VERSION ""

NS_ :

BS_:

BU_: IVI_IF IC HUD MFW ECALL ALC VAP EPA GW_IF

BO_ 3221225472 VECTOR__INDEPENDENT_SIG_MSG: 0 Vector__XXX
 SG_ vcu_VehicleMode : 0|2@1+ (1,0) [0|3] "" Vector__XXX

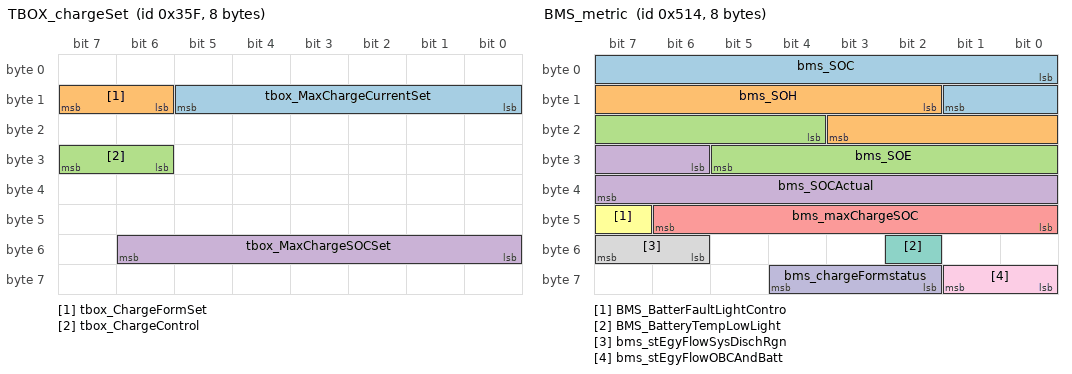
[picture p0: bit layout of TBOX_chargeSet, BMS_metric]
BO_ 863 TBOX_chargeSet: 8 IVI_IF
 SG_ tbox_MaxChargeCurrentSet : 8|6@1+ (1,5) [5|67] "A"  GW_IF
 SG_ tbox_ChargeFormSet : 14|2@1+ (1,0) [0|3] ""  GW_IF
 SG_ tbox_ChargeControl : 30|2@1+ (1,0) [0|3] ""  GW_IF
 SG_ tbox_MaxChargeSOCSet : 48|7@1+ (1,0) [0|100] "%"  GW_IF

BO_ 1300 BMS_metric: 8 GW_IF
 SG_ bms_SOC : 0|10@1+ (0.1,0) [0|100] "%"  IVI_IF
 SG_ bms_SOH : 10|10@1+ (0.1,0) [0|100] "%"  IVI_IF
 SG_ bms_SOE : 20|10@1+ (0.1,0) [0|100] "%"  IVI_IF
 SG_ bms_SOCActual : 30|10@1+ (0.1,0) [0|100] "%"  IVI_IF
 SG_ bms_maxChargeSOC : 40|7@1+ (1,0) [0|100] ""  IVI_IF
 SG_ BMS_BatterFaultLightContro : 47|1@1+ (1,0) [0|1] ""  IVI_IF
 SG_ BMS_BatteryTempLowLight : 50|1@1+ (1,0) [0|1] ""  IVI_IF
 SG_ bms_stEgyFlowSysDischRgn : 54|2@1+ (1,0) [0|3] ""  IVI_IF
 SG_ bms_stEgyFlowOBCAndBatt : 56|2@1+ (1,0) [0|3] ""  IVI_IF
 SG_ bms_chargeFormstatus : 58|3@1+ (1,0) [0|7] ""  IVI_IF

BO_ 1396 BMS_tboxRequest: 8 GW_IF
 SG_ bms_remainChargeTime : 43|12@1+ (1,0) [0|4095] ""  IVI_IF
 SG_ bms_ChgAmount : 55|9@1+ (0.2,0) [0|102.2] "kWh"  IVI_IF

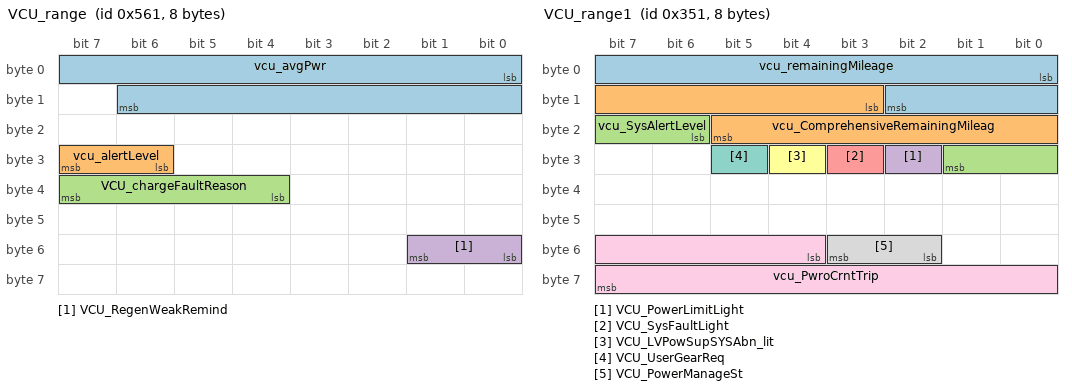
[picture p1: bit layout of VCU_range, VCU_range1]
BO_ 1377 VCU_range: 8 GW_IF
 SG_ vcu_avgPwr : 0|15@1+ (0.01,-100) [-100|100] "KWh/100km"  IVI_IF
 SG_ vcu_alertLevel : 30|2@1+ (1,0) [0|3] ""  IVI_IF
 SG_ VCU_chargeFaultReason : 36|4@1+ (1,0) [0|15] ""  IVI_IF
 SG_ VCU_RegenWeakRemind : 48|2@1+ (1,0) [0|3] ""  IVI_IF

BO_ 849 VCU_range1: 8 GW_IF
 SG_ vcu_remainingMileage : 0|11@1+ (1,0) [0|2047] "km"  IVI_IF
 SG_ vcu_ComprehensiveRemainingMileag : 11|11@1+ (1,0) [0|2047] "km"  IVI_IF
 SG_ vcu_SysAlertLevel : 22|4@1+ (1,0) [0|15] ""  IVI_IF
 SG_ VCU_PowerLimitLight : 26|1@1+ (1,0) [0|1] ""  IVI_IF
 SG_ VCU_SysFaultLight : 27|1@1+ (1,0) [0|1] ""  IVI_IF
 SG_ VCU_LVPowSupSYSAbn_lit : 28|1@1+ (1,0) [0|1] ""  IVI_IF
 SG_ VCU_UserGearReq : 29|1@1+ (1,0) [0|1] ""  IVI_IF
 SG_ VCU_PowerManageSt : 50|2@1+ (1,0) [0|3] ""  IVI_IF
 SG_ vcu_PwroCrntTrip : 52|12@1+ (0.1,-50) [-50|359.5] "kWh"  IVI_IF

BO_ 273 VCU_state: 8 GW_IF
 SG_ vcu_accelPos : 20|10@1+ (0.1,0) [0|100] "%"  IVI_IF,EPA
 SG_ vcu_BrakeWarning : 39|1@1+ (1,0) [0|1] ""  IVI_IF

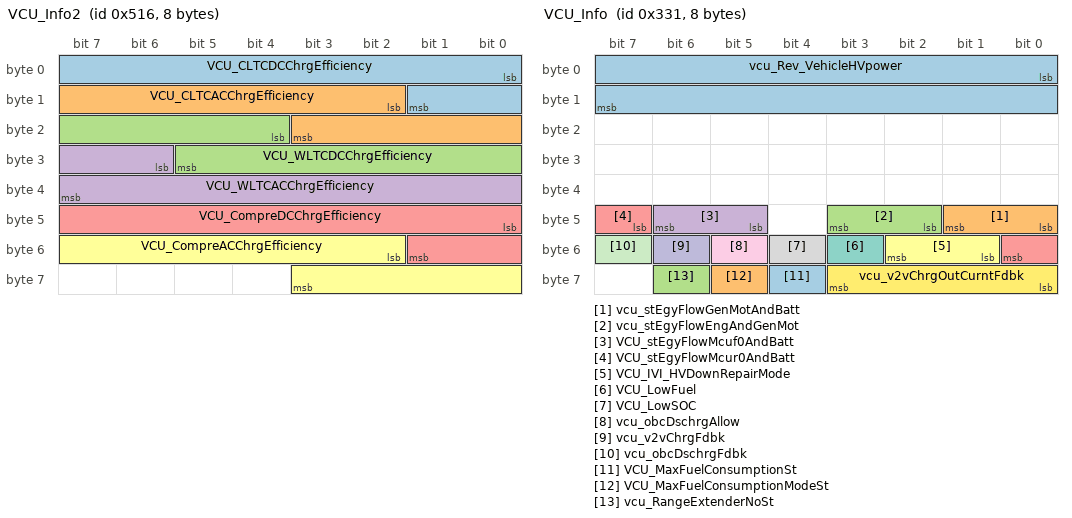
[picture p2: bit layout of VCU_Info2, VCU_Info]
BO_ 1302 VCU_Info2: 8 GW_IF
 SG_ VCU_CLTCDCChrgEfficiency : 0|10@1+ (0.1,0) [0|102.3] "km/min"  IVI_IF
 SG_ VCU_CLTCACChrgEfficiency : 10|10@1+ (0.1,0) [0|102.3] "km/h"  IVI_IF
 SG_ VCU_WLTCDCChrgEfficiency : 20|10@1+ (0.1,0) [0|102.3] "km/min"  IVI_IF
 SG_ VCU_WLTCACChrgEfficiency : 30|10@1+ (0.1,0) [0|102.3] "km/h"  IVI_IF
 SG_ VCU_CompreDCChrgEfficiency : 40|10@1+ (0.1,0) [0|102.3] "km/min"  IVI_IF
 SG_ VCU_CompreACChrgEfficiency : 50|10@1+ (0.1,0) [0|102.3] "km/h"  IVI_IF

BO_ 903 OBC_state: 8 GW_IF
 SG_ obc_state : 8|4@1+ (1,0) [0|15] ""  IVI_IF
 SG_ obc_batteryConnectStatus_ : 13|1@1+ (1,0) [0|1] ""  IVI_IF
 SG_ obc_CcResistance : 14|4@1+ (1,0) [0|15] ""  IVI_IF

BO_ 909 DCDC_state: 8 GW_IF
 SG_ dcdc_systemStatus : 8|4@1+ (1,0) [0|15] ""  IVI_IF
 SG_ dcdc_deratingStatus : 12|1@1+ (1,0) [0|1] ""  IVI_IF
 SG_ dcdc_realOutputCurrent : 32|12@1+ (0.1,0) [0|409.5] "A"  IVI_IF

BO_ 777 GSM_state: 8 GW_IF
 SG_ gsm_NoticeReq : 0|1@1+ (1,0) [0|1] ""  IVI_IF
 SG_ gsm_gearSelectorPos : 1|3@1+ (1,0) [0|7] ""  IVI_IF

BO_ 906 GTW_mcur0_mcuf0_info: 8 GW_IF
 SG_ mcuf0_torqueEst : 12|12@1- (0.8,0) [-1300|1300] "Nm"  IVI_IF
 SG_ mcur0_torqueEst : 0|12@1- (0.8,0) [-1300|1300] "Nm"  IVI_IF

BO_ 772 BMS_temperature: 8 GW_IF
 SG_ bms_packTempMax : 0|9@1+ (0.5,-40) [-40|125] "℃"  IVI_IF
 SG_ bms_packTempMin : 9|9@1+ (0.5,-40) [-40|125] "℃"  IVI_IF
 SG_ bms_packTempAvg : 18|9@1+ (0.5,-40) [-40|125] "℃"  IVI_IF

BO_ 817 VCU_Info: 8 GW_IF
 SG_ vcu_Rev_VehicleHVpower : 0|16@1+ (1,0) [0|20000] ""  IVI_IF
 SG_ vcu_stEgyFlowGenMotAndBatt : 40|2@1+ (1,0) [0|3] ""  IVI_IF
 SG_ vcu_stEgyFlowEngAndGenMot : 42|2@1+ (1,0) [0|3] ""  IVI_IF
 SG_ VCU_stEgyFlowMcuf0AndBatt : 45|2@1+ (1,0) [0|3] ""  IVI_IF
 SG_ VCU_stEgyFlowMcur0AndBatt : 47|2@1+ (1,0) [0|3] ""  IVI_IF
 SG_ VCU_IVI_HVDownRepairMode : 49|2@1+ (1,0) [0|3] ""  IVI_IF
 SG_ VCU_LowFuel : 51|1@1+ (1,0) [0|1] ""  IVI_IF
 SG_ VCU_LowSOC : 52|1@1+ (1,0) [0|1] ""  IVI_IF
 SG_ vcu_obcDschrgAllow : 53|1@1+ (1,0) [0|1] ""  IVI_IF
 SG_ vcu_v2vChrgFdbk : 54|1@1+ (1,0) [0|1] ""  IVI_IF
 SG_ vcu_obcDschrgFdbk : 55|1@1+ (1,0) [0|1] ""  IVI_IF
 SG_ vcu_v2vChrgOutCurntFdbk : 56|4@1+ (1,0) [0|15] "A"  IVI_IF
 SG_ VCU_MaxFuelConsumptionSt : 60|1@1+ (1,0) [0|1] ""  IVI_IF
 SG_ VCU_MaxFuelConsumptionModeSt : 61|1@1+ (1,0) [0|1] ""  IVI_IF
 SG_ vcu_RangeExtenderNoSt : 62|1@1+ (1,0) [0|1] ""  IVI_IF

BO_ 2015 Diag_FuncReq: 8 GW_IF
 SG_ Diag_FuncReq_Data : 0|64@1+ (1,0) [0|0] "N/A"  IVI_IF,IC,HUD,MFW,ECALL,ALC,EPA

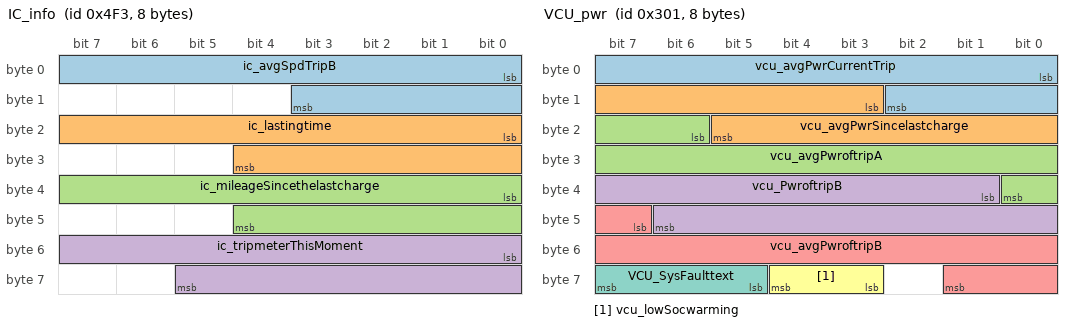
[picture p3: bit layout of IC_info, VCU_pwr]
BO_ 1267 IC_info: 8 IVI_IF
 SG_ ic_avgSpdTripB : 0|12@1+ (0.1,0) [0|280] "KPH"  GW_IF
 SG_ ic_lastingtime : 16|13@1+ (1,0) [0|4320] "min"  GW_IF
 SG_ ic_mileageSincethelastcharge : 32|13@1+ (0.1,0) [0|800] "km"  GW_IF
 SG_ ic_tripmeterThisMoment : 48|14@1+ (0.1,0) [0|1500] "km"  GW_IF

BO_ 769 VCU_pwr: 8 GW_IF
 SG_ vcu_avgPwrCurrentTrip : 0|11@1+ (0.1,-50) [-50|154.7] "kWh/100km"  IVI_IF
 SG_ vcu_avgPwrSincelastcharge : 11|11@1+ (0.1,-50) [-50|154.7] "kWh/100km"  IVI_IF
 SG_ vcu_avgPwroftripA : 22|11@1+ (0.1,-50) [-50|154.7] "kWh/100km"  IVI_IF
 SG_ vcu_PwroftripB : 33|14@1+ (0.1,-500) [-500|1000] "kWh"  IVI_IF
 SG_ vcu_avgPwroftripB : 47|11@1+ (0.1,-50) [-50|154.7] "kWh/100km"  IVI_IF
 SG_ vcu_lowSocwarming : 59|2@1+ (1,0) [0|3] ""  IVI_IF
 SG_ VCU_SysFaulttext : 61|3@1+ (1,0) [0|7] ""  IVI_IF

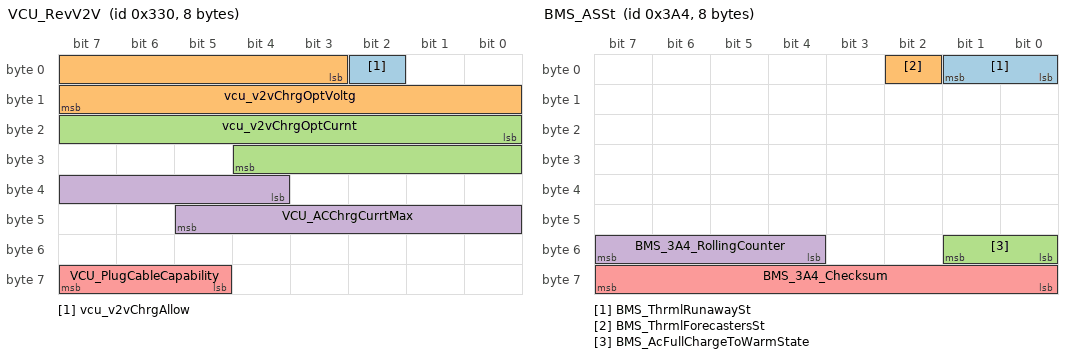
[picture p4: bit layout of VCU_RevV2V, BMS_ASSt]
BO_ 816 VCU_RevV2V: 8 GW_IF
 SG_ vcu_v2vChrgAllow : 2|1@1+ (1,0) [0|1] ""  IVI_IF
 SG_ vcu_v2vChrgOptVoltg : 3|13@1+ (0.1,0) [0|800] "V"  IVI_IF
 SG_ vcu_v2vChrgOptCurnt : 16|13@1+ (0.1,-400) [-400|400] "A"  IVI_IF
 SG_ VCU_ACChrgCurrtMax : 36|10@1+ (0.1,0) [0|63] "A"  IVI_IF
 SG_ VCU_PlugCableCapability : 61|3@1+ (1,0) [0|7] ""  IVI_IF

BO_ 932 BMS_ASSt: 8 GW_IF
 SG_ BMS_ThrmlRunawaySt : 0|2@1+ (1,0) [0|3] ""  IVI_IF,IC
 SG_ BMS_ThrmlForecastersSt : 2|1@1+ (1,0) [0|3] ""  IVI_IF
 SG_ BMS_AcFullChargeToWarmState : 48|2@1+ (1,0) [0|3] ""  IVI_IF
 SG_ BMS_3A4_RollingCounter : 52|4@1+ (1,0) [0|15] ""  IVI_IF
 SG_ BMS_3A4_Checksum : 56|8@1+ (1,0) [0|255] ""  IVI_IF

BO_ 929 VCU_stateCha1: 8 GW_IF
 SG_ vcu_driveMode : 0|3@1+ (1,0) [0|7] ""  IVI_IF,HUD,ALC
 SG_ vcu_VehicleMode : 3|3@1+ (1,0) [0|7] ""  IVI_IF
 SG_ VCU_PercentInstantaneousPower : 9|8@1+ (1,-100) [-100|100] ""  IVI_IF,EPA
 SG_ Vcu_ParkingChargeFB : 23|1@1+ (1,0) [0|1] ""  IVI_IF
 SG_ Vcu_ParkingChargeModFB : 24|2@1+ (1,0) [0|3] ""  IVI_IF
 SG_ vcu_towMode : 26|2@1+ (1,0) [0|3] ""  IVI_IF
 SG_ vcu_ready : 28|1@1+ (1,0) [0|1] ""  IVI_IF
 SG_ vcu_traveModeSts : 29|2@1+ (1,0) [0|3] ""  IVI_IF
 SG_ vcu_highVoltagefaultSts : 31|1@1+ (1,0) [0|1] ""  IVI_IF
 SG_ VCU_VehicleRepairModeFB : 32|2@1+ (1,0) [0|3] ""  IVI_IF
 SG_ VCU_VehicleModeSetReq : 34|3@1+ (1,0) [0|7] ""  IVI_IF
 SG_ VCU_VehicleModeLOWTempReq : 37|2@1+ (1,0) [0|3] ""  IVI_IF
 SG_ VCU_RangeExtenderSt : 40|2@1+ (1,0) [0|3] ""  IVI_IF
 SG_ vcu_highVoltageSuccess : 42|3@1+ (1,0) [0|7] ""  IVI_IF,MFW
 SG_ vcu_hvOnMode : 48|2@1+ (1,0) [0|3] ""  IVI_IF
 SG_ vcu_RegenModeStatus : 52|2@1+ (1,0) [0|3] ""  IVI_IF
 SG_ vcu_memoryStatus : 55|1@1+ (1,0) [0|1] ""  IVI_IF
 SG_ VCU_Eng_SelfShieldStart : 56|1@1+ (1,0) [0|1] ""  IVI_IF
 SG_ VCU_ExhibitionRequest : 57|1@1+ (1,0) [0|1] ""  IVI_IF
 SG_ vcu_ExhibitionMode : 61|2@1+ (1,0) [0|3] ""  IVI_IF,MFW

BO_ 292 EPS_state: 8 GW_IF
 SG_ eps_warningLamp : 20|1@1+ (1,0) [0|1] ""  IVI_IF,IC
 SG_ eps_rollingCounter : 52|4@1+ (1,0) [0|15] ""  IVI_IF
 SG_ eps_checksum : 56|8@1+ (1,0) [0|255] ""  IVI_IF

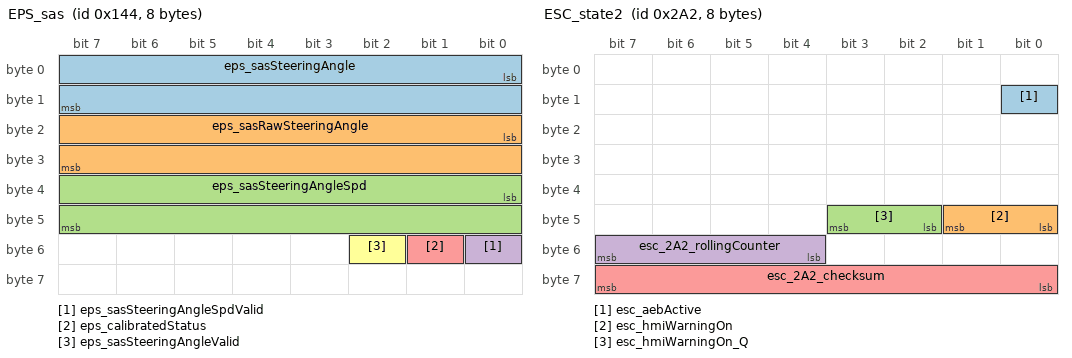
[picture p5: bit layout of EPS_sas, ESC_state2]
BO_ 324 EPS_sas: 8 GW_IF
 SG_ eps_sasSteeringAngle : 0|16@1+ (0.1,-780) [-780|779.9] "deg"  IVI_IF
 SG_ eps_sasRawSteeringAngle : 16|16@1+ (0.1,-780) [-780|779.9] "deg"  IVI_IF
 SG_ eps_sasSteeringAngleSpd : 32|16@1+ (0.1,-1300) [-1300|1300] "deg/s"  IVI_IF
 SG_ eps_sasSteeringAngleSpdValid : 48|1@1+ (1,0) [0|1] ""  IVI_IF
 SG_ eps_calibratedStatus : 49|1@1+ (1,0) [0|1] ""  IVI_IF
 SG_ eps_sasSteeringAngleValid : 50|1@1+ (1,0) [0|1] ""  IVI_IF

BO_ 322 ESC_wheelSpd_Front: 8 GW_IF
 SG_ esc_wheelSpeedFL : 0|13@1+ (0.05625,0) [0|270] "km/h"  IVI_IF
 SG_ esc_wheelSpeedFLValid : 13|1@1+ (1,0) [0|1] ""  IVI_IF
 SG_ esc_wheelSpeedFR : 16|13@1+ (0.05625,0) [0|270] "km/h"  IVI_IF
 SG_ esc_wheelSpeedFRValid : 29|1@1+ (1,0) [0|1] ""  IVI_IF

BO_ 290 ESC_wheelSpd_Rear: 8 GW_IF
 SG_ esc_wheelSpeedRL : 0|13@1+ (0.05625,0) [0|270] "km/h"  IVI_IF
 SG_ esc_wheelSpeedRLValid : 13|1@1+ (1,0) [0|1] ""  IVI_IF
 SG_ esc_wheelSpeedRR : 16|13@1+ (0.05625,0) [0|270] "km/h"  IVI_IF
 SG_ esc_wheelSpeedRRValid : 29|1@1+ (1,0) [0|1] ""  IVI_IF

BO_ 530 ESC_state1: 8 GW_IF
 SG_ esc_vehicleSpeed : 0|13@1+ (0.05625,0) [0|270] "km/h"  IVI_IF
 SG_ esc_vehicleSpeedValid : 13|1@1+ (1,0) [0|1] ""  IVI_IF
 SG_ esc_absFault : 14|1@1+ (1,0) [0|1] ""  IVI_IF,IC
 SG_ esc_absActive : 15|1@1+ (1,0) [0|1] ""  IVI_IF
 SG_ esc_escActive : 17|1@1+ (1,0) [0|1] ""  IVI_IF
 SG_ esc_tcsActive : 18|1@1+ (1,0) [0|1] ""  IVI_IF
 SG_ esc_avhActive : 22|1@1+ (1,0) [0|1] ""  IVI_IF
 SG_ esc_avhStandby : 23|1@1+ (1,0) [0|1] ""  IVI_IF
 SG_ esc_avhAvailable : 24|1@1+ (1,0) [0|1] ""  IVI_IF
 SG_ esc_cdpActive : 25|1@1+ (1,0) [0|1] ""  IVI_IF
 SG_ esc_hdcStatus : 27|2@1+ (1,0) [0|3] ""  IVI_IF
 SG_ esc_hdcAvailable : 29|1@1+ (1,0) [0|1] ""  IVI_IF
 SG_ esc_hhcAvailable : 31|1@1+ (1,0) [0|1] ""  IVI_IF
 SG_ esc_ebdFault : 46|1@1+ (1,0) [0|1] ""  IVI_IF,IC
 SG_ esc_offStatus : 47|1@1+ (1,0) [0|1] ""  IVI_IF,IC
 SG_ esc_escFault : 48|1@1+ (1,0) [0|1] ""  IVI_IF,IC
 SG_ esc_emergencyBrakeSts : 49|1@1+ (1,0) [0|1] ""  IVI_IF
 SG_ esc_212_rollingCounter : 52|4@1+ (1,0) [0|15] ""  IVI_IF
 SG_ esc_212_checksum : 56|8@1+ (1,0) [0|255] ""  IVI_IF

BO_ 674 ESC_state2: 8 GW_IF
 SG_ esc_aebActive : 8|1@1+ (1,0) [0|1] ""  IVI_IF
 SG_ esc_hmiWarningOn : 40|2@1+ (1,0) [0|3] ""  IVI_IF
 SG_ esc_hmiWarningOn_Q : 42|2@1+ (1,0) [0|3] ""  IVI_IF
 SG_ esc_2A2_rollingCounter : 52|4@1+ (1,0) [0|15] ""  IVI_IF
 SG_ esc_2A2_checksum : 56|8@1+ (1,0) [0|255] ""  IVI_IF

BO_ 594 ESC_yawState: 8 GW_IF
 SG_ esc_longAcceleration : 0|13@1+ (0.01,-21) [-21|21] "m/s2"  IVI_IF
 SG_ esc_longAccelerationValid : 13|1@1+ (1,0) [0|1] ""  IVI_IF
 SG_ esc_yawRateValid : 15|1@1+ (1,0) [0|1] ""  IVI_IF
 SG_ esc_yawRate : 32|16@1+ (0.005,-163.84) [-163.84|163.835] "degree/s"  IVI_IF

BO_ 1019 GW_ESC_yawState: 8 GW_IF
 SG_ apa_funcSts : 55|3@1+ (1,0) [0|7] ""  IVI_IF

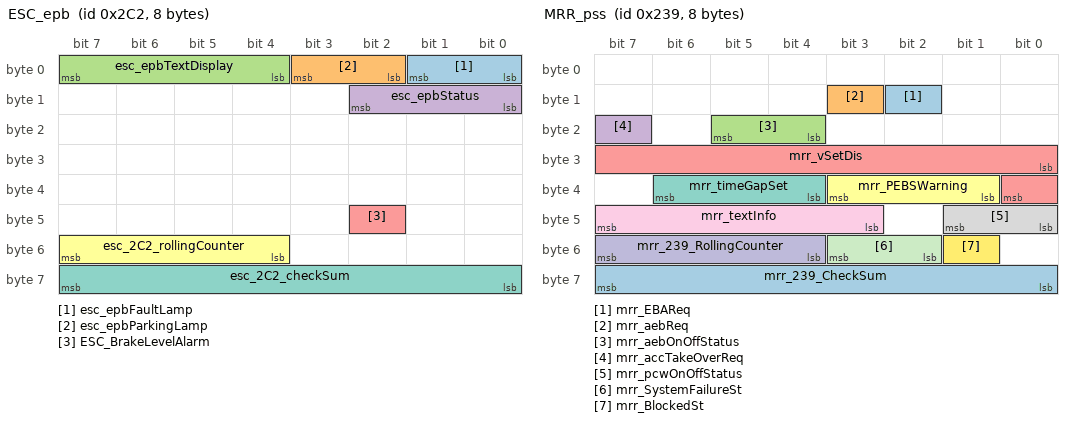
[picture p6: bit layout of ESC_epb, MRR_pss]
BO_ 706 ESC_epb: 8 GW_IF
 SG_ esc_epbFaultLamp : 0|2@1+ (1,0) [0|3] ""  IVI_IF,IC
 SG_ esc_epbParkingLamp : 2|2@1+ (1,0) [0|3] ""  IVI_IF,IC
 SG_ esc_epbTextDisplay : 4|4@1+ (1,0) [0|15] ""  IVI_IF
 SG_ esc_epbStatus : 8|3@1+ (1,0) [0|7] ""  IVI_IF
 SG_ ESC_BrakeLevelAlarm : 42|1@1+ (1,0) [0|1] ""  IVI_IF,IC
 SG_ esc_2C2_rollingCounter : 52|4@1+ (1,0) [0|15] ""  IVI_IF
 SG_ esc_2C2_checkSum : 56|8@1+ (1,0) [0|255] "N/A"  IVI_IF

BO_ 537 MRR_acc: 8 GW_IF
 SG_ mrr_accMode : 45|3@1+ (1,0) [0|7] ""  IVI_IF,HUD
 SG_ mrr_219_RollingCounter : 52|4@1+ (1,0) [0|15] ""  IVI_IF
 SG_ mrr_219_CheckSum : 56|8@1+ (1,0) [0|255] "N/A"  IVI_IF

BO_ 569 MRR_pss: 8 GW_IF
 SG_ mrr_EBAReq : 10|1@1+ (1,0) [0|1] ""  IVI_IF
 SG_ mrr_aebReq : 11|1@1+ (1,0) [0|1] ""  IVI_IF,HUD
 SG_ mrr_aebOnOffStatus : 20|2@1+ (1,0) [0|3] ""  IVI_IF
 SG_ mrr_accTakeOverReq : 23|1@1+ (1,0) [0|1] ""  IVI_IF,IC,HUD,ALC
 SG_ mrr_vSetDis : 24|9@1+ (0.5,0) [0|255.5] "KPH"  IVI_IF,HUD
 SG_ mrr_PEBSWarning : 33|3@1+ (1,0) [0|7] ""  IVI_IF,HUD,ALC
 SG_ mrr_timeGapSet : 36|3@1+ (1,0) [0|7] ""  IVI_IF,HUD
 SG_ mrr_pcwOnOffStatus : 40|2@1+ (1,0) [0|3] ""  IVI_IF
 SG_ mrr_textInfo : 43|5@1+ (1,0) [0|15] ""  IVI_IF
 SG_ mrr_239_RollingCounter : 52|4@1+ (1,0) [0|15] ""  IVI_IF
 SG_ mrr_SystemFailureSt : 50|2@1+ (1,0) [0|3] ""  IVI_IF
 SG_ mrr_BlockedSt : 49|1@1+ (1,0) [0|1] ""  IVI_IF
 SG_ mrr_239_CheckSum : 56|8@1+ (1,0) [0|255] "N/A"  IVI_IF

BO_ 841 MRR_hmi1: 8 GW_IF
 SG_ mrr_ACC_TargetType : 0|3@1+ (1,0) [0|7] ""  IVI_IF,HUD
 SG_ mrr_ACC_TargetDetection : 4|3@1+ (1,0) [0|7] ""  IVI_IF,HUD
 SG_ mrr_ACC_TargetRange : 7|9@1+ (0.5,0) [0|250] "m"  IVI_IF
 SG_ mrr_ACC_RelevantTargetLatRange : 16|10@1+ (0.1,-50) [-50|50] "m"  IVI_IF

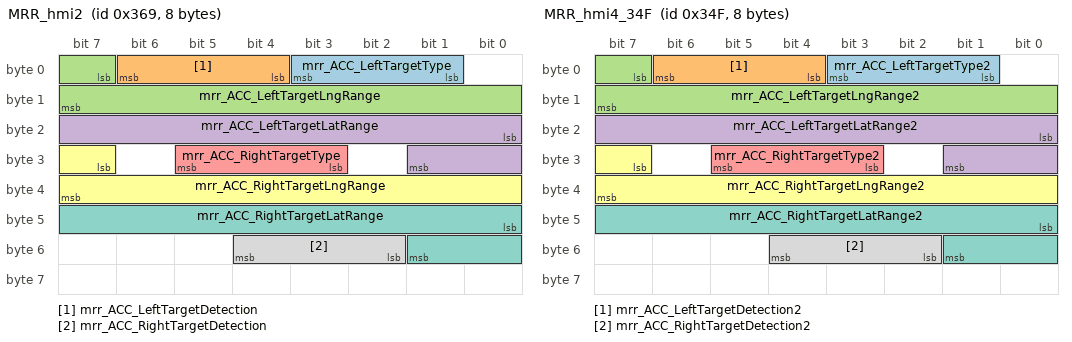
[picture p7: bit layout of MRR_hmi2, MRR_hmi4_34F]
BO_ 873 MRR_hmi2: 8 GW_IF
 SG_ mrr_ACC_LeftTargetType : 1|3@1+ (1,0) [0|7] ""  IVI_IF
 SG_ mrr_ACC_LeftTargetDetection : 4|3@1+ (1,0) [0|7] ""  IVI_IF
 SG_ mrr_ACC_LeftTargetLngRange : 7|9@1+ (0.5,0) [0|250] "m"  IVI_IF
 SG_ mrr_ACC_LeftTargetLatRange : 16|10@1+ (0.1,-50) [-50|50] "m"  IVI_IF
 SG_ mrr_ACC_RightTargetType : 27|3@1+ (1,0) [0|7] ""  IVI_IF
 SG_ mrr_ACC_RightTargetLngRange : 31|9@1+ (0.5,0) [0|250] "m"  IVI_IF
 SG_ mrr_ACC_RightTargetLatRange : 40|10@1+ (0.1,-50) [-50|50] "m"  IVI_IF
 SG_ mrr_ACC_RightTargetDetection : 50|3@1+ (1,0) [0|7] ""  IVI_IF

BO_ 846 MRR_hmi3_34E: 8 GW_IF
 SG_ mrr_ACC_TargetType2 : 0|3@1+ (1,0) [0|7] ""  IVI_IF
 SG_ mrr_ACC_TargetDetection2 : 3|3@1+ (1,0) [0|7] ""  IVI_IF
 SG_ mrr_ACC_TargetRange2 : 7|9@1+ (0.5,0) [0|250] "m"  IVI_IF
 SG_ mrr_ACC_RelevantTargetLatRange2 : 16|10@1+ (0.1,-50) [-50|50] "m"  IVI_IF

BO_ 847 MRR_hmi4_34F: 8 GW_IF
 SG_ mrr_ACC_LeftTargetType2 : 1|3@1+ (1,0) [0|7] ""  IVI_IF
 SG_ mrr_ACC_LeftTargetDetection2 : 4|3@1+ (1,0) [0|7] ""  IVI_IF
 SG_ mrr_ACC_LeftTargetLngRange2 : 7|9@1+ (0.5,0) [0|250] "m"  IVI_IF
 SG_ mrr_ACC_LeftTargetLatRange2 : 16|10@1+ (0.1,-50) [-50|50] "m"  IVI_IF
 SG_ mrr_ACC_RightTargetType2 : 27|3@1+ (1,0) [0|7] ""  IVI_IF
 SG_ mrr_ACC_RightTargetLngRange2 : 31|9@1+ (0.5,0) [0|250] "m"  IVI_IF
 SG_ mrr_ACC_RightTargetLatRange2 : 40|10@1+ (0.1,-50) [-50|50] "m"  IVI_IF
 SG_ mrr_ACC_RightTargetDetection2 : 50|3@1+ (1,0) [0|7] ""  IVI_IF

BO_ 853 MRR_hmi5_355: 8 GW_IF
 SG_ mrr_ACC_TargetType3 : 0|3@1+ (1,0) [0|7] ""  IVI_IF,HUD
 SG_ mrr_ACC_TargetDetection3 : 3|3@1+ (1,0) [0|7] ""  IVI_IF,HUD
 SG_ mrr_ACC_TargetRange3 : 7|9@1+ (0.5,0) [0|250] "m"  IVI_IF
 SG_ mrr_ACC_RelevantTargetLatRange3 : 16|10@1+ (0.1,-50) [-50|50] "m"  IVI_IF

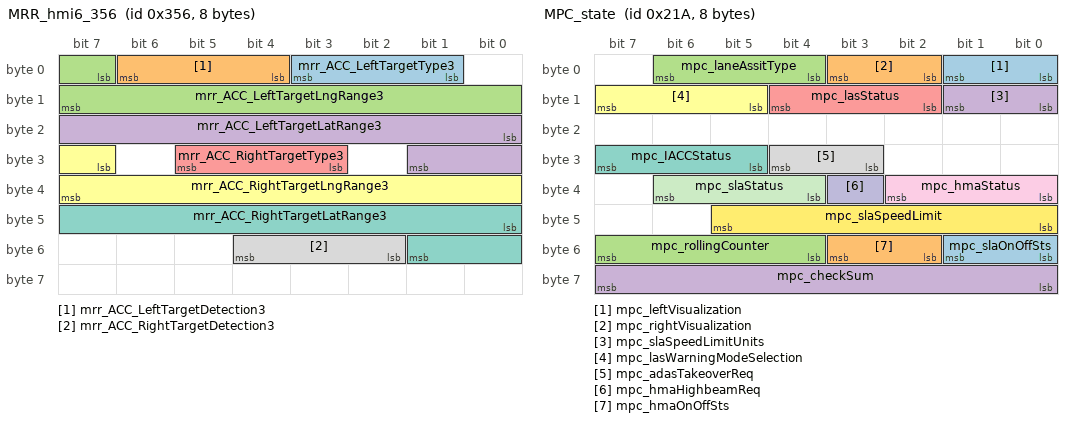
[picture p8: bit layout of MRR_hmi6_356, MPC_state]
BO_ 854 MRR_hmi6_356: 8 GW_IF
 SG_ mrr_ACC_LeftTargetType3 : 1|3@1+ (1,0) [0|7] ""  IVI_IF
 SG_ mrr_ACC_LeftTargetDetection3 : 4|3@1+ (1,0) [0|7] ""  IVI_IF
 SG_ mrr_ACC_LeftTargetLngRange3 : 7|9@1+ (0.5,0) [0|250] "m"  IVI_IF
 SG_ mrr_ACC_LeftTargetLatRange3 : 16|10@1+ (0.1,-50) [-50|50] "m"  IVI_IF
 SG_ mrr_ACC_RightTargetType3 : 27|3@1+ (1,0) [0|7] ""  IVI_IF
 SG_ mrr_ACC_RightTargetLngRange3 : 31|9@1+ (0.5,0) [0|250] "m"  IVI_IF
 SG_ mrr_ACC_RightTargetLatRange3 : 40|10@1+ (0.1,-50) [-50|50] "m"  IVI_IF
 SG_ mrr_ACC_RightTargetDetection3 : 50|3@1+ (1,0) [0|7] ""  IVI_IF

BO_ 538 MPC_state: 8 GW_IF
 SG_ mpc_leftVisualization : 0|2@1+ (1,0) [0|3] ""  IVI_IF,HUD
 SG_ mpc_rightVisualization : 2|2@1+ (1,0) [0|3] ""  IVI_IF,HUD
 SG_ mpc_laneAssitType : 4|3@1+ (1,0) [0|7] ""  IVI_IF,HUD
 SG_ mpc_slaSpeedLimitUnits : 8|2@1+ (1,0) [0|3] ""  IVI_IF
 SG_ mpc_lasStatus : 10|3@1+ (1,0) [0|7] ""  IVI_IF,HUD
 SG_ mpc_lasWarningModeSelection : 13|3@1+ (1,0) [0|7] ""  IVI_IF
 SG_ mpc_IACCStatus : 29|3@1+ (1,0) [0|7] ""  IVI_IF,HUD
 SG_ mpc_adasTakeoverReq : 27|2@1+ (1,0) [0|3] ""  IVI_IF,IC,HUD,ALC
 SG_ mpc_hmaStatus : 32|3@1+ (1,0) [0|7] ""  IVI_IF
 SG_ mpc_hmaHighbeamReq : 35|1@1+ (1,0) [0|1] ""  IVI_IF
 SG_ mpc_slaStatus : 36|3@1+ (1,0) [0|7] ""  IVI_IF
 SG_ mpc_slaSpeedLimit : 40|6@1+ (5,0) [0|315] ""  IVI_IF,HUD
 SG_ mpc_slaOnOffSts : 48|2@1+ (1,0) [0|3] ""  IVI_IF
 SG_ mpc_hmaOnOffSts : 50|2@1+ (1,0) [0|3] ""  IVI_IF
 SG_ mpc_rollingCounter : 52|4@1+ (1,0) [0|15] ""  IVI_IF
 SG_ mpc_checkSum : 56|8@1+ (1,0) [0|255] "N/A"  IVI_IF

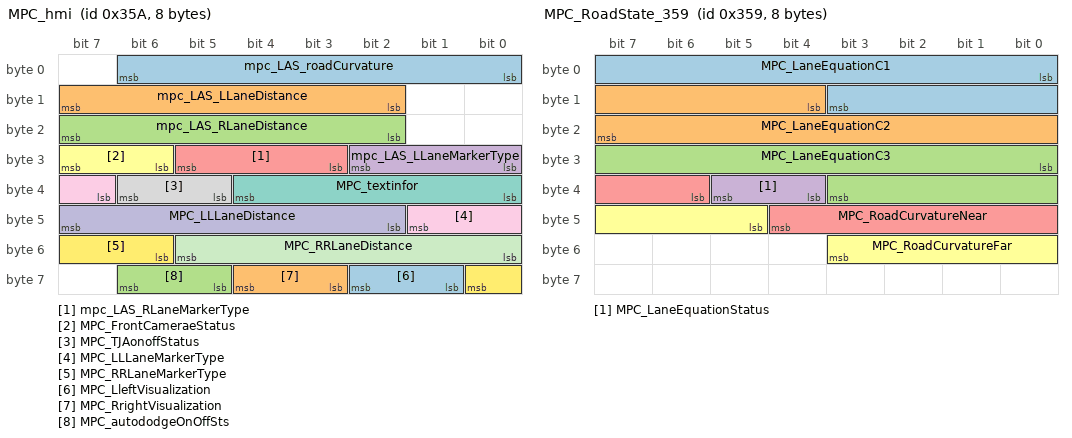
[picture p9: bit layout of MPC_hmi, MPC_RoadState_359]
BO_ 858 MPC_hmi: 8 GW_IF
 SG_ mpc_LAS_roadCurvature : 0|7@1+ (0.0005,-0.03) [-0.03|0.03] ""  IVI_IF
 SG_ mpc_LAS_LLaneDistance : 10|6@1+ (0.1,-1) [-1|5] "m"  IVI_IF
 SG_ mpc_LAS_RLaneDistance : 18|6@1+ (0.1,-1) [-1|5] "m"  IVI_IF
 SG_ mpc_LAS_LLaneMarkerType : 24|3@1+ (1,0) [0|7] ""  IVI_IF,HUD
 SG_ mpc_LAS_RLaneMarkerType : 27|3@1+ (1,0) [0|7] ""  IVI_IF,HUD
 SG_ MPC_FrontCameraeStatus : 30|2@1+ (1,0) [0|3] ""  IVI_IF
 SG_ MPC_textinfor : 32|5@1+ (1,0) [0|31] ""  IVI_IF,HUD
 SG_ MPC_TJAonoffStatus : 37|2@1+ (1,0) [0|3] ""  IVI_IF
 SG_ MPC_LLLaneMarkerType : 39|3@1+ (1,0) [0|7] ""  IVI_IF
 SG_ MPC_LLLaneDistance : 42|6@1+ (0.2,0) [0|12] "m"  IVI_IF
 SG_ MPC_RRLaneDistance : 48|6@1+ (0.2,0) [0|12] "m"  IVI_IF
 SG_ MPC_RRLaneMarkerType : 54|3@1+ (1,0) [0|7] ""  IVI_IF
 SG_ MPC_LleftVisualization : 57|2@1+ (1,0) [0|3] ""  IVI_IF
 SG_ MPC_RrightVisualization : 59|2@1+ (1,0) [0|3] ""  IVI_IF
 SG_ MPC_autododgeOnOffSts : 61|2@1+ (1,0) [0|3] ""  IVI_IF

BO_ 857 MPC_RoadState_359: 8 GW_IF
 SG_ MPC_LaneEquationC1 : 0|12@1+ (0.0004883,-1) [-1|0.9991002] "rad"  IVI_IF
 SG_ MPC_LaneEquationC2 : 12|12@1+ (1.526E-005,-0.0312347) [-0.0312347|0.03123974] ""  IVI_IF
 SG_ MPC_LaneEquationC3 : 24|12@1+ (4.768E-007,-0.0009761) [-0.0009761|0.0009759192] ""  IVI_IF
 SG_ MPC_LaneEquationStatus : 36|2@1+ (1,0) [0|3] ""  IVI_IF
 SG_ MPC_RoadCurvatureNear : 38|7@1+ (0.0005,-0.03) [-0.03|0.03] ""  IVI_IF
 SG_ MPC_RoadCurvatureFar : 45|7@1+ (0.0005,-0.03) [-0.03|0.03] ""  IVI_IF

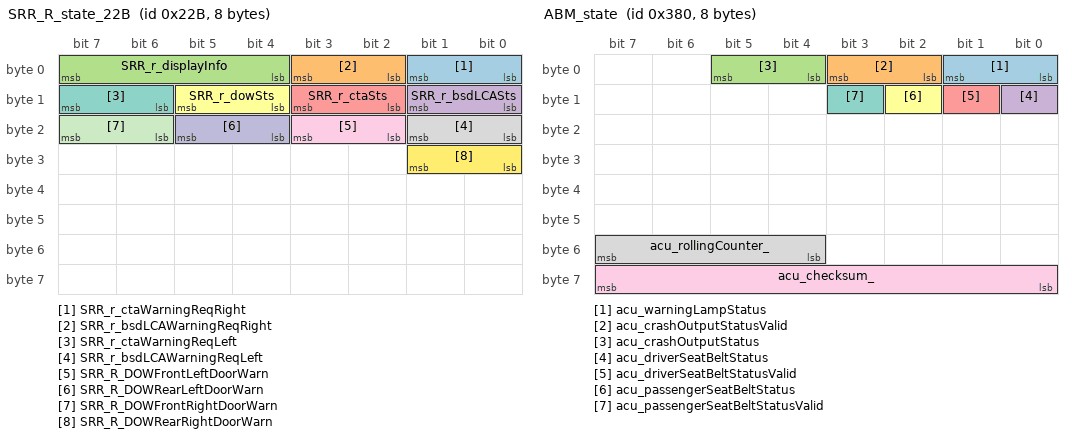
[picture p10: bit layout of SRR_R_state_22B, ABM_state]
BO_ 555 SRR_R_state_22B: 8 GW_IF
 SG_ SRR_r_ctaWarningReqRight : 0|2@1+ (1,0) [0|3] ""  IVI_IF
 SG_ SRR_r_bsdLCAWarningReqRight : 2|2@1+ (1,0) [0|3] ""  IVI_IF,ALC
 SG_ SRR_r_displayInfo : 4|4@1+ (1,0) [0|15] ""  IVI_IF
 SG_ SRR_r_bsdLCASts : 8|2@1+ (1,0) [0|3] ""  IVI_IF
 SG_ SRR_r_ctaSts : 10|2@1+ (1,0) [0|3] ""  IVI_IF
 SG_ SRR_r_dowSts : 12|2@1+ (1,0) [0|3] ""  IVI_IF
 SG_ SRR_r_ctaWarningReqLeft : 14|2@1+ (1,0) [0|3] ""  IVI_IF
 SG_ SRR_r_bsdLCAWarningReqLeft : 16|2@1+ (1,0) [0|3] ""  IVI_IF,ALC
 SG_ SRR_R_DOWFrontLeftDoorWarn : 18|2@1+ (1,0) [0|3] ""  IVI_IF,ALC
 SG_ SRR_R_DOWRearLeftDoorWarn : 20|2@1+ (1,0) [0|3] ""  IVI_IF,ALC
 SG_ SRR_R_DOWFrontRightDoorWarn : 22|2@1+ (1,0) [0|3] ""  IVI_IF,ALC
 SG_ SRR_R_DOWRearRightDoorWarn : 24|2@1+ (1,0) [0|3] ""  IVI_IF,ALC

BO_ 896 ABM_state: 8 GW_IF
 SG_ acu_warningLampStatus : 0|2@1+ (1,0) [0|3] ""  IVI_IF,IC
 SG_ acu_crashOutputStatusValid : 2|2@1+ (1,0) [0|3] ""  IVI_IF,ECALL
 SG_ acu_crashOutputStatus : 4|2@1+ (1,0) [0|3] ""  IVI_IF,ECALL
 SG_ acu_driverSeatBeltStatus : 8|1@1+ (1,0) [0|1] ""  IVI_IF
 SG_ acu_driverSeatBeltStatusValid : 9|1@1+ (1,0) [0|1] ""  IVI_IF
 SG_ acu_passengerSeatBeltStatus : 10|1@1+ (1,0) [0|1] ""  IVI_IF
 SG_ acu_passengerSeatBeltStatusValid : 11|1@1+ (1,0) [0|1] ""  IVI_IF
 SG_ acu_rollingCounter_ : 52|4@1+ (1,0) [0|15] ""  IVI_IF
 SG_ acu_checksum_ : 56|8@1+ (1,0) [0|255] ""  IVI_IF

BO_ 859 APA_35B: 8 GW_IF
 SG_ APA_voice_reminder : 2|3@1+ (1,0) [0|7] ""  IVI_IF
 SG_ APA_textinfo : 5|2@1+ (1,0) [0|3] ""  IVI_IF
 SG_ APA_FinishReason : 51|6@1+ (1,0) [0|63] ""  IVI_IF

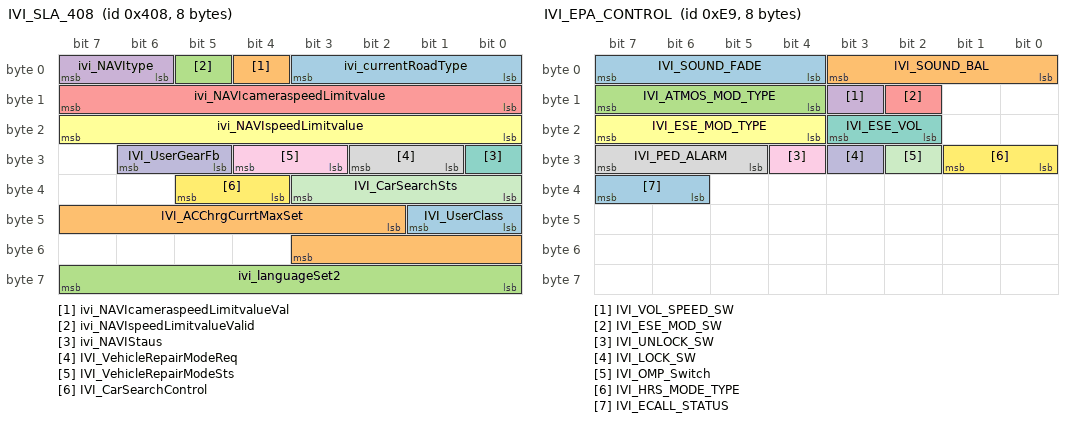
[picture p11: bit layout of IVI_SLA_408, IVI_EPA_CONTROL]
BO_ 1032 IVI_SLA_408: 8 IVI_IF
 SG_ ivi_currentRoadType : 0|4@1+ (1,0) [0|15] ""  GW_IF
 SG_ ivi_NAVIcameraspeedLimitvalueVal : 4|1@1+ (1,0) [0|1] ""  GW_IF
 SG_ ivi_NAVIspeedLimitvalueValid : 5|1@1+ (1,0) [0|1] ""  GW_IF
 SG_ ivi_NAVItype : 6|2@1+ (1,0) [0|3] ""  GW_IF
 SG_ ivi_NAVIcameraspeedLimitvalue : 8|8@1+ (1,0) [0|150] "KPH"  GW_IF
 SG_ ivi_NAVIspeedLimitvalue : 16|8@1+ (1,0) [0|150] "KPH"  GW_IF
 SG_ ivi_NAVIStaus : 24|1@1+ (1,0) [0|1] ""  GW_IF
 SG_ IVI_VehicleRepairModeReq : 25|2@1+ (1,0) [0|3] ""  GW_IF
 SG_ IVI_VehicleRepairModeSts : 27|2@1+ (1,0) [0|3] ""  GW_IF
 SG_ IVI_UserGearFb : 29|2@1+ (1,0) [0|3] ""  GW_IF
 SG_ IVI_CarSearchSts : 32|4@1+ (1,0) [0|15] "" Vector__XXX
 SG_ IVI_CarSearchControl : 36|2@1+ (1,0) [0|3] ""  GW_IF
 SG_ IVI_UserClass : 40|2@1+ (1,0) [0|3] ""  GW_IF
 SG_ IVI_ACChrgCurrtMaxSet : 42|10@1+ (0.1,0) [0|63] ""  GW_IF
 SG_ ivi_languageSet2 : 56|8@1+ (1,0) [0|255] ""  GW_IF

BO_ 230 IVI_EPA_VOL: 8 IVI_IF
 SG_ IVI_CH0_CH1_VOL_STEP : 1|7@1+ (1,0) [0|127] ""  EPA
 SG_ IVI_CH2_VOL_STEP : 9|7@1+ (1,0) [0|127] ""  EPA
 SG_ IVI_CH3_VOL_STEP : 17|7@1+ (1,0) [0|127] ""  EPA
 SG_ IVI_CH4_VOL_STEP : 25|7@1+ (1,0) [0|127] ""  EPA
 SG_ IVI_CH5_VOL_STEP : 33|7@1+ (1,0) [0|127] ""  EPA
 SG_ IVI_CH6_VOL_STEP : 41|7@1+ (1,0) [0|127] ""  EPA
 SG_ IVI_CH7_VOL_STEP : 54|2@1+ (1,0) [0|3] ""  EPA
 SG_ IVI_CH0_CH1_MUTE : 48|1@1+ (1,0) [0|1] ""  EPA
 SG_ IVI_CH2_MUTE : 0|1@1+ (1,0) [0|1] ""  EPA
 SG_ IVI_CH3_MUTE : 8|1@1+ (1,0) [0|1] ""  EPA
 SG_ IVI_CH4_MUTE : 16|1@1+ (1,0) [0|1] ""  EPA
 SG_ IVI_CH5_MUTE : 24|1@1+ (1,0) [0|1] ""  EPA
 SG_ IVI_CH6_MUTE : 32|1@1+ (1,0) [0|1] ""  EPA
 SG_ IVI_CH7_MUTE : 40|1@1+ (1,0) [0|1] ""  EPA
 SG_ IVI_CH8_MUTE : 63|1@1+ (1,0) [0|1] ""  EPA
 SG_ IVI_CH9_MUTE : 62|1@1+ (1,0) [0|1] ""  EPA
 SG_ IVI_CH10_CH15_MUTE : 61|1@1+ (1,0) [0|1] ""  EPA

BO_ 231 IVI_EPA_ADAS_VOL: 8 IVI_IF
 SG_ IVI_CH8_VOL_STEP : 5|3@1+ (1,0) [0|7] ""  EPA
 SG_ IVI_CH9_VOL_STEP : 2|3@1+ (1,0) [0|7] ""  EPA
 SG_ IVI_CH10_CH15_VOL_STEP : 13|3@1+ (1,0) [0|7] ""  EPA
 SG_ IVI_CH0_CH1_OMP_STEP : 25|7@1+ (1,0) [0|127] ""  EPA

BO_ 233 IVI_EPA_CONTROL: 8 IVI_IF
 SG_ IVI_SOUND_FADE : 4|4@1+ (1,0) [0|15] ""  EPA
 SG_ IVI_SOUND_BAL : 0|4@1+ (1,0) [0|15] ""  EPA
 SG_ IVI_ATMOS_MOD_TYPE : 12|4@1+ (1,0) [0|15] ""  EPA
 SG_ IVI_VOL_SPEED_SW : 11|1@1+ (1,0) [0|1] ""  EPA
 SG_ IVI_ESE_MOD_SW : 10|1@1+ (1,0) [0|1] ""  EPA
 SG_ IVI_ESE_MOD_TYPE : 20|4@1+ (1,0) [0|15] ""  EPA
 SG_ IVI_ESE_VOL : 18|2@1+ (1,0) [0|3] ""  EPA
 SG_ IVI_PED_ALARM : 29|3@1+ (1,0) [0|7] ""  EPA
 SG_ IVI_UNLOCK_SW : 28|1@1+ (1,0) [0|1] ""  EPA
 SG_ IVI_LOCK_SW : 27|1@1+ (1,0) [0|1] ""  EPA
 SG_ IVI_OMP_Switch : 26|1@1+ (1,0) [0|1] ""  EPA
 SG_ IVI_HRS_MODE_TYPE : 24|2@1+ (1,0) [0|3] ""  EPA
 SG_ IVI_ECALL_STATUS : 38|2@1+ (1,0) [0|3] ""  EPA

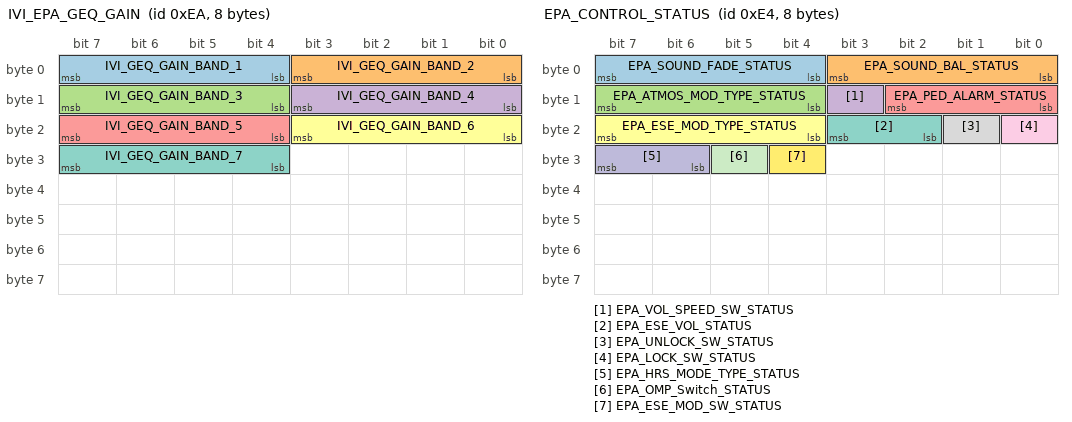
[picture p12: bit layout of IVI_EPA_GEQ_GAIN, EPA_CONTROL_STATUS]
BO_ 234 IVI_EPA_GEQ_GAIN: 8 IVI_IF
 SG_ IVI_GEQ_GAIN_BAND_1 : 4|4@1+ (1,0) [0|15] ""  EPA
 SG_ IVI_GEQ_GAIN_BAND_2 : 0|4@1+ (1,0) [0|15] ""  EPA
 SG_ IVI_GEQ_GAIN_BAND_3 : 12|4@1+ (1,0) [0|15] ""  EPA
 SG_ IVI_GEQ_GAIN_BAND_4 : 8|4@1+ (1,0) [0|15] ""  EPA
 SG_ IVI_GEQ_GAIN_BAND_5 : 20|4@1+ (1,0) [0|15] ""  EPA
 SG_ IVI_GEQ_GAIN_BAND_6 : 16|4@1+ (1,0) [0|15] ""  EPA
 SG_ IVI_GEQ_GAIN_BAND_7 : 28|4@1+ (1,0) [0|15] ""  EPA

BO_ 992 EPA_GENERAL_STATUS: 8 EPA
 SG_ EPA_CH0_STS : 0|2@1+ (1,0) [0|3] ""  IVI_IF
 SG_ EPA_CH1_STS : 2|2@1+ (1,0) [0|3] ""  IVI_IF
 SG_ EPA_CH2_STS : 4|2@1+ (1,0) [0|3] ""  IVI_IF
 SG_ EPA_CH3_STS : 6|2@1+ (1,0) [0|3] ""  IVI_IF
 SG_ EPA_CH4_STS : 8|2@1+ (1,0) [0|3] ""  IVI_IF
 SG_ EPA_CH5_STS : 10|2@1+ (1,0) [0|3] ""  IVI_IF
 SG_ EPA_CH6_STS : 12|2@1+ (1,0) [0|3] ""  IVI_IF
 SG_ EPA_CH7_STS : 14|2@1+ (1,0) [0|3] ""  IVI_IF
 SG_ EPA_CH8_STS : 16|2@1+ (1,0) [0|3] ""  IVI_IF
 SG_ EPA_CH9_STS : 18|2@1+ (1,0) [0|3] ""  IVI_IF
 SG_ EPA_CH10_STS : 20|2@1+ (1,0) [0|3] ""  IVI_IF
 SG_ EPA_CH11_STS : 22|2@1+ (1,0) [0|3] ""  IVI_IF
 SG_ EPA_CH12_STS : 24|2@1+ (1,0) [0|3] ""  IVI_IF
 SG_ EPA_CH13_STS : 26|2@1+ (1,0) [0|3] ""  IVI_IF
 SG_ EPA_CH14_STS : 28|2@1+ (1,0) [0|3] ""  IVI_IF
 SG_ EPA_CH15_STS : 30|2@1+ (1,0) [0|3] ""  IVI_IF
 SG_ EPA_CH16_STS : 38|2@1+ (1,0) [0|3] ""  IVI_IF
 SG_ EPA_CH17_STS : 36|2@1+ (1,0) [0|3] ""  IVI_IF
 SG_ EPA_CH18_STS : 34|2@1+ (1,0) [0|3] ""  IVI_IF
 SG_ EPA_CH19_STS : 32|2@1+ (1,0) [0|3] ""  IVI_IF
 SG_ EPA_CH20_STS : 46|2@1+ (1,0) [0|3] ""  IVI_IF
 SG_ EPA_CH21_STS : 44|2@1+ (1,0) [0|3] ""  IVI_IF
 SG_ EPA_CH22_STS : 42|2@1+ (1,0) [0|3] ""  IVI_IF
 SG_ EPA_CH23_STS : 40|2@1+ (1,0) [0|3] ""  IVI_IF
 SG_ EPA_WORK_STS : 52|4@1+ (1,0) [0|15] ""  IVI_IF
 SG_ EPA_A2B_STS : 61|3@1+ (1,0) [0|8] ""  IVI_IF

BO_ 225 EPA_IVI_VOL_STATUS: 8 EPA
 SG_ EPA_CH0_CH1_VOL_STEP_STS : 1|7@1+ (1,0) [0|127] ""  IVI_IF
 SG_ EPA_CH2_VOL_STEP_STS : 9|7@1+ (1,0) [0|127] ""  IVI_IF
 SG_ EPA_CH3_VOL_STEP_STS : 17|7@1+ (1,0) [0|127] ""  IVI_IF
 SG_ EPA_CH4_VOL_STEP_STS : 25|7@1+ (1,0) [0|127] ""  IVI_IF
 SG_ EPA_CH5_VOL_STEP_STS : 33|7@1+ (1,0) [0|127] ""  IVI_IF
 SG_ EPA_CH6_VOL_STEP_STS : 41|7@1+ (1,0) [0|127] ""  IVI_IF
 SG_ EPA_CH7_VOL_STEP_STS : 54|2@1+ (1,0) [0|3] ""  IVI_IF
 SG_ EPA_CH0_CH1_MUTE_STS : 48|1@1+ (1,0) [0|1] ""  IVI_IF
 SG_ EPA_CH2_MUTE_STS : 0|1@1+ (1,0) [0|1] ""  IVI_IF
 SG_ EPA_CH3_MUTE_STS : 8|1@1+ (1,0) [0|1] ""  IVI_IF
 SG_ EPA_CH4_MUTE_STS : 16|1@1+ (1,0) [0|1] ""  IVI_IF
 SG_ EPA_CH5_MUTE_STS : 24|1@1+ (1,0) [0|1] ""  IVI_IF
 SG_ EPA_CH6_MUTE_STS : 32|1@1+ (1,0) [0|1] ""  IVI_IF
 SG_ EPA_CH7_MUTE_STS : 40|1@1+ (1,0) [0|1] ""  IVI_IF
 SG_ EPA_CH8_MUTE_STS : 63|1@1+ (1,0) [0|1] ""  IVI_IF
 SG_ EPA_CH9_MUTE_STS : 62|1@1+ (1,0) [0|1] ""  IVI_IF
 SG_ EPA_CH10_CH15_MUTE_STS : 61|1@1+ (1,0) [0|1] ""  IVI_IF

BO_ 226 EPA_ADAS_VOL_STATUS: 8 EPA
 SG_ EPA_CH8_VOL_STEP_STS : 5|3@1+ (1,0) [0|7] ""  IVI_IF
 SG_ EPA_CH9_VOL_STEP_STS : 2|3@1+ (1,0) [0|7] ""  IVI_IF
 SG_ EPA_CH10_CH15_VOL_STEP_STS : 13|3@1+ (1,0) [0|7] ""  IVI_IF
 SG_ EPA_CH0_CH1_OMP_STEP_STS : 25|7@1+ (1,0) [0|127] ""  IVI_IF

BO_ 228 EPA_CONTROL_STATUS: 8 EPA
 SG_ EPA_SOUND_FADE_STATUS : 4|4@1+ (1,0) [0|15] ""  IVI_IF
 SG_ EPA_SOUND_BAL_STATUS : 0|4@1+ (1,0) [0|15] ""  IVI_IF
 SG_ EPA_ATMOS_MOD_TYPE_STATUS : 12|4@1+ (1,0) [0|15] ""  IVI_IF
 SG_ EPA_VOL_SPEED_SW_STATUS : 11|1@1+ (1,0) [0|1] ""  IVI_IF
 SG_ EPA_PED_ALARM_STATUS : 8|3@1+ (1,0) [0|7] ""  IVI_IF
 SG_ EPA_ESE_MOD_TYPE_STATUS : 20|4@1+ (1,0) [0|15] ""  IVI_IF
 SG_ EPA_ESE_VOL_STATUS : 18|2@1+ (1,0) [0|3] ""  IVI_IF
 SG_ EPA_UNLOCK_SW_STATUS : 17|1@1+ (1,0) [0|1] ""  IVI_IF
 SG_ EPA_LOCK_SW_STATUS : 16|1@1+ (1,0) [0|1] ""  IVI_IF
 SG_ EPA_HRS_MODE_TYPE_STATUS : 30|2@1+ (1,0) [0|3] ""  IVI_IF
 SG_ EPA_OMP_Switch_STATUS : 29|1@1+ (1,0) [0|1] ""  IVI_IF
 SG_ EPA_ESE_MOD_SW_STATUS : 28|1@1+ (1,0) [0|1] ""  IVI_IF

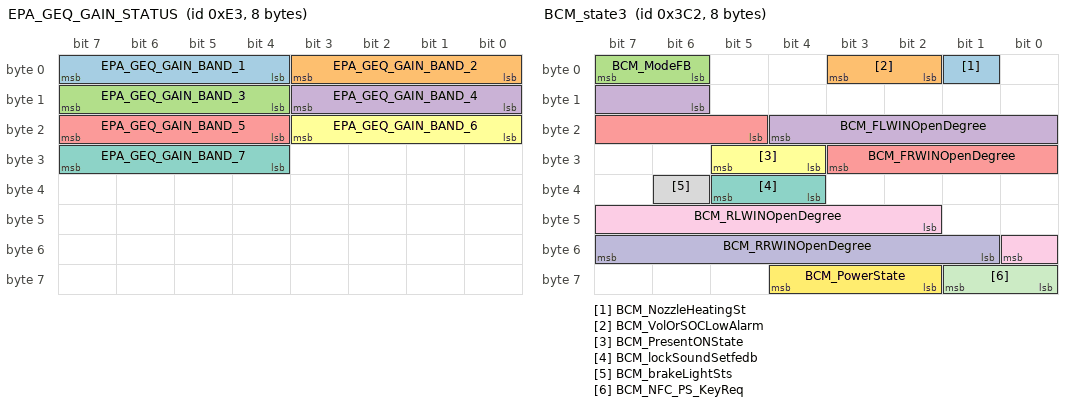
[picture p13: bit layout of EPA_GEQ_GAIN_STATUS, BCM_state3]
BO_ 227 EPA_GEQ_GAIN_STATUS: 8 EPA
 SG_ EPA_GEQ_GAIN_BAND_1 : 4|4@1+ (1,0) [0|15] ""  IVI_IF
 SG_ EPA_GEQ_GAIN_BAND_2 : 0|4@1+ (1,0) [0|15] ""  IVI_IF
 SG_ EPA_GEQ_GAIN_BAND_3 : 12|4@1+ (1,0) [0|15] ""  IVI_IF
 SG_ EPA_GEQ_GAIN_BAND_4 : 8|4@1+ (1,0) [0|15] ""  IVI_IF
 SG_ EPA_GEQ_GAIN_BAND_5 : 20|4@1+ (1,0) [0|15] ""  IVI_IF
 SG_ EPA_GEQ_GAIN_BAND_6 : 16|4@1+ (1,0) [0|15] ""  IVI_IF
 SG_ EPA_GEQ_GAIN_BAND_7 : 28|4@1+ (1,0) [0|15] ""  IVI_IF

BO_ 945 VCU_state2: 8 GW_IF
 SG_ VCU_CLTCEvRemainingMileage : 8|11@1+ (1,0) [0|2047] "km"  IVI_IF
 SG_ VCU_NEDCEvRemainingMileage : 19|11@1+ (1,0) [0|2047] "km"  IVI_IF
 SG_ VCU_NEDCDCChrgEfficiency : 30|10@1+ (0.1,0) [0|102.3] "km/min"  IVI_IF
 SG_ VCU_NEDCACChrgEfficiency : 40|10@1+ (0.1,0) [0|102.3] "km/h"  IVI_IF

BO_ 839 BLE_FB: 8 GW_IF
 SG_ BLE_approachingUnlockFedb : 0|2@1+ (1,0) [0|3] ""  IVI_IF
 SG_ BLE_awayLockFeedback : 2|2@1+ (1,0) [0|3] ""  IVI_IF
 SG_ BLE_RPAmodeReq : 12|2@1+ (1,0) [0|3] ""  IVI_IF

BO_ 885 BLE_User_ID: 8 GW_IF
 SG_ BLE_User_ID : 0|64@1+ (1,0) [0|1.84467E+019] ""  IVI_IF

BO_ 886 IVI_User_ID: 8 IVI_IF
 SG_ IVI_User_ID : 0|64@1+ (1,0) [0|1.84467E+019] ""  GW_IF

BO_ 950 AC_ctrlFeedback: 8 GW_IF
 SG_ ac_systemOnOffSts : 0|1@1+ (1,0) [0|1] ""  IVI_IF
 SG_ ac_autoStatus : 1|1@1+ (1,0) [0|1] ""  IVI_IF
 SG_ ac_acStatus : 2|1@1+ (1,0) [0|1] ""  IVI_IF
 SG_ ac_driverTempC : 3|5@1+ (0.5,17.5) [17.5|32.5] "degreeC"  IVI_IF
 SG_ ac_dualStatus : 8|1@1+ (1,0) [0|1] ""  IVI_IF
 SG_ ac_frontDefrostStatus1 : 9|1@1+ (1,0) [0|1] ""  IVI_IF
 SG_ ac_recircStatus : 10|1@1+ (1,0) [0|1] ""  IVI_IF
 SG_ ac_passengerTempC : 11|5@1+ (0.5,17.5) [17.5|32.5] "degreeC"  IVI_IF
 SG_ ac_blowerLvAUTOStatus : 23|1@1+ (1,0) [0|1] ""  IVI_IF
 SG_ ac_modeAUTOStatus : 30|1@1+ (1,0) [0|1] ""  IVI_IF
 SG_ ac_modeStatus : 32|3@1+ (1,0) [0|7] ""  IVI_IF
 SG_ ac_blowerLvStatus : 35|3@1+ (1,0) [0|7] ""  IVI_IF
 SG_ AC_InigentizePurificationStSwitc : 38|2@1+ (1,0) [0|3] ""  IVI_IF
 SG_ AC_InigentizePurificationSt : 47|1@1+ (1,0) [0|1] ""  IVI_IF
 SG_ AC_InsidePM25Level : 48|3@1+ (1,0) [0|7] ""  IVI_IF
 SG_ AC_PM25InCar : 51|10@1+ (1,0) [0|1000] "ug/m3"  IVI_IF
 SG_ AC_PurificationQuikReq : 61|1@1+ (1,0) [0|1] ""  IVI_IF
 SG_ AC_AutoDrySts : 62|2@1+ (1,0) [0|3] ""  IVI_IF

BO_ 673 BCM_state: 8 GW_IF
 SG_ bcm_cruiseSW : 0|1@1+ (1,0) [0|1] ""  IVI_IF
 SG_ bcm_cruiseSWValid : 1|1@1+ (1,0) [0|1] ""  IVI_IF
 SG_ BCM_cruiseHeadway_increase_KeySt : 6|1@1+ (1,0) [0|1] ""  IVI_IF,HUD
 SG_ BCM_cruiseHeadway_increase__0000 : 7|1@1+ (1,0) [0|1] ""  IVI_IF,HUD
 SG_ bcm_hoodSts : 10|1@1+ (1,0) [0|1] ""  IVI_IF
 SG_ bcm_hazardLightSwSts : 11|1@1+ (1,0) [0|1] ""  IVI_IF
 SG_ bcm_leftTurnLampSwSts : 12|1@1+ (1,0) [0|1] ""  IVI_IF
 SG_ bcm_leftTurnLampSts : 13|3@1+ (1,0) [0|7] ""  IVI_IF
 SG_ bcm_rightTurnLampSts : 16|3@1+ (1,0) [0|7] ""  IVI_IF
 SG_ bcm_rightTurnLampSwSts : 19|1@1+ (1,0) [0|1] ""  IVI_IF
 SG_ bcm_doorFLSts : 20|1@1+ (1,0) [0|1] ""  IVI_IF,ALC
 SG_ bcm_doorFRSts : 21|1@1+ (1,0) [0|1] ""  IVI_IF,ALC
 SG_ bcm_doorRLSts : 22|1@1+ (1,0) [0|1] ""  IVI_IF,ALC
 SG_ bcm_doorRRSts : 23|1@1+ (1,0) [0|1] ""  IVI_IF,ALC
 SG_ bcm_doorFLLockSts : 24|1@1+ (1,0) [0|1] ""  IVI_IF
 SG_ bcm_antiTheftSts : 29|3@1+ (1,0) [0|7] ""  IVI_IF,ALC,EPA
 SG_ bcm_FuelTapStatus : 32|2@1+ (1,0) [0|3] ""  IVI_IF
 SG_ bcm_frontWiperSts : 34|3@1+ (1,0) [0|7] ""  IVI_IF
 SG_ bcm_chrgCapSts : 37|1@1+ (1,0) [0|1] ""  IVI_IF
 SG_ BCM_cruiseHeadway_decrease_KeySt : 38|1@1+ (1,0) [0|1] ""  IVI_IF,HUD
 SG_ BCM_cruiseHeadway_decrease__0000 : 39|1@1+ (1,0) [0|1] ""  IVI_IF,HUD
 SG_ bcm_driverSeatDetectSts : 47|1@1+ (1,0) [0|1] ""  IVI_IF,ALC

BO_ 961 BCM_state2: 8 GW_IF
 SG_ bcm_rearMirrorSts : 0|1@1+ (1,0) [0|1] ""  IVI_IF
 SG_ BCM_HighBeamModel : 1|2@1+ (1,0) [0|3] ""  IVI_IF
 SG_ bcm_windowLFSts : 8|3@1+ (1,0) [0|7] ""  IVI_IF
 SG_ bcm_windowRFSts : 11|3@1+ (1,0) [0|7] ""  IVI_IF
 SG_ bcm_windowLRSts : 16|3@1+ (1,0) [0|7] ""  IVI_IF
 SG_ bcm_windowRRSts : 19|3@1+ (1,0) [0|7] ""  IVI_IF
 SG_ bcm_rearDefrostSts : 22|1@1+ (1,0) [0|1] ""  IVI_IF
 SG_ BCM_AutoRainWiperstatus : 23|1@1+ (1,0) [0|1] ""  IVI_IF
 SG_ bcm_rainSensorError : 28|1@1+ (1,0) [0|1] ""  IVI_IF
 SG_ bcm_positionLampSts : 30|1@1+ (1,0) [0|1] ""  IVI_IF,HUD,MFW
 SG_ bcm_autoLampSwSts : 31|1@1+ (1,0) [0|1] ""  IVI_IF
 SG_ bcm_rsmSolarRight : 32|8@1+ (5,0) [0|1265] "w/m2"  IVI_IF,HUD
 SG_ bcm_rsmSolarLeft : 40|8@1+ (5,0) [0|1265] "w/m2"  IVI_IF,HUD
 SG_ bcm_lowBeamSts : 48|2@1+ (1,0) [0|3] ""  IVI_IF
 SG_ bcm_highBeamSts : 50|2@1+ (1,0) [0|3] ""  IVI_IF
 SG_ bcm_rearFogLampSts : 56|1@1+ (1,0) [0|1] ""  IVI_IF
 SG_ bcm_lightSensorError : 58|1@1+ (1,0) [0|1] ""  IVI_IF
 SG_ bcm_roofLampSts : 59|1@1+ (1,0) [0|1] ""  IVI_IF

BO_ 962 BCM_state3: 8 GW_IF
 SG_ BCM_NozzleHeatingSt : 1|1@1+ (1,0) [0|1] ""  IVI_IF
 SG_ BCM_VolOrSOCLowAlarm : 2|2@1+ (1,0) [0|3] ""  IVI_IF
 SG_ BCM_ModeFB : 6|2@1+ (1,0) [0|3] ""  IVI_IF
 SG_ BCM_FLWINOpenDegree : 14|7@1+ (1,0) [0|127] ""  IVI_IF
 SG_ BCM_FRWINOpenDegree : 21|7@1+ (1,0) [0|127] ""  IVI_IF
 SG_ BCM_PresentONState : 28|2@1+ (1,0) [0|3] ""  IVI_IF
 SG_ BCM_lockSoundSetfedb : 36|2@1+ (1,0) [0|3] ""  IVI_IF
 SG_ BCM_brakeLightSts : 38|1@1+ (1,0) [0|1] ""  IVI_IF
 SG_ BCM_RLWINOpenDegree : 42|7@1+ (1,0) [0|127] ""  IVI_IF
 SG_ BCM_RRWINOpenDegree : 49|7@1+ (1,0) [0|127] ""  IVI_IF
 SG_ BCM_NFC_PS_KeyReq : 56|2@1+ (1,0) [0|3] ""  IVI_IF
 SG_ BCM_PowerState : 58|3@1+ (1,0) [0|7] ""  IVI_IF,MFW,ALC

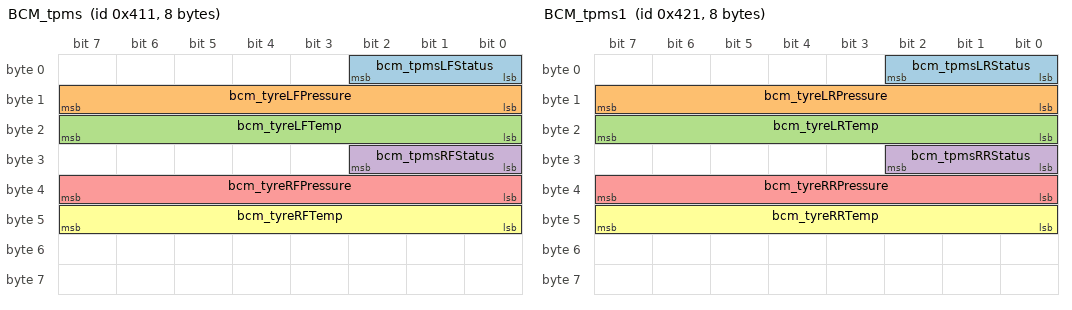
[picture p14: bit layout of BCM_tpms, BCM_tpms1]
BO_ 1041 BCM_tpms: 8 GW_IF
 SG_ bcm_tpmsLFStatus : 0|3@1+ (1,0) [0|7] ""  IVI_IF
 SG_ bcm_tyreLFPressure : 8|8@1+ (0.1,0.9) [0.9|7.9] "bar"  IVI_IF
 SG_ bcm_tyreLFTemp : 16|8@1+ (1,-41) [-41|213] "degreeC"  IVI_IF
 SG_ bcm_tpmsRFStatus : 24|3@1+ (1,0) [0|7] ""  IVI_IF
 SG_ bcm_tyreRFPressure : 32|8@1+ (0.1,0.9) [0.9|7.9] "bar"  IVI_IF
 SG_ bcm_tyreRFTemp : 40|8@1+ (1,-41) [-41|213] "degreeC"  IVI_IF

BO_ 1057 BCM_tpms1: 8 GW_IF
 SG_ bcm_tpmsLRStatus : 0|3@1+ (1,0) [0|7] ""  IVI_IF
 SG_ bcm_tyreLRPressure : 8|8@1+ (0.1,0.9) [0.9|7.9] "bar"  IVI_IF
 SG_ bcm_tyreLRTemp : 16|8@1+ (1,-41) [-41|213] "degreeC"  IVI_IF
 SG_ bcm_tpmsRRStatus : 24|3@1+ (1,0) [0|7] ""  IVI_IF
 SG_ bcm_tyreRRPressure : 32|8@1+ (0.1,0.9) [0.9|7.9] "bar"  IVI_IF
 SG_ bcm_tyreRRTemp : 40|8@1+ (1,-41) [-41|213] "degreeC"  IVI_IF

BO_ 705 BCM_peps: 8 GW_IF
 SG_ bcm_pepsPowerMode : 0|3@1+ (1,0) [0|7] ""  IVI_IF,ALC
 SG_ bcm_ChildSafetyLockRRSts : 3|1@1+ (1,0) [0|1] ""  IVI_IF
 SG_ bcm_pepsKeyNotInCarInd : 4|1@1+ (1,0) [0|1] ""  IVI_IF
 SG_ bcm_pepsKeySerchFailInd : 7|1@1+ (1,0) [0|1] ""  IVI_IF
 SG_ bcm_pepsKeyCloserInd : 8|1@1+ (1,0) [0|1] ""  IVI_IF
 SG_ bcm_pepsFobLowBatWarning : 9|1@1+ (1,0) [0|1] ""  IVI_IF
 SG_ bcm_pepsPowerRelayErrWarning : 10|1@1+ (1,0) [0|1] ""  IVI_IF
 SG_ bcm_ChildSafetyLockSts : 11|1@1+ (1,0) [0|1] ""  IVI_IF
 SG_ bcm_esclUnlockFailWarning : 12|1@1+ (1,0) [0|1] ""  IVI_IF
 SG_ bcm_esclLockFailWarning : 13|1@1+ (1,0) [0|1] ""  IVI_IF
 SG_ bcm_remoteMode : 14|2@1+ (1,0) [0|3] ""  IVI_IF
 SG_ bcm_DriveDoorUnlockFedb : 16|2@1+ (1,0) [0|3] ""  IVI_IF
 SG_ bcm_12VBatterySOC : 32|8@1+ (1,0) [0|100] "%"  IVI_IF
 SG_ bcm_pepsKeyInCarInd : 40|1@1+ (1,0) [0|1] ""  IVI_IF
 SG_ bcm_lowBeamFailureInd : 41|1@1+ (1,0) [0|1] ""  IVI_IF
 SG_ bcm_frontLeftTurnLightFailInd : 42|1@1+ (1,0) [0|1] ""  IVI_IF
 SG_ bcm_frontRightTurnLightFailInd : 43|1@1+ (1,0) [0|1] ""  IVI_IF
 SG_ bcm_rearFixLeftTurnLightFailInd : 44|1@1+ (1,0) [0|1] ""  IVI_IF
 SG_ bcm_rearMoveLeftTurnLightFailInd : 45|1@1+ (1,0) [0|1] ""  IVI_IF
 SG_ bcm_rearFixRightTurnLightFailInd : 46|1@1+ (1,0) [0|1] ""  IVI_IF
 SG_ bcm_rearMoRightTurnLightFailInd : 47|1@1+ (1,0) [0|1] ""  IVI_IF
 SG_ bcm_ChildSafetyLockRLSts : 50|1@1+ (1,0) [0|1] ""  IVI_IF
 SG_ bcm_doorTopSwitchSts : 52|2@1+ (1,0) [0|3] ""  IVI_IF
 SG_ bcm_approachingUnlockFedb : 54|2@1+ (1,0) [0|3] ""  IVI_IF
 SG_ bcm_followMeHomeFedb : 56|3@1+ (1,0) [0|7] ""  IVI_IF
 SG_ bcm_awayLockFeedback : 59|2@1+ (1,0) [0|3] ""  IVI_IF
 SG_ bcm_MirrorAutoFoldUnfoldStatus : 61|2@1+ (1,0) [0|3] ""  IVI_IF

BO_ 977 BCM_rsm: 8 GW_IF
 SG_ BCM_apm_PassengeLockStatus : 11|1@1+ (1,0) [0|1] ""  IVI_IF
 SG_ BCM_positionLightOnReq : 12|1@1+ (1,0) [0|1] ""  IVI_IF,IC
 SG_ BCM_LockCloseWinFedb : 43|2@1+ (1,0) [0|3] ""  IVI_IF

BO_ 1475 BCM_RemotFB: 8 GW_IF
 SG_ BCM_FRWINReason : 4|4@1+ (1,0) [0|15] ""  IVI_IF
 SG_ BCM_FLWINReason : 8|4@1+ (1,0) [0|15] ""  IVI_IF
 SG_ BCM_RLWINReason : 12|4@1+ (1,0) [0|15] ""  IVI_IF
 SG_ BCM_RRWINReason : 16|4@1+ (1,0) [0|15] ""  IVI_IF

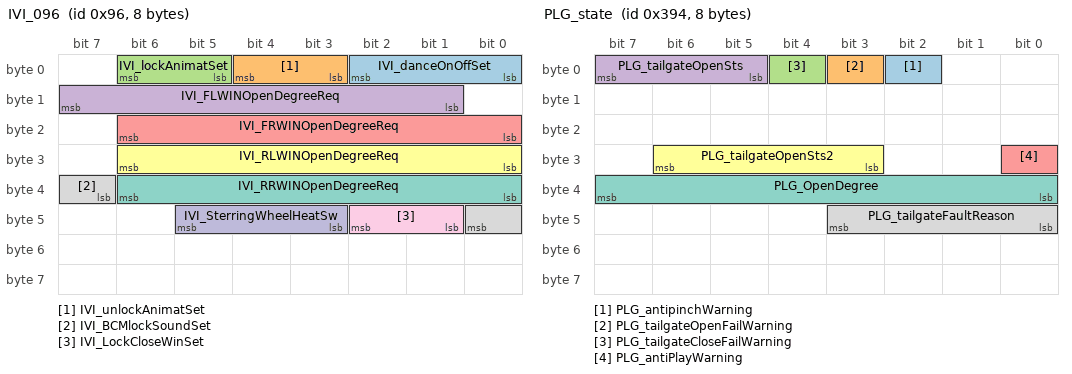
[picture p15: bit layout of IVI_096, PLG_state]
BO_ 150 IVI_096: 8 IVI_IF
 SG_ IVI_danceOnOffSet : 0|3@1+ (1,0) [0|7] ""  GW_IF
 SG_ IVI_unlockAnimatSet : 3|2@1+ (1,0) [0|3] ""  GW_IF
 SG_ IVI_lockAnimatSet : 5|2@1+ (1,0) [0|3] ""  GW_IF
 SG_ IVI_FLWINOpenDegreeReq : 9|7@1+ (1,0) [0|127] ""  GW_IF
 SG_ IVI_FRWINOpenDegreeReq : 16|7@1+ (1,0) [0|127] ""  GW_IF
 SG_ IVI_RLWINOpenDegreeReq : 24|7@1+ (1,0) [0|127] ""  GW_IF
 SG_ IVI_RRWINOpenDegreeReq : 32|7@1+ (1,0) [0|127] ""  GW_IF
 SG_ IVI_BCMlockSoundSet : 39|2@1+ (1,0) [0|3] ""  GW_IF
 SG_ IVI_LockCloseWinSet : 41|2@1+ (1,0) [0|3] ""  GW_IF
 SG_ IVI_SterringWheelHeatSw : 43|3@1+ (1,0) [0|7] ""  MFW

BO_ 810 LCU_32A: 8 GW_IF
 SG_ LCU_danceOnOffSet_FB : 0|3@1+ (1,0) [0|7] ""  IVI_IF
 SG_ LCU_unlockAnimatSet_FB : 3|2@1+ (1,0) [0|3] ""  IVI_IF
 SG_ LCU_lockAnimatSet_FB : 5|2@1+ (1,0) [0|3] ""  IVI_IF

BO_ 916 PLG_state: 8 GW_IF
 SG_ PLG_antipinchWarning : 2|1@1+ (1,0) [0|1] ""  IVI_IF
 SG_ PLG_tailgateOpenFailWarning : 3|1@1+ (1,0) [0|1] ""  IVI_IF
 SG_ PLG_tailgateCloseFailWarning : 4|1@1+ (1,0) [0|1] ""  IVI_IF
 SG_ PLG_tailgateOpenSts : 5|3@1+ (1,0) [0|7] ""  IVI_IF
 SG_ PLG_antiPlayWarning : 24|1@1+ (1,0) [0|1] ""  IVI_IF
 SG_ PLG_tailgateOpenSts2 : 27|4@1+ (1,0) [0|15] ""  IVI_IF
 SG_ PLG_OpenDegree : 32|8@1+ (1,0) [0|100] "%"  IVI_IF
 SG_ PLG_tailgateFaultReason : 40|4@1+ (1,0) [0|15] ""  IVI_IF

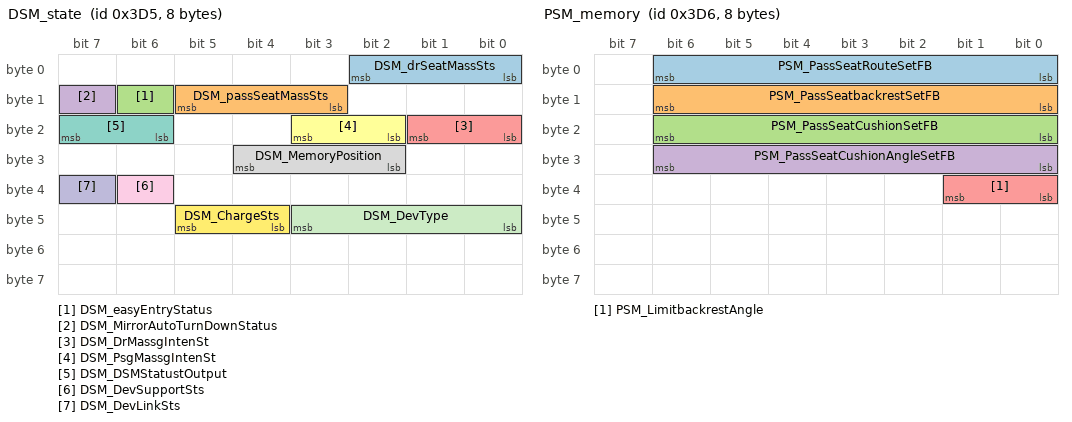
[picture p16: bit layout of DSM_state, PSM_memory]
BO_ 981 DSM_state: 8 GW_IF
 SG_ DSM_drSeatMassSts : 0|3@1+ (1,0) [0|7] ""  IVI_IF
 SG_ DSM_passSeatMassSts : 11|3@1+ (1,0) [0|7] ""  IVI_IF
 SG_ DSM_easyEntryStatus : 14|1@1+ (1,0) [0|1] ""  IVI_IF
 SG_ DSM_MirrorAutoTurnDownStatus : 15|1@1+ (1,0) [0|1] ""  IVI_IF
 SG_ DSM_DrMassgIntenSt : 16|2@1+ (1,0) [0|3] ""  IVI_IF
 SG_ DSM_PsgMassgIntenSt : 18|2@1+ (1,0) [0|3] ""  IVI_IF
 SG_ DSM_DSMStatustOutput : 22|2@1+ (1,0) [0|3] ""  IVI_IF
 SG_ DSM_MemoryPosition : 26|3@1+ (1,0) [0|7] ""  IVI_IF
 SG_ DSM_DevSupportSts : 38|1@1+ (1,0) [0|1] ""  IVI_IF
 SG_ DSM_DevLinkSts : 39|1@1+ (1,0) [0|1] ""  IVI_IF
 SG_ DSM_DevType : 40|4@1+ (1,0) [0|15] ""  IVI_IF
 SG_ DSM_ChargeSts : 44|2@1+ (1,0) [0|3] ""  IVI_IF

BO_ 982 PSM_memory: 8 GW_IF
 SG_ PSM_PassSeatRouteSetFB : 0|7@1+ (1,0) [0|127] ""  IVI_IF
 SG_ PSM_PassSeatbackrestSetFB : 8|7@1+ (1,0) [0|127] ""  IVI_IF
 SG_ PSM_PassSeatCushionSetFB : 16|7@1+ (1,0) [0|127] ""  IVI_IF
 SG_ PSM_PassSeatCushionAngleSetFB : 24|7@1+ (1,0) [0|127] ""  IVI_IF
 SG_ PSM_LimitbackrestAngle : 32|2@1+ (1,0) [0|3] ""  IVI_IF

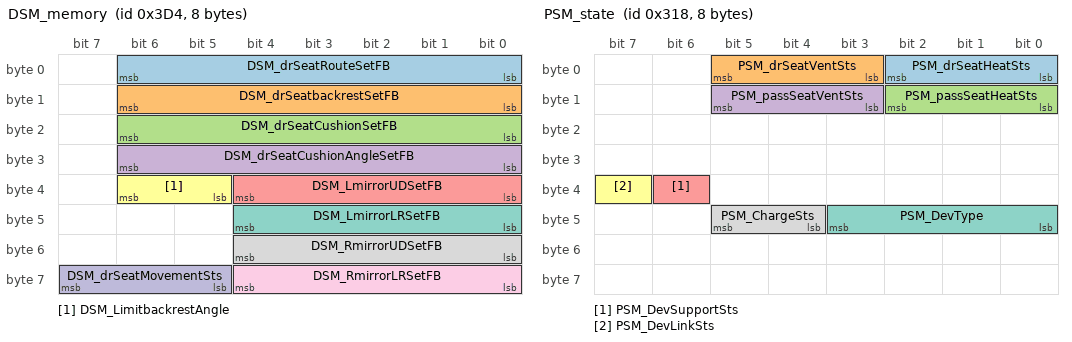
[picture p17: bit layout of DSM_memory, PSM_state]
BO_ 980 DSM_memory: 8 GW_IF
 SG_ DSM_drSeatRouteSetFB : 0|7@1+ (1,0) [0|127] ""  IVI_IF
 SG_ DSM_drSeatbackrestSetFB : 8|7@1+ (1,0) [0|127] ""  IVI_IF
 SG_ DSM_drSeatCushionSetFB : 16|7@1+ (1,0) [0|127] ""  IVI_IF
 SG_ DSM_drSeatCushionAngleSetFB : 24|7@1+ (1,0) [0|127] ""  IVI_IF
 SG_ DSM_LmirrorUDSetFB : 32|5@1+ (1,0) [0|31] ""  IVI_IF
 SG_ DSM_LimitbackrestAngle : 37|2@1+ (1,0) [0|3] ""  IVI_IF
 SG_ DSM_LmirrorLRSetFB : 40|5@1+ (1,0) [0|31] ""  IVI_IF
 SG_ DSM_RmirrorUDSetFB : 48|5@1+ (1,0) [0|31] ""  IVI_IF
 SG_ DSM_RmirrorLRSetFB : 56|5@1+ (1,0) [0|31] ""  IVI_IF
 SG_ DSM_drSeatMovementSts : 61|3@1+ (1,0) [0|7] ""  IVI_IF

BO_ 792 PSM_state: 8 GW_IF
 SG_ PSM_drSeatHeatSts : 0|3@1+ (1,0) [0|7] ""  IVI_IF
 SG_ PSM_drSeatVentSts : 3|3@1+ (1,0) [0|7] ""  IVI_IF
 SG_ PSM_passSeatHeatSts : 8|3@1+ (1,0) [0|7] ""  IVI_IF
 SG_ PSM_passSeatVentSts : 11|3@1+ (1,0) [0|7] ""  IVI_IF
 SG_ PSM_DevSupportSts : 38|1@1+ (1,0) [0|1] ""  IVI_IF
 SG_ PSM_DevLinkSts : 39|1@1+ (1,0) [0|1] ""  IVI_IF
 SG_ PSM_DevType : 40|4@1+ (1,0) [0|15] ""  IVI_IF
 SG_ PSM_ChargeSts : 44|2@1+ (1,0) [0|3] ""  IVI_IF

BO_ 794 LRSM_state: 8 GW_IF
 SG_ LRSM_LSeatHeatSts : 0|3@1+ (1,0) [0|7] ""  IVI_IF
 SG_ LRSM_RSeatHeatSts : 3|3@1+ (1,0) [0|7] ""  IVI_IF

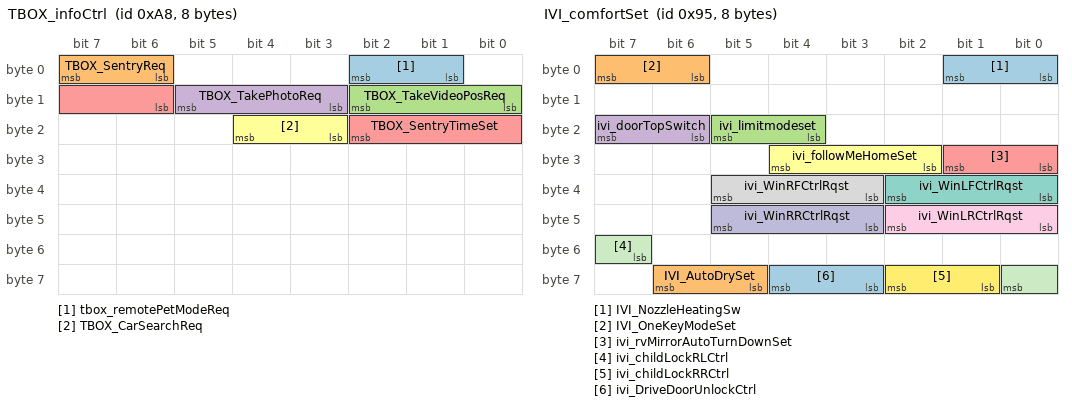
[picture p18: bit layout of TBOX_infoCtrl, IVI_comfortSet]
BO_ 168 TBOX_infoCtrl: 8 GW_IF
 SG_ tbox_remotePetModeReq : 1|2@1+ (1,0) [0|3] ""  IVI_IF
 SG_ TBOX_SentryReq : 6|2@1+ (1,0) [0|3] ""  IVI_IF
 SG_ TBOX_TakeVideoPosReq : 8|3@1+ (1,0) [0|7] ""  IVI_IF
 SG_ TBOX_TakePhotoReq : 11|3@1+ (1,0) [0|7] ""  IVI_IF
 SG_ TBOX_SentryTimeSet : 14|5@1+ (1,0) [0|31] ""  IVI_IF
 SG_ TBOX_CarSearchReq : 19|2@1+ (1,0) [0|3] ""  IVI_IF

BO_ 117 IVI_control: 8 IVI_IF
 SG_ ivi_childLockCtrl : 2|2@1+ (1,0) [0|3] ""  GW_IF
 SG_ ivi_centralLockCtrl : 6|2@1+ (1,0) [0|3] ""  GW_IF
 SG_ ivi_fuelPortCapOpenCtrl : 8|2@1+ (1,0) [0|3] ""  GW_IF
 SG_ ivi_lowBeamOnOffCtrl : 10|2@1+ (1,0) [0|3] ""  GW_IF
 SG_ ivi_v2vChrgOnOffSet : 12|2@1+ (1,0) [0|2] ""  GW_IF
 SG_ ivi_obcDschrgOnOffSet : 16|2@1+ (1,0) [0|3] ""  GW_IF
 SG_ ivi_rearFogLampOnOffCtrl : 20|2@1+ (1,0) [0|3] ""  GW_IF
 SG_ ivi_chrgPortCapOpenCtrl : 24|2@1+ (1,0) [0|3] ""  GW_IF
 SG_ ivi_NormalHvOffRequest : 29|1@1+ (1,0) [0|1] ""  GW_IF
 SG_ ivi_tailgateCtrl : 32|2@1+ (1,0) [0|3] ""  GW_IF
 SG_ ivi_MirrorSw : 34|2@1+ (1,0) [0|3] ""  GW_IF
 SG_ ivi_rearDefrostCtrl : 36|2@1+ (1,0) [0|3] ""  GW_IF
 SG_ ivi_MaxFuelConsumptionSW : 40|2@1+ (1,0) [0|3] ""  GW_IF
 SG_ ivi_MaxFuelConsumptionModeSW : 42|2@1+ (1,0) [0|3] ""  GW_IF
 SG_ ivi_v2vChrgOptCurntSet : 44|4@1+ (1,0) [0|15] "A"  GW_IF
 SG_ ivi_approachingUnlockCtrl : 50|2@1+ (1,0) [0|3] ""  GW_IF
 SG_ ivi_awayLockCtrl : 52|2@1+ (1,0) [0|3] ""  GW_IF
 SG_ ivi_wipperMaintModeCtrl : 54|1@1+ (1,0) [0|1] ""  GW_IF
 SG_ ivi_modememory : 58|2@1+ (1,0) [0|3] ""  GW_IF

BO_ 149 IVI_comfortSet: 8 IVI_IF
 SG_ IVI_NozzleHeatingSw : 0|2@1+ (1,0) [0|3] ""  GW_IF
 SG_ IVI_OneKeyModeSet : 6|2@1+ (1,0) [0|3] ""  GW_IF
 SG_ ivi_limitmodeset : 20|2@1+ (1,0) [0|3] ""  GW_IF
 SG_ ivi_doorTopSwitch : 22|2@1+ (1,0) [0|3] ""  GW_IF
 SG_ ivi_rvMirrorAutoTurnDownSet : 24|2@1+ (1,0) [0|3] ""  GW_IF
 SG_ ivi_followMeHomeSet : 26|3@1+ (1,0) [0|7] ""  GW_IF
 SG_ ivi_WinLFCtrlRqst : 32|3@1+ (1,0) [0|7] ""  GW_IF
 SG_ ivi_WinRFCtrlRqst : 35|3@1+ (1,0) [0|7] ""  GW_IF
 SG_ ivi_WinLRCtrlRqst : 40|3@1+ (1,0) [0|7] ""  GW_IF
 SG_ ivi_WinRRCtrlRqst : 43|3@1+ (1,0) [0|7] ""  GW_IF
 SG_ ivi_childLockRLCtrl : 55|2@1+ (1,0) [0|3] ""  GW_IF
 SG_ ivi_childLockRRCtrl : 57|2@1+ (1,0) [0|3] ""  GW_IF
 SG_ ivi_DriveDoorUnlockCtrl : 59|2@1+ (1,0) [0|3] ""  GW_IF
 SG_ IVI_AutoDrySet : 61|2@1+ (1,0) [0|3] ""  GW_IF

BO_ 165 IVI_pwrSet: 8 IVI_IF
 SG_ ivi_TripAReset : 0|1@1+ (1,0) [0|1] ""  GW_IF
 SG_ ivi_TripBReset : 1|1@1+ (1,0) [0|1] ""  GW_IF
 SG_ ivi_VehicleModeSet : 2|3@1+ (1,0) [0|7] ""  GW_IF
 SG_ ivi_RegenModeSet : 5|3@1+ (1,0) [0|7] ""  GW_IF
 SG_ ivi_traveModeSet : 8|2@1+ (1,0) [0|3] ""  GW_IF
 SG_ ivi_ChargeControl : 10|2@1+ (1,0) [0|3] ""  GW_IF
 SG_ ivi_ParkingChargeReq : 12|2@1+ (1,0) [0|3] ""  GW_IF
 SG_ ivi_TowModeSet : 14|2@1+ (1,0) [0|3] ""  GW_IF
 SG_ ivi_maxChrgSocSet : 16|8@1+ (1,0) [0|100] "%"  GW_IF
 SG_ ivi_chargeFormSet : 24|2@1+ (1,0) [0|3] ""  GW_IF
 SG_ ivi_ParkingChargeModeSet : 28|2@1+ (1,0) [0|3] ""  GW_IF
 SG_ ivi_chargeSetValid : 30|1@1+ (1,0) [0|1] ""  GW_IF
 SG_ ivi_ChargeEndTimeHour : 32|5@1+ (1,0) [0|23] ""  GW_IF
 SG_ ivi_ChargeStartTimeHour : 37|5@1+ (1,0) [0|23] ""  GW_IF
 SG_ ivi_ChargeEndTimeMinute : 42|6@1+ (1,0) [0|59] ""  GW_IF
 SG_ ivi_ChargeStartTimeMinute : 48|6@1+ (1,0) [0|59] ""  GW_IF
 SG_ ivi_ResetCurrentTrip : 54|1@1+ (1,0) [0|1] ""  GW_IF
 SG_ IVI_AcFullChargeToWarmSet : 56|2@1+ (1,0) [0|3] "" Vector__XXX
 SG_ ivi_ChargeEndTimeValid : 58|2@1+ (1,0) [0|3] ""  GW_IF
 SG_ ivi_ChargeStartTimeValid : 60|1@1+ (1,0) [0|1] ""  GW_IF
 SG_ ivi_driveModeSet : 61|3@1+ (1,0) [0|7] ""  GW_IF

BO_ 101 IVI_chassisSet_065: 8 IVI_IF
 SG_ ivi_epsModeSet : 0|2@1+ (1,0) [0|3] ""  GW_IF
 SG_ ivi_escOffSw : 2|2@1+ (1,0) [0|3] ""  GW_IF
 SG_ ivi_hdcOnOffSet : 4|2@1+ (1,0) [0|3] ""  GW_IF
 SG_ ivi_aebOnOffSet : 6|2@1+ (1,0) [0|3] ""  GW_IF
 SG_ ivi_iBModeSet : 8|2@1+ (1,0) [0|3] ""  GW_IF
 SG_ ivi_lcaBsdOnOffSet : 12|2@1+ (1,0) [0|3] ""  GW_IF
 SG_ ivi_rctaOnOffSetReserved : 14|2@1+ (1,0) [0|3] ""  GW_IF
 SG_ ivi_dowOnOffSet : 16|2@1+ (1,0) [0|3] ""  GW_IF
 SG_ ivi_StartRevSOCSet : 18|6@1+ (1,0) [20|80] "%"  GW_IF
 SG_ ivi_hmaOnOffSet : 24|2@1+ (1,0) [0|3] ""  GW_IF
 SG_ ivi_speedLimitOnOffSet : 26|2@1+ (1,0) [0|3] ""  GW_IF
 SG_ IVI_HVDownRepairMode : 28|2@1+ (1,0) [0|3] ""  GW_IF
 SG_ ivi_ASCHeightModeSelected : 30|3@1+ (1,0) [0|7] ""  GW_IF
 SG_ ivi_ASCMoveModeControl : 33|2@1+ (1,0) [0|3] ""  GW_IF
 SG_ ivi_laneAssistFuncSet : 35|3@1+ (1,0) [0|7] ""  GW_IF
 SG_ ivi_lasWarningModeSelection : 38|3@1+ (1,0) [0|7] ""  GW_IF
 SG_ ivi_EmergencyHvOffRequestReserve : 41|1@1+ (1,0) [0|1] ""  GW_IF
 SG_ ivi_ExhibitionModeCtrl : 42|2@1+ (1,0) [0|3] ""  GW_IF
 SG_ ivi_remainningMilModeSet : 44|3@1+ (1,0) [0|7] ""  GW_IF
 SG_ ivi_avhOnOffSet : 52|2@1+ (1,0) [0|3] ""  GW_IF
 SG_ ivi_pcwOnOffSet : 54|2@1+ (1,0) [0|3] ""  GW_IF
 SG_ ivi_TJAFuncSet : 56|2@1+ (1,0) [0|3] ""  GW_IF
 SG_ IVI_autododgeOnOffSet : 58|2@1+ (1,0) [0|3] ""  GW_IF
 SG_ ivi_trailerModeOnOffSet : 60|2@1+ (1,0) [0|3] ""  GW_IF
 SG_ ivi_esc_epbButtonRelease : 62|1@1+ (1,0) [0|1] ""  GW_IF
 SG_ IVI_ApaOnOffReq : 63|1@1+ (1,0) [0|1] ""  GW_IF

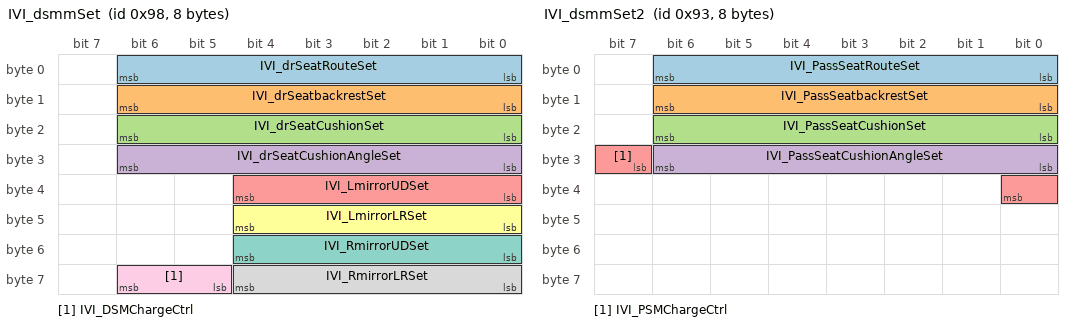
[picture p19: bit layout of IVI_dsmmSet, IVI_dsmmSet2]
BO_ 152 IVI_dsmmSet: 8 IVI_IF
 SG_ IVI_drSeatRouteSet : 0|7@1+ (1,0) [0|127] ""  GW_IF
 SG_ IVI_drSeatbackrestSet : 8|7@1+ (1,0) [0|127] ""  GW_IF
 SG_ IVI_drSeatCushionSet : 16|7@1+ (1,0) [0|127] ""  GW_IF
 SG_ IVI_drSeatCushionAngleSet : 24|7@1+ (1,0) [0|127] ""  GW_IF
 SG_ IVI_LmirrorUDSet : 32|5@1+ (1,0) [0|31] ""  GW_IF
 SG_ IVI_LmirrorLRSet : 40|5@1+ (1,0) [0|31] ""  GW_IF
 SG_ IVI_RmirrorUDSet : 48|5@1+ (1,0) [0|31] ""  GW_IF
 SG_ IVI_RmirrorLRSet : 56|5@1+ (1,0) [0|31] ""  GW_IF
 SG_ IVI_DSMChargeCtrl : 61|2@1+ (1,0) [0|3] ""  GW_IF

BO_ 147 IVI_dsmmSet2: 8 IVI_IF
 SG_ IVI_PassSeatRouteSet : 0|7@1+ (1,0) [0|127] ""  GW_IF
 SG_ IVI_PassSeatbackrestSet : 8|7@1+ (1,0) [0|127] ""  GW_IF
 SG_ IVI_PassSeatCushionSet : 16|7@1+ (1,0) [0|127] ""  GW_IF
 SG_ IVI_PassSeatCushionAngleSet : 24|7@1+ (1,0) [0|127] ""  GW_IF
 SG_ IVI_PSMChargeCtrl : 31|2@1+ (1,0) [0|3] ""  GW_IF

BO_ 151 IVI_ALCSet: 8 IVI_IF
 SG_ IVI_ALCThemeModeSet : 0|4@1+ (1,0) [0|15] ""  ALC
 SG_ IVI_DOWALCWarnningSet : 4|2@1+ (1,0) [0|3] ""  ALC
 SG_ IVI_easyEntryALCWarnningSet : 6|2@1+ (1,0) [0|3] ""  ALC
 SG_ IVI_ALCSwithCtrl : 16|2@1+ (1,0) [0|3] ""  ALC
 SG_ IVI_BreathFrequency : 18|3@1+ (1,0) [0|7] ""  ALC
 SG_ IVI_NavigationTurnSet : 21|2@1+ (1,0) [0|3] ""  ALC
 SG_ IVI_BSDWarnningSet : 24|2@1+ (1,0) [0|3] ""  ALC
 SG_ IVI_vehicleWarnningSet : 26|2@1+ (1,0) [0|3] ""  ALC
 SG_ IVI_BlueToothSet : 28|2@1+ (1,0) [0|3] ""  ALC
 SG_ IVI_FatigueReminderSet : 30|2@1+ (1,0) [0|3] ""  ALC
 SG_ ivi_IVIthemeSet : 32|2@1+ (1,0) [0|3] ""  ALC
 SG_ IVI_driveModeALCctrltset : 34|2@1+ (1,0) [0|3] ""  ALC
 SG_ IVI_ALCAplLuminance : 40|7@1+ (1,0) [0|127] ""  ALC
 SG_ IVI_VAP_FragranceCtrlReq : 48|2@1+ (1,0) [0|3] ""  VAP
 SG_ IVI_FragrancePositionSet : 50|2@1+ (1,0) [0|3] ""  VAP
 SG_ IVI_FragranceConcentrationSet : 52|4@1+ (1,0) [0|10] ""  VAP
 SG_ IVI_ALCAImodeSet : 58|2@1+ (1,0) [0|3] ""  ALC
 SG_ IVI_ALCTemperatureSwithCtrl : 60|2@1+ (1,0) [0|3] ""  ALC
 SG_ IVI_ACTempALCReq : 62|2@1+ (1,0) [0|3] ""  ALC

CM_ BO_ 3221225472 "This is a message for not used signals, created by Vector CANdb++ DBC OLE DB Provider.";
CM_ SG_ 863 tbox_MaxChargeCurrentSet "MaximumChargeCurrentSet
最大充电电流设置预留";
CM_ SG_ 863 tbox_ChargeFormSet "chargeform";
CM_ SG_ 863 tbox_ChargeControl "取消充电可取消直接充电+取消预约充电";
CM_ SG_ 863 tbox_MaxChargeSOCSet "MaximumChargeSOCSet
最大充电SOC设置";
CM_ SG_ 1300 bms_SOC "电池电量状态(显示SOC)";
CM_ SG_ 1300 bms_SOH "电池健康状态(SOH)";
CM_ SG_ 1300 bms_SOE "电池能量状态(SOE)";
CM_ SG_ 1300 bms_SOCActual "电池电量状态(实际SOC)";
CM_ SG_ 1300 bms_maxChargeSOC "最大充电SOC值";
CM_ SG_ 1300 BMS_BatterFaultLightContro "BMS_BatterFaultLightContro";
CM_ SG_ 1300 BMS_BatteryTempLowLight "电池温度低指示灯";
CM_ SG_ 1300 bms_stEgyFlowSysDischRgn "电池充放电能量流";
CM_ SG_ 1300 bms_stEgyFlowOBCAndBatt "电池OBC能量流";
CM_ SG_ 1300 bms_chargeFormstatus "充电模式";
CM_ SG_ 1396 bms_remainChargeTime "剩余充电时间";
CM_ SG_ 1396 bms_ChgAmount "单次已充电电量(单次外插充电电量)";
CM_ SG_ 1377 vcu_avgPwr "平均能耗";
CM_ SG_ 1377 vcu_alertLevel "故障等级";
CM_ SG_ 1377 VCU_chargeFaultReason "充电故障反馈";
CM_ SG_ 1377 VCU_RegenWeakRemind "能量回收回收减弱提示";
CM_ SG_ 849 vcu_remainingMileage "剩余里程WLTC（EV车型为CLTC续航里程）";
CM_ SG_ 849 vcu_ComprehensiveRemainingMileag "综合工况剩余续航里程";
CM_ SG_ 849 vcu_SysAlertLevel "系统故障等级";
CM_ SG_ 849 VCU_PowerLimitLight "功率限制指示灯";
CM_ SG_ 849 VCU_SysFaultLight "VCU系统故障指示灯";
CM_ SG_ 849 VCU_LVPowSupSYSAbn_lit "低压供电系统异常状态指示灯";
CM_ SG_ 849 VCU_UserGearReq "使用换挡请求（P档禁行）";
CM_ SG_ 849 VCU_PowerManageSt "能量管理状态";
CM_ SG_ 849 vcu_PwroCrntTrip "vcu_PwroCrntTrip
当前行程总电耗";
CM_ SG_ 273 vcu_accelPos "accelerationPedalposition
油门踏板位置";
CM_ SG_ 273 vcu_BrakeWarning "请踩刹车提示";
CM_ SG_ 1302 VCU_CLTCDCChrgEfficiency "CLTC直流充电效率";
CM_ SG_ 1302 VCU_CLTCACChrgEfficiency "CLTC交流充电效率";
CM_ SG_ 1302 VCU_WLTCDCChrgEfficiency "WLTC直流充电效率";
CM_ SG_ 1302 VCU_WLTCACChrgEfficiency "WLTC交流充电效率";
CM_ SG_ 1302 VCU_CompreDCChrgEfficiency "综合里程直流充电效率";
CM_ SG_ 1302 VCU_CompreACChrgEfficiency "综合里程交流充电效率";
CM_ SG_ 903 obc_state "OBC系统状态";
CM_ SG_ 903 obc_batteryConnectStatus_ "动力电池连接状态";
CM_ SG_ 903 obc_CcResistance "CC电阻值";
CM_ SG_ 909 dcdc_systemStatus "DCDC系统状态";
CM_ SG_ 909 dcdc_deratingStatus "DCDC输出限功率";
CM_ SG_ 909 dcdc_realOutputCurrent "DCDC输出电流";
CM_ SG_ 777 gsm_NoticeReq "解锁按键提示请求";
CM_ SG_ 777 gsm_gearSelectorPos "gsm_gearSelectorPos";
CM_ SG_ 906 mcuf0_torqueEst "mcuf0_torqueEst";
CM_ SG_ 906 mcur0_torqueEst "mcur0_torqueEst";
CM_ SG_ 772 bms_packTempMax "最高温度值";
CM_ SG_ 772 bms_packTempMin "最低温度值";
CM_ SG_ 772 bms_packTempAvg "平均温度值";
CM_ SG_ 817 vcu_Rev_VehicleHVpower "充电时高压附件功率消耗值";
CM_ SG_ 817 vcu_stEgyFlowGenMotAndBatt "StateofenergyflowforGeneratormotorandBattery.
VCU能量流来源于电池包";
CM_ SG_ 817 vcu_stEgyFlowEngAndGenMot "StateofenergyflowforGeneratormotorandengine.
VCU能量流来源于发动机";
CM_ SG_ 817 VCU_stEgyFlowMcuf0AndBatt "前电机能量状态";
CM_ SG_ 817 VCU_stEgyFlowMcur0AndBatt "后电机能量状态";
CM_ SG_ 817 VCU_IVI_HVDownRepairMode "断高压进入维修模式反馈";
CM_ SG_ 817 VCU_LowFuel "油量低提示
V2V功能停止或禁用时不可用";
CM_ SG_ 817 VCU_LowSOC "电量低提示
V2V功能停止或禁用时不可用";
CM_ SG_ 817 vcu_obcDschrgAllow "OBCdischargingallowsflag
OBC互充允许标志位";
CM_ SG_ 817 vcu_v2vChrgFdbk "V2Vchargingfeedbackflag
V2V充电反馈标志位";
CM_ SG_ 817 vcu_obcDschrgFdbk "OBCdischargingfeedbackflag
OBC互充反馈标志位";
CM_ SG_ 817 vcu_v2vChrgOutCurntFdbk "V2Vchargingoutputcurrentfeedback
V2V互充输出电流反馈";
CM_ SG_ 817 VCU_MaxFuelConsumptionSt "Maximumfuelconsumptionstatus
最大燃料消耗状态";
CM_ SG_ 817 VCU_MaxFuelConsumptionModeSt "Maximumfuelconsumptionmodestatus
最大燃料消耗模式状态燃油检测开关";
CM_ SG_ 817 vcu_RangeExtenderNoSt "RangeExtenderNotStart增程器未启动";
CM_ SG_ 2015 Diag_FuncReq_Data "Diag_FuncReq_Data";
CM_ SG_ 1267 ic_avgSpdTripB "Averagevehiclespeedsincetripmeterreset.
小计里程B平均车速";
CM_ SG_ 1267 ic_lastingtime "当前行程的持续时间";
CM_ SG_ 1267 ic_mileageSincethelastcharge "自上次充电后的里程显示";
CM_ SG_ 1267 ic_tripmeterThisMoment "当前小计里程显示";
CM_ SG_ 769 vcu_avgPwrCurrentTrip "AveragePowerofCurrentTrip
当前行程平均电耗";
CM_ SG_ 769 vcu_avgPwrSincelastcharge "AveragePowerSincethelastcharge
自上次充电后平均电耗";
CM_ SG_ 769 vcu_avgPwroftripA "AveragePoweroftripA
行程A平均电耗";
CM_ SG_ 769 vcu_PwroftripB "PoweroftripB
行程B总电耗";
CM_ SG_ 769 vcu_avgPwroftripB "AveragePoweroftripB
行程B平均电耗";
CM_ SG_ 769 vcu_lowSocwarming "lowSocwarming
动力电池电量低报警";
CM_ SG_ 769 VCU_SysFaulttext "VCU系统故障文本提示";
CM_ SG_ 816 vcu_v2vChrgAllow "V2Vchargingallowsflag
V2V充电允许标志位";
CM_ SG_ 816 vcu_v2vChrgOptVoltg "V2Vchargingoutputvoltage
V2V充电输出电压";
CM_ SG_ 816 vcu_v2vChrgOptCurnt "V2Vchargingoutputcurrent
V2V充电输出电流";
CM_ SG_ 816 VCU_ACChrgCurrtMax "交流充电设置电流反馈状态";
CM_ SG_ 816 VCU_PlugCableCapability "交流充电桩能力上限";
CM_ SG_ 932 BMS_ThrmlRunawaySt "热失控状态";
CM_ SG_ 932 BMS_ThrmlForecastersSt "烟雾传感器预警状态";
CM_ SG_ 932 BMS_AcFullChargeToWarmState "交流充电满阈值保温模式状态";
CM_ SG_ 932 BMS_3A4_RollingCounter "BMS_3A4_RollingCounter";
CM_ SG_ 932 BMS_3A4_Checksum "BMS_3A4_Checksum";
CM_ SG_ 929 vcu_driveMode "加速模式";
CM_ SG_ 929 vcu_VehicleMode "VehiclemodestatusVehiclemodestatus";
CM_ SG_ 929 VCU_PercentInstantaneousPower "驱动系统瞬时功率百分比";
CM_ SG_ 929 Vcu_ParkingChargeFB "驻车充电请求开关反馈";
CM_ SG_ 929 Vcu_ParkingChargeModFB "驻车充电模式反馈";
CM_ SG_ 929 vcu_towMode "被拖模式";
CM_ SG_ 929 vcu_ready "Powertrainready.
Ready状态";
CM_ SG_ 929 vcu_traveModeSts "vcu_traveModeSts ";
CM_ SG_ 929 vcu_highVoltagefaultSts "高压异常状态标志位";
CM_ SG_ 929 VCU_VehicleRepairModeFB "维修模式模式反馈";
CM_ SG_ 929 VCU_VehicleModeSetReq "增程器启动智能提醒";
CM_ SG_ 929 VCU_VehicleModeLOWTempReq "低温增程器智能启动提醒";
CM_ SG_ 929 VCU_RangeExtenderSt "增程器状态";
CM_ SG_ 929 vcu_highVoltageSuccess "Highvoltagestatus.
高压状态";
CM_ SG_ 929 vcu_hvOnMode "高压模式本地或远程";
CM_ SG_ 929 vcu_RegenModeStatus "Energyrecoveryonoffstatus";
CM_ SG_ 929 vcu_memoryStatus "VCU记忆状态";
CM_ SG_ 929 VCU_Eng_SelfShieldStart "发动机30天自保护启动标志";
CM_ SG_ 929 VCU_ExhibitionRequest "展车模式请求";
CM_ SG_ 929 vcu_ExhibitionMode "展车模式状态反馈";
CM_ SG_ 292 eps_warningLamp "EPSwarninglamp.无效值0x1
EPS故障灯";
CM_ SG_ 292 eps_rollingCounter "eps_rollingCounter";
CM_ SG_ 292 eps_checksum "eps_checksum";
CM_ SG_ 324 eps_sasSteeringAngle "SASsteeringangle.Leftpositive,rightnegtive
SAS转角，左正右负";
CM_ SG_ 324 eps_sasRawSteeringAngle "Thecurrentangleofthesteeringwheelwithoutoffsetvalue.Leftpositive,rightnegtive
未校正的转角值";
CM_ SG_ 324 eps_sasSteeringAngleSpd "SASsteeringanglespeed
SAS转角速度";
CM_ SG_ 324 eps_sasSteeringAngleSpdValid "SASsteeringanglespeedvalidsignal
SAS转角速度有效信号";
CM_ SG_ 324 eps_calibratedStatus "Thecalibrationinformationofsteeringanglesensor
传感器标定状态";
CM_ SG_ 324 eps_sasSteeringAngleValid "Validdataofsignaleps_sasSteeringAngle
SAS转角有效信号";
CM_ SG_ 322 esc_wheelSpeedFL "Frontleftwheelspeed
左前轮速信号";
CM_ SG_ 322 esc_wheelSpeedFLValid "Frontleftwheelspeedfrontvalidsignal
左前轮速信号有效位";
CM_ SG_ 322 esc_wheelSpeedFR "Frontrightwheelspeed
右前轮信号";
CM_ SG_ 322 esc_wheelSpeedFRValid "Frontrightwheelspeedfrontvalidsignal
右前轮速信号有效位";
CM_ SG_ 290 esc_wheelSpeedRL "Rearleftwheelspeed
左后轮速信号";
CM_ SG_ 290 esc_wheelSpeedRLValid "Rearleftwheelspeedfrontvalidsignal
左后轮速信号有效位";
CM_ SG_ 290 esc_wheelSpeedRR "Rearrightwheelspeed
右后轮速信号";
CM_ SG_ 290 esc_wheelSpeedRRValid "Rearrightwheelspeedfrontvalidsignal
右后轮速有效位";
CM_ SG_ 530 esc_vehicleSpeed "vehiclereferencespeed
车速";
CM_ SG_ 530 esc_vehicleSpeedValid "vehiclereferencespeedvalidsignal
车速有效位";
CM_ SG_ 530 esc_absFault "ABSsystemhasdetectedafailurewhichdoesnotallowareliableABSregulationandisthereforeswitchedoff无效值0x0
ABS系统故障状态";
CM_ SG_ 530 esc_absActive "indicatesABSinterventionactive
ABS激活状态";
CM_ SG_ 530 esc_escActive "IndicationthatVDC/TCSenginetorquecontrolorbraketorquecontrolsystemcurrentlyperformsabrake/engineintervention.无效值0x0
ESC激活状态";
CM_ SG_ 530 esc_tcsActive "indicatesTCSinterventionactive，TCSwilldetectspinningwheelsandrequesttorquereduction/limitation
TCS激活";
CM_ SG_ 530 esc_avhActive "indicatesAVHinactiveornot无效值0x0";
CM_ SG_ 530 esc_avhStandby "indicatesAVHinstandbymodeornot";
CM_ SG_ 530 esc_avhAvailable "HMIResponsible,CANgetdegrateAVHstatementfromDSWandsendout无效值0x0
AVH激活状态";
CM_ SG_ 530 esc_cdpActive "IndicateCDPControlActive无效值0x0
CDP激活";
CM_ SG_ 530 esc_hdcStatus "indicatesHDCcontrolstatus.无效值0x0";
CM_ SG_ 530 esc_hdcAvailable "HMIResponsible,CANgetdegrateHDCstatementfromDSWandsendout";
CM_ SG_ 530 esc_hhcAvailable "HMIResponsible,CANgetdegradeHHCstatementfromDSWandsendout
坡道辅助HHC是否可用";
CM_ SG_ 530 esc_ebdFault "ABSsystemhasdetectedaheavyfault,whichdoesnotevenallowareliableelectronicbrakedistributionandisthereforecompletelyshutdown无效值0x1
EBD故障状态";
CM_ SG_ 530 esc_offStatus "ESPOFFSWclose,ESPfunctionpassivePATA无效值0x0";
CM_ SG_ 530 esc_escFault "VDC/TCSisswitchedoffduetodetectedfailure无效值0x1
ESC故障状态";
CM_ SG_ 530 esc_emergencyBrakeSts "Emergencybrakesstatussignal无效值0x0
紧急刹车";
CM_ SG_ 530 esc_212_rollingCounter "esc_212_rollingCounter";
CM_ SG_ 530 esc_212_checksum "esc_212_checksum";
CM_ SG_ 674 esc_aebActive "ESPisexcutingAEB/EBA/AEB-VRUbrakingfunction
自动紧急制动状态";
CM_ SG_ 674 esc_hmiWarningOn "WiththissignalESCrequeststhewarninglampinthedashboard无效值0x3
结合iB点灯";
CM_ SG_ 674 esc_hmiWarningOn_Q "Qualifierofesc_hmiWarningOn.无效值0x2
结合iB点灯";
CM_ SG_ 674 esc_2A2_rollingCounter "esc_2A2_rollingCounter";
CM_ SG_ 674 esc_2A2_checksum "esc_2A2_checksum";
CM_ SG_ 594 esc_longAcceleration "longitudinalaccelerationsignal
纵向加速度信号";
CM_ SG_ 594 esc_longAccelerationValid "longitudinalaccelerationvalid
纵向加速度有效位";
CM_ SG_ 594 esc_yawRateValid "Yawratevalidsignal
横摆角信号有效位";
CM_ SG_ 594 esc_yawRate "Yawrate
横摆角信号";
CM_ SG_ 1019 apa_funcSts "APAfunctionstatus
APA功能状态";
CM_ SG_ 706 esc_epbFaultLamp "EPBfaultlamp
EPB故障";
CM_ SG_ 706 esc_epbParkingLamp "EPBparkinglamp
EPB驻车灯";
CM_ SG_ 706 esc_epbTextDisplay "EPBtextinformationfordisplay
EPB信息显示";
CM_ SG_ 706 esc_epbStatus "EPBsystemstatus
EPB系统状态";
CM_ SG_ 706 ESC_BrakeLevelAlarm "制动液位报警灯";
CM_ SG_ 706 esc_2C2_rollingCounter "esc_2C2_rollingCounter";
CM_ SG_ 706 esc_2C2_checkSum "esc_2C2_checkSum";
CM_ SG_ 537 mrr_accMode "ACCmodereceivedbyHMI
自适应巡航控制模式";
CM_ SG_ 537 mrr_219_RollingCounter "mrr_219_RollingCounter";
CM_ SG_ 537 mrr_219_CheckSum "mrr_219_CheckSum";
CM_ SG_ 569 mrr_EBAReq "mrr_EBAReq
制动辅助请求";
CM_ SG_ 569 mrr_aebReq "RequestoftheAEBtoPedestrianvehiclecontrol
紧急刹车请求，车辆减速度控制";
CM_ SG_ 569 mrr_aebOnOffStatus "AEBONOFFstatus
紧急刹车开启关闭状态";
CM_ SG_ 569 mrr_accTakeOverReq "ThelimitsoftheACCcontrolreaches,drivershouldtakeover
自适应巡航控制达到极限，驾驶员必须接管";
CM_ SG_ 569 mrr_vSetDis "Thesetspeedfromdriver,shouldbeavailableaslongasACCisactive
驾驶员设置巡航速度";
CM_ SG_ 569 mrr_PEBSWarning "PEBSWarning，includePreWarningandemergencyWarning
预测性紧急制动系统报警，包含预测性报警和紧急报警";
CM_ SG_ 569 mrr_timeGapSet "ThesettimeGapfromdriver,shouldbedisplayedtodriverandifthesetvaluechanges.";
CM_ SG_ 569 mrr_pcwOnOffStatus "IndicatingAEBWarningfunctionOnOffstatus
紧急制动报警功能开启关闭状态";
CM_ SG_ 569 mrr_textInfo "TextinfoforDriverwhichisdisplayedinDashboard
仪表台驾驶信息显示文本";
CM_ SG_ 569 mrr_239_RollingCounter "mrr_239_RollingCounter";
CM_ SG_ 569 mrr_SystemFailureSt "雷达系统故障状态";
CM_ SG_ 569 mrr_BlockedSt "雷达致盲状态";
CM_ SG_ 569 mrr_239_CheckSum "mrr_239_CheckSum";
CM_ SG_ 841 mrr_ACC_TargetType "本车道目标类型";
CM_ SG_ 841 mrr_ACC_TargetDetection "本车道目标识别情况";
CM_ SG_ 841 mrr_ACC_TargetRange "本车道目标纵向距离";
CM_ SG_ 841 mrr_ACC_RelevantTargetLatRange "有效目标横向距离";
CM_ SG_ 873 mrr_ACC_LeftTargetType "左车道最近目标类型";
CM_ SG_ 873 mrr_ACC_LeftTargetDetection "左侧目标识别情况";
CM_ SG_ 873 mrr_ACC_LeftTargetLngRange "左车道最近目标纵向距离";
CM_ SG_ 873 mrr_ACC_LeftTargetLatRange "左车道最近目标横向距离";
CM_ SG_ 873 mrr_ACC_RightTargetType "右车道最近目标类型";
CM_ SG_ 873 mrr_ACC_RightTargetLngRange "右车道最近目标纵向距离";
CM_ SG_ 873 mrr_ACC_RightTargetLatRange "右车道最近目标横向距离";
CM_ SG_ 873 mrr_ACC_RightTargetDetection "右侧目标识别情况";
CM_ SG_ 846 mrr_ACC_TargetType2 "本车道目标类型2";
CM_ SG_ 846 mrr_ACC_TargetDetection2 "本车道目标识别情况2";
CM_ SG_ 846 mrr_ACC_TargetRange2 "本车道目标纵向距离2";
CM_ SG_ 846 mrr_ACC_RelevantTargetLatRange2 "有效目标横向距离2";
CM_ SG_ 847 mrr_ACC_LeftTargetType2 "左车道最近目标类型2";
CM_ SG_ 847 mrr_ACC_LeftTargetDetection2 "左侧目标识别情况2";
CM_ SG_ 847 mrr_ACC_LeftTargetLngRange2 "左车道最近目标纵向距离2";
CM_ SG_ 847 mrr_ACC_LeftTargetLatRange2 "左车道最近目标横向距离2";
CM_ SG_ 847 mrr_ACC_RightTargetType2 "右车道最近目标类型2";
CM_ SG_ 847 mrr_ACC_RightTargetLngRange2 "右车道最近目标纵向距离2";
CM_ SG_ 847 mrr_ACC_RightTargetLatRange2 "右车道最近目标横向距离2";
CM_ SG_ 847 mrr_ACC_RightTargetDetection2 "右侧目标识别情况2";
CM_ SG_ 853 mrr_ACC_TargetType3 "本车道目标类型3(目标行人)";
CM_ SG_ 853 mrr_ACC_TargetDetection3 "本车道目标识别情况3(目标行人)";
CM_ SG_ 853 mrr_ACC_TargetRange3 "本车道目标纵向距离3(目标行人)";
CM_ SG_ 853 mrr_ACC_RelevantTargetLatRange3 "有效目标横向距离3(目标行人)";
CM_ SG_ 854 mrr_ACC_LeftTargetType3 "左车道最近目标类型3(目标行人)";
CM_ SG_ 854 mrr_ACC_LeftTargetDetection3 "左侧目标识别情况3(目标行人)";
CM_ SG_ 854 mrr_ACC_LeftTargetLngRange3 "左车道最近目标纵向距离3(目标行人)";
CM_ SG_ 854 mrr_ACC_LeftTargetLatRange3 "左车道最近目标横向距离3(目标行人)";
CM_ SG_ 854 mrr_ACC_RightTargetType3 "右车道最近目标类型3(目标行人)";
CM_ SG_ 854 mrr_ACC_RightTargetLngRange3 "右车道最近目标纵向距离3(目标行人)";
CM_ SG_ 854 mrr_ACC_RightTargetLatRange3 "右车道最近目标横向距离3(目标行人)";
CM_ SG_ 854 mrr_ACC_RightTargetDetection3 "右侧目标识别情况3(目标行人)";
CM_ SG_ 538 mpc_leftVisualization "Leftlinetrackingstatus
左侧车道线状态";
CM_ SG_ 538 mpc_rightVisualization "Rightlinetrackingstatus
右侧车道线状态";
CM_ SG_ 538 mpc_laneAssitType "OperationmodeofLKS
车道中心保持模式选择";
CM_ SG_ 538 mpc_slaSpeedLimitUnits "RSFoutputspeedlimitunit
限速标识识别限速单位";
CM_ SG_ 538 mpc_lasStatus "LASstatus
车道辅助系统状态";
CM_ SG_ 538 mpc_lasWarningModeSelection "LASWarningModereserved
车道辅助系统警告模式";
CM_ SG_ 538 mpc_IACCStatus "TJA/ICAstatus
交通拥堵/集成式巡航状态";
CM_ SG_ 538 mpc_adasTakeoverReq "Takeoverrequesttodriver
请求驾驶员接管车辆";
CM_ SG_ 538 mpc_hmaStatus "HMAStatus.无效值0x7
智能远近光灯状态";
CM_ SG_ 538 mpc_hmaHighbeamReq "HMAhighbeamrequest
智能远近光灯请求";
CM_ SG_ 538 mpc_slaStatus "RSFfunctionStatus
限速标识识别状态";
CM_ SG_ 538 mpc_slaSpeedLimit "RSFoutputspeedlimit
限速标识识别限速状态";
CM_ SG_ 538 mpc_slaOnOffSts "SLA功能开启/关闭状态";
CM_ SG_ 538 mpc_hmaOnOffSts "HMA功能开启/关闭状态";
CM_ SG_ 538 mpc_rollingCounter "mpc_rollingCounter";
CM_ SG_ 538 mpc_checkSum "mpc_checkSum";
CM_ SG_ 858 mpc_LAS_roadCurvature "车道辅助系统道路曲线";
CM_ SG_ 858 mpc_LAS_LLaneDistance "车辆到左侧车道线的距离";
CM_ SG_ 858 mpc_LAS_RLaneDistance "车辆到右侧车道线的距离";
CM_ SG_ 858 mpc_LAS_LLaneMarkerType "左侧车道线标识类型";
CM_ SG_ 858 mpc_LAS_RLaneMarkerType "右侧车道线标识类型";
CM_ SG_ 858 MPC_FrontCameraeStatus "前置智能摄像头状态";
CM_ SG_ 858 MPC_textinfor "TJA/ICAtextinforfordriver
交通拥堵/集成式巡航信息文本";
CM_ SG_ 858 MPC_TJAonoffStatus "TJA开关状态反馈";
CM_ SG_ 858 MPC_LLLaneMarkerType "左左侧车道线标识类型";
CM_ SG_ 858 MPC_LLLaneDistance "车辆到左左侧车道线的距离";
CM_ SG_ 858 MPC_RRLaneDistance "车辆到右右侧车道线的距离";
CM_ SG_ 858 MPC_RRLaneMarkerType "右右侧车道线标识类型";
CM_ SG_ 858 MPC_LleftVisualization "Leftlinetrackingstatus
左左侧车道线状态";
CM_ SG_ 858 MPC_RrightVisualization "Rightlinetrackingstatus
右右侧车道线状态";
CM_ SG_ 858 MPC_autododgeOnOffSts "智慧躲闪开关状态";
CM_ SG_ 857 MPC_LaneEquationC1 "车道线曲线方程为：y=C0+C1*x+(1/2)*C2*x^2+(1/6)*C3*x^3，其中C1为车辆相对预期轨迹的角度，换算公式为-1+(0x0~0xFFE)*2^(-11))";
CM_ SG_ 857 MPC_LaneEquationC2 "车道线曲线方程为：y=C0+C1*x+(1/2)*C2*x^2+(1/6)*C3*x^3，其中C2为车道线曲率，换算公式为(-2047+(0x0~0xFFE))*2^(-16))";
CM_ SG_ 857 MPC_LaneEquationC3 "车道线曲线方程为：y=C0+C1*x+(1/2)*C2*x^2+(1/6)*C3*x^3，其中C3为车道线曲率变化率，换算公式为(-2047+(0x0~0xFFE))*2^(-21))";
CM_ SG_ 857 MPC_LaneEquationStatus "车道线方程状态信号";
CM_ SG_ 857 MPC_RoadCurvatureNear "前方50m处道路曲率";
CM_ SG_ 857 MPC_RoadCurvatureFar "前方80m处道路曲率";
CM_ SG_ 555 SRR_r_ctaWarningReqRight "requestCTArightsidewarningelement
右侧交通横穿警示报警请求";
CM_ SG_ 555 SRR_r_bsdLCAWarningReqRight "requestBSD/LCArightsidewarningelement.无效值0x0
右侧盲区监测/变道辅助报警请求";
CM_ SG_ 555 SRR_r_displayInfo "Displayinformation
显示信息";
CM_ SG_ 555 SRR_r_bsdLCASts "BSDLCAswitchstatus
盲区监测/变道辅助开关状态";
CM_ SG_ 555 SRR_r_ctaSts "CTAswitchstatus
交通横穿警示开关状态";
CM_ SG_ 555 SRR_r_dowSts "DOWswitchstatus
开门警告开关状态";
CM_ SG_ 555 SRR_r_ctaWarningReqLeft "requestCTALeftsidewarningelement.无效值0x0
左侧交通横穿警示报警请求";
CM_ SG_ 555 SRR_r_bsdLCAWarningReqLeft "requestBSD/LCALeftsidewarningelement
左侧盲区监测/变道辅助报警请求";
CM_ SG_ 555 SRR_R_DOWFrontLeftDoorWarn "DOWFrontleftDoorwarning
左前门开门预警";
CM_ SG_ 555 SRR_R_DOWRearLeftDoorWarn "DOWRearleftDoorwarning
左后门开门预警";
CM_ SG_ 555 SRR_R_DOWFrontRightDoorWarn "DOWFrontRightDoorwarning
右前门开门预警";
CM_ SG_ 555 SRR_R_DOWRearRightDoorWarn "DOWRearRightDoorwarning
右后门开门预警";
CM_ SG_ 896 acu_warningLampStatus "安全气囊警告灯状态
WarningLampStatus";
CM_ SG_ 896 acu_crashOutputStatusValid "碰撞信号有效指示,Bosch一直发0x1:Crashsignalvalid
CrashSignalValid,Boschalwayssending0x1.";
CM_ SG_ 896 acu_crashOutputStatus "碰撞输出信号
CrashOutputStatus";
CM_ SG_ 896 acu_driverSeatBeltStatus "Driverseatbeltstatus
主驾安全带状态";
CM_ SG_ 896 acu_driverSeatBeltStatusValid "Driverseatbeltstatusvailidsignal
主驾安全带状态有效位";
CM_ SG_ 896 acu_passengerSeatBeltStatus "Passengerseatbeltstatus
副驾安全带状态";
CM_ SG_ 896 acu_passengerSeatBeltStatusValid "Passengerseatbeltstatusvalidsignal
副驾安全带状态有效位";
CM_ SG_ 896 acu_rollingCounter_ "acu_rollingCounter";
CM_ SG_ 896 acu_checksum_ "acu_checksum";
CM_ SG_ 859 APA_voice_reminder "声音请求";
CM_ SG_ 859 APA_textinfo "IVI提示APA无法进入请求";
CM_ SG_ 859 APA_FinishReason "结束原因";
CM_ SG_ 1032 ivi_currentRoadType "Currentroadtype.";
CM_ SG_ 1032 ivi_NAVIcameraspeedLimitvalueVal "电子眼限速有效位";
CM_ SG_ 1032 ivi_NAVIspeedLimitvalueValid "导航限速值有效位";
CM_ SG_ 1032 ivi_NAVItype "NAVItype导航类型";
CM_ SG_ 1032 ivi_NAVIcameraspeedLimitvalue "电子眼限速值";
CM_ SG_ 1032 ivi_NAVIspeedLimitvalue "NAVIspeedLimitvalue导航限速值";
CM_ SG_ 1032 ivi_NAVIStaus "NAVIStaus导航状态";
CM_ SG_ 1032 IVI_VehicleRepairModeReq "维修模式请求";
CM_ SG_ 1032 IVI_VehicleRepairModeSts "维修模式状态";
CM_ SG_ 1032 IVI_UserGearFb "换档确认（P档禁行）";
CM_ SG_ 1032 IVI_CarSearchSts "IVI_CarSearchSts（隐私模式状态）";
CM_ SG_ 1032 IVI_CarSearchControl "IVI_CarSearchControl（隐私模式设置）";
CM_ SG_ 1032 IVI_UserClass "用户状态";
CM_ SG_ 1032 IVI_ACChrgCurrtMaxSet "IVI充电电流设置";
CM_ SG_ 1032 ivi_languageSet2 "Languageset";
CM_ SG_ 230 IVI_CH0_CH1_VOL_STEP "车机CH0、CH1音频多媒体通道音量等级";
CM_ SG_ 230 IVI_CH2_VOL_STEP "车机CH2音频导航通道音量等级";
CM_ SG_ 230 IVI_CH3_VOL_STEP "车机CH3音频语助通道音量等级";
CM_ SG_ 230 IVI_CH4_VOL_STEP "车机CH4音频铃声通道音量等级";
CM_ SG_ 230 IVI_CH5_VOL_STEP "车机CH5音频电话通道音量等级";
CM_ SG_ 230 IVI_CH6_VOL_STEP "车机CH6音频通知音通道音量等级";
CM_ SG_ 230 IVI_CH7_VOL_STEP "车机CH7音频按键提示音通道音量等级";
CM_ SG_ 230 IVI_CH0_CH1_MUTE "车机CH0、CH1音频多媒体通道静音";
CM_ SG_ 230 IVI_CH2_MUTE "车机CH2音频导航通道静音";
CM_ SG_ 230 IVI_CH3_MUTE "车机CH3音频语音助手通道静音";
CM_ SG_ 230 IVI_CH4_MUTE "车机CH4音频铃声通道静音";
CM_ SG_ 230 IVI_CH5_MUTE "车机CH5音频电话通道静音";
CM_ SG_ 230 IVI_CH6_MUTE "车机CH6音频通知通道静音";
CM_ SG_ 230 IVI_CH7_MUTE "车机CH7音频按键提示通道静音";
CM_ SG_ 230 IVI_CH8_MUTE "车机CH8音频设备类紧急告警通道静音";
CM_ SG_ 230 IVI_CH9_MUTE "车机CH9音频驾驶类通知通道静音";
CM_ SG_ 230 IVI_CH10_CH15_MUTE "车机CH10至CH15音频仪表与雷达报警通道静音";
CM_ SG_ 231 IVI_CH8_VOL_STEP "车机CH8音频设备紧急告警音通道音量等级";
CM_ SG_ 231 IVI_CH9_VOL_STEP "车机CH9音频驾驶状态通知音通道音量等级";
CM_ SG_ 231 IVI_CH10_CH15_VOL_STEP "车机CH10~CH15音频QNX报警音通道音量等级";
CM_ SG_ 231 IVI_CH0_CH1_OMP_STEP "车机CH0、CH1车外音乐播放音量等级";
CM_ SG_ 233 IVI_SOUND_FADE "前后衰减增益等级";
CM_ SG_ 233 IVI_SOUND_BAL "左右平衡增益等级";
CM_ SG_ 233 IVI_ATMOS_MOD_TYPE "音效种类选择";
CM_ SG_ 233 IVI_VOL_SPEED_SW "音量随速调节开关";
CM_ SG_ 233 IVI_ESE_MOD_SW "声浪开关";
CM_ SG_ 233 IVI_ESE_MOD_TYPE "声浪模式";
CM_ SG_ 233 IVI_ESE_VOL "声浪音量";
CM_ SG_ 233 IVI_PED_ALARM "行人报警音";
CM_ SG_ 233 IVI_UNLOCK_SW "解锁音开关";
CM_ SG_ 233 IVI_LOCK_SW "闭锁音开关";
CM_ SG_ 233 IVI_OMP_Switch "车外音乐播放开关";
CM_ SG_ 233 IVI_HRS_MODE_TYPE "头枕音响模式";
CM_ SG_ 233 IVI_ECALL_STATUS "ECALL紧急报警通话状态";
CM_ SG_ 234 IVI_GEQ_GAIN_BAND_1 "中心频率（60Hz）增益等级";
CM_ SG_ 234 IVI_GEQ_GAIN_BAND_2 "中心频率（150Hz）增益等级";
CM_ SG_ 234 IVI_GEQ_GAIN_BAND_3 "中心频率（400Hz）增益等级";
CM_ SG_ 234 IVI_GEQ_GAIN_BAND_4 "中心频率（1000Hz）增益等级";
CM_ SG_ 234 IVI_GEQ_GAIN_BAND_5 "中心频率（2500Hz）增益等级";
CM_ SG_ 234 IVI_GEQ_GAIN_BAND_6 "中心频率（6000Hz）增益等级";
CM_ SG_ 234 IVI_GEQ_GAIN_BAND_7 "中心频率（10000Hz）增益等级";
CM_ SG_ 992 EPA_CH0_STS "CH0通道功放扬声器连接状态";
CM_ SG_ 992 EPA_CH1_STS "CH1通道功放扬声器连接状态";
CM_ SG_ 992 EPA_CH2_STS "CH2通道功放扬声器连接状态";
CM_ SG_ 992 EPA_CH3_STS "CH3通道功放扬声器连接状态";
CM_ SG_ 992 EPA_CH4_STS "CH4通道功放扬声器连接状态";
CM_ SG_ 992 EPA_CH5_STS "CH5通道功放扬声器连接状态";
CM_ SG_ 992 EPA_CH6_STS "CH6通道功放扬声器连接状态";
CM_ SG_ 992 EPA_CH7_STS "CH7通道功放扬声器连接状态";
CM_ SG_ 992 EPA_CH8_STS "CH8通道功放扬声器连接状态";
CM_ SG_ 992 EPA_CH9_STS "CH9通道功放扬声器连接状态";
CM_ SG_ 992 EPA_CH10_STS "CH10通道功放扬声器连接状态";
CM_ SG_ 992 EPA_CH11_STS "CH11通道功放扬声器连接状态";
CM_ SG_ 992 EPA_CH12_STS "CH12通道功放扬声器连接状态";
CM_ SG_ 992 EPA_CH13_STS "CH13通道功放扬声器连接状态";
CM_ SG_ 992 EPA_CH14_STS "CH14通道功放扬声器连接状态";
CM_ SG_ 992 EPA_CH15_STS "CH15通道功放扬声器连接状态";
CM_ SG_ 992 EPA_CH16_STS "CH16通道功放扬声器连接状态";
CM_ SG_ 992 EPA_CH17_STS "CH17通道功放扬声器连接状态";
CM_ SG_ 992 EPA_CH18_STS "CH18通道功放扬声器连接状态";
CM_ SG_ 992 EPA_CH19_STS "CH19通道功放扬声器连接状态";
CM_ SG_ 992 EPA_CH20_STS "CH20通道功放扬声器连接状态";
CM_ SG_ 992 EPA_CH21_STS "CH21通道功放扬声器连接状态";
CM_ SG_ 992 EPA_CH22_STS "CH22通道功放扬声器连接状态";
CM_ SG_ 992 EPA_CH23_STS "CH23通道功放扬声器连接状态";
CM_ SG_ 992 EPA_WORK_STS "功放工作状态";
CM_ SG_ 992 EPA_A2B_STS "功放A2B状态";
CM_ SG_ 225 EPA_CH0_CH1_VOL_STEP_STS "车机CH0、CH1音频多媒体通道音量等级状态";
CM_ SG_ 225 EPA_CH2_VOL_STEP_STS "车机CH2音频导航通道音量等级状态";
CM_ SG_ 225 EPA_CH3_VOL_STEP_STS "车机CH3音频语助通道音量等级状态";
CM_ SG_ 225 EPA_CH4_VOL_STEP_STS "车机CH4音频铃声通道音量等级状态";
CM_ SG_ 225 EPA_CH5_VOL_STEP_STS "车机CH5音频电话通道音量等级状态";
CM_ SG_ 225 EPA_CH6_VOL_STEP_STS "车机CH6音频通知音通道音量等级状态";
CM_ SG_ 225 EPA_CH7_VOL_STEP_STS "车机CH7音频按键提示音通道音量等级状态";
CM_ SG_ 225 EPA_CH0_CH1_MUTE_STS "车机CH0、CH1音频多媒体通道静音状态";
CM_ SG_ 225 EPA_CH2_MUTE_STS "车机CH2音频导航通道静音状态";
CM_ SG_ 225 EPA_CH3_MUTE_STS "车机CH3音频语音助手通道静音状态";
CM_ SG_ 225 EPA_CH4_MUTE_STS "车机CH4音频铃声通道静音状态";
CM_ SG_ 225 EPA_CH5_MUTE_STS "车机CH5音频电话通道静音状态";
CM_ SG_ 225 EPA_CH6_MUTE_STS "车机CH6音频通知通道静音状态";
CM_ SG_ 225 EPA_CH7_MUTE_STS "车机CH7音频按键提示通道静音状态";
CM_ SG_ 225 EPA_CH8_MUTE_STS "车机CH8音频设备类紧急告警通道静音状态";
CM_ SG_ 225 EPA_CH9_MUTE_STS "车机CH9音频驾驶类通知通道静音状态";
CM_ SG_ 225 EPA_CH10_CH15_MUTE_STS "车机CH10至CH15音频仪表与雷达报警通道静音状态";
CM_ SG_ 226 EPA_CH8_VOL_STEP_STS "车机CH8音频设备紧急告警音通道音量等级状态";
CM_ SG_ 226 EPA_CH9_VOL_STEP_STS "车机CH9音频驾驶状态通知音通道音量等级状态";
CM_ SG_ 226 EPA_CH10_CH15_VOL_STEP_STS "车机CH10~CH15音频QNX报警音通道音量等级状态";
CM_ SG_ 226 EPA_CH0_CH1_OMP_STEP_STS "车机CH0、CH1车外音乐播放音量等级状态";
CM_ SG_ 228 EPA_SOUND_FADE_STATUS "前后衰减增益等级状态";
CM_ SG_ 228 EPA_SOUND_BAL_STATUS "左右平衡增益等级状态";
CM_ SG_ 228 EPA_ATMOS_MOD_TYPE_STATUS "音效种类状态";
CM_ SG_ 228 EPA_VOL_SPEED_SW_STATUS "音量随速调节开关状态";
CM_ SG_ 228 EPA_PED_ALARM_STATUS "行人报警音状态";
CM_ SG_ 228 EPA_ESE_MOD_TYPE_STATUS "声浪模式状态";
CM_ SG_ 228 EPA_ESE_VOL_STATUS "声浪音量状态";
CM_ SG_ 228 EPA_UNLOCK_SW_STATUS "解锁音开关状态";
CM_ SG_ 228 EPA_LOCK_SW_STATUS "闭锁音开关状态";
CM_ SG_ 228 EPA_HRS_MODE_TYPE_STATUS "头枕音响模式状态";
CM_ SG_ 228 EPA_OMP_Switch_STATUS "车外音乐播放状态";
CM_ SG_ 228 EPA_ESE_MOD_SW_STATUS "声浪开关状态";
CM_ SG_ 227 EPA_GEQ_GAIN_BAND_1 "中心频率（60Hz）增益等级状态";
CM_ SG_ 227 EPA_GEQ_GAIN_BAND_2 "中心频率（150Hz）增益等级状态";
CM_ SG_ 227 EPA_GEQ_GAIN_BAND_3 "中心频率（400Hz）增益等级状态";
CM_ SG_ 227 EPA_GEQ_GAIN_BAND_4 "中心频率（1000Hz）增益等级状态";
CM_ SG_ 227 EPA_GEQ_GAIN_BAND_5 "中心频率（2500Hz）增益等级状态";
CM_ SG_ 227 EPA_GEQ_GAIN_BAND_6 "中心频率（6000Hz）增益等级状态";
CM_ SG_ 227 EPA_GEQ_GAIN_BAND_7 "中心频率（10000Hz）增益等级状态";
CM_ SG_ 945 VCU_CLTCEvRemainingMileage "CLTC电续航";
CM_ SG_ 945 VCU_NEDCEvRemainingMileage "NEDC电续航";
CM_ SG_ 945 VCU_NEDCDCChrgEfficiency "NEDC直流充电效率";
CM_ SG_ 945 VCU_NEDCACChrgEfficiency "NEDC交流充电效率";
CM_ SG_ 839 BLE_approachingUnlockFedb "approachingunlocksetfeedback";
CM_ SG_ 839 BLE_awayLockFeedback "awaylockcontrolstatus";
CM_ SG_ 839 BLE_RPAmodeReq "蓝牙RPA请求";
CM_ SG_ 885 BLE_User_ID "蓝牙账户ID";
CM_ SG_ 886 IVI_User_ID "账户ID";
CM_ SG_ 950 ac_systemOnOffSts "SystemON/OFFStatus
空调系统开启/关闭状态";
CM_ SG_ 950 ac_autoStatus "AUTOStatus
自动模式状态";
CM_ SG_ 950 ac_acStatus "A/CStatus
A/C状态";
CM_ SG_ 950 ac_driverTempC "DriverTemperatureCelsius
驾驶侧设置温度_摄氏度";
CM_ SG_ 950 ac_dualStatus "DualTemperatureStatus
双区状态";
CM_ SG_ 950 ac_frontDefrostStatus1 "FrontDefrostStatus
前除霜状态";
CM_ SG_ 950 ac_recircStatus "FreshAirStatus
内外循环状态";
CM_ SG_ 950 ac_passengerTempC "PassengerTemperatureCelsius
乘客侧设置温度_摄氏度";
CM_ SG_ 950 ac_blowerLvAUTOStatus "空调风量档位状态信号";
CM_ SG_ 950 ac_modeAUTOStatus "空调出风模式状态信号";
CM_ SG_ 950 ac_modeStatus "MODEStatus
当前模式";
CM_ SG_ 950 ac_blowerLvStatus "BlowerLevelStatus
当前风量档位";
CM_ SG_ 950 AC_InigentizePurificationStSwitc "智能净化开关状态";
CM_ SG_ 950 AC_InigentizePurificationSt "智能净化状态";
CM_ SG_ 950 AC_InsidePM25Level "PM2.5等级";
CM_ SG_ 950 AC_PM25InCar "车内PM2.5浓度";
CM_ SG_ 950 AC_PurificationQuikReq "快速净化请求";
CM_ SG_ 950 AC_AutoDrySts "空调干燥开关状态";
CM_ SG_ 673 bcm_cruiseSW "Cruiseswitch.";
CM_ SG_ 673 bcm_cruiseSWValid "Cruiseswitchvalid.";
CM_ SG_ 673 BCM_cruiseHeadway_increase_KeySt "headwayDIS+
时距增加";
CM_ SG_ 673 BCM_cruiseHeadway_increase__0000 "CruiseheadwayDIS+keystatusvalidsignal.
时距增加有效位";
CM_ SG_ 673 bcm_hoodSts "Hoodstatus.（引擎盖）";
CM_ SG_ 673 bcm_hazardLightSwSts "Hazardlightswitchstatus.危险报警灯开关状态";
CM_ SG_ 673 bcm_leftTurnLampSwSts "leftturnlampswitchstatus.";
CM_ SG_ 673 bcm_leftTurnLampSts "leftturnlampstatus.";
CM_ SG_ 673 bcm_rightTurnLampSts "rightturnlampstatus.";
CM_ SG_ 673 bcm_rightTurnLampSwSts "rightturnlampswitchstatus.";
CM_ SG_ 673 bcm_doorFLSts "Frontleftdoorstatus.";
CM_ SG_ 673 bcm_doorFRSts "Frontrightdoorstatus.";
CM_ SG_ 673 bcm_doorRLSts "Rearleftdoorstatus.";
CM_ SG_ 673 bcm_doorRRSts "Rearrightdoorstatus.";
CM_ SG_ 673 bcm_doorFLLockSts "Frontleftdoorlockstatus.";
CM_ SG_ 673 bcm_antiTheftSts "Anti-theftstatus.";
CM_ SG_ 673 bcm_FuelTapStatus "Fuelcapstatus.";
CM_ SG_ 673 bcm_frontWiperSts "Frontwiperstatus.";
CM_ SG_ 673 bcm_chrgCapSts "Chargingcapstatus.";
CM_ SG_ 673 BCM_cruiseHeadway_decrease_KeySt "headwayDIS-
时距减少";
CM_ SG_ 673 BCM_cruiseHeadway_decrease__0000 "CruiseheadwayDIS-keystatusvalidsignal.
时距减少有效位";
CM_ SG_ 673 bcm_driverSeatDetectSts "主驾座椅乘员检测状态
Driverdetectionstatus.";
CM_ SG_ 961 bcm_rearMirrorSts "Rearviewmirrorstatus.
后视镜折叠状态";
CM_ SG_ 961 BCM_HighBeamModel "远光灯模式";
CM_ SG_ 961 bcm_windowLFSts "Frontleftwindowstatus.";
CM_ SG_ 961 bcm_windowRFSts "Frontrightwindowstatus.";
CM_ SG_ 961 bcm_windowLRSts "Rearleftwindowstatus.";
CM_ SG_ 961 bcm_windowRRSts "Rearrightwindowstatus.";
CM_ SG_ 961 bcm_rearDefrostSts "Reardefroststatus.";
CM_ SG_ 961 BCM_AutoRainWiperstatus "自动雨刮控制开关状态";
CM_ SG_ 961 bcm_rainSensorError "rainsensorerror
雨量传感器故障";
CM_ SG_ 961 bcm_positionLampSts "Positionlampstatus.";
CM_ SG_ 961 bcm_autoLampSwSts "Autolampswitchstatus.";
CM_ SG_ 961 bcm_rsmSolarRight "Solarvaluerightside";
CM_ SG_ 961 bcm_rsmSolarLeft "Solarvalueleftside";
CM_ SG_ 961 bcm_lowBeamSts "Lowbeamstatus.";
CM_ SG_ 961 bcm_highBeamSts "highbeamstatus.";
CM_ SG_ 961 bcm_rearFogLampSts "rearfoglampstatus.";
CM_ SG_ 961 bcm_lightSensorError "lightsensorerror
光线传感器故障";
CM_ SG_ 961 bcm_roofLampSts "Rooflampstatus.";
CM_ SG_ 962 BCM_NozzleHeatingSt "洗涤喷嘴加热状态";
CM_ SG_ 962 BCM_VolOrSOCLowAlarm "VoltageOrSOCLowAlarm
铅酸电池电量低或电压低提示";
CM_ SG_ 962 BCM_ModeFB "情景模式反馈";
CM_ SG_ 962 BCM_FLWINOpenDegree "左前窗开启比例";
CM_ SG_ 962 BCM_FRWINOpenDegree "右前窗开启比例";
CM_ SG_ 962 BCM_PresentONState "PresentON状态机";
CM_ SG_ 962 BCM_lockSoundSetfedb "闭锁声音设置反馈";
CM_ SG_ 962 BCM_brakeLightSts "制动灯状态";
CM_ SG_ 962 BCM_RLWINOpenDegree "左后窗开启比例";
CM_ SG_ 962 BCM_RRWINOpenDegree "右后窗开启比例";
CM_ SG_ 962 BCM_NFC_PS_KeyReq "NFC钥匙请求";
CM_ SG_ 962 BCM_PowerState "BCM电源状态机";
CM_ SG_ 1041 bcm_tpmsLFStatus "bcm_tpmsLFStatus";
CM_ SG_ 1041 bcm_tyreLFPressure "bcm_tyreLFPressure";
CM_ SG_ 1041 bcm_tyreLFTemp "bcm_tyreLFTemp";
CM_ SG_ 1041 bcm_tpmsRFStatus "bcm_tpmsRFStatus";
CM_ SG_ 1041 bcm_tyreRFPressure "bcm_tyreRFPressure";
CM_ SG_ 1041 bcm_tyreRFTemp "bcm_tyreRFTemp";
CM_ SG_ 1057 bcm_tpmsLRStatus "bcm_tpmsLRStatus";
CM_ SG_ 1057 bcm_tyreLRPressure "bcm_tyreLRPressure";
CM_ SG_ 1057 bcm_tyreLRTemp "bcm_tyreLRTemp";
CM_ SG_ 1057 bcm_tpmsRRStatus "bcm_tpmsRRStatus";
CM_ SG_ 1057 bcm_tyreRRPressure "bcm_tyreRRPressure";
CM_ SG_ 1057 bcm_tyreRRTemp "bcm_tyreRRTemp";
CM_ SG_ 705 bcm_pepsPowerMode "bcm_pepsPowerMode";
CM_ SG_ 705 bcm_ChildSafetyLockRRSts "右后儿童锁状态信号";
CM_ SG_ 705 bcm_pepsKeyNotInCarInd "Keyisnotincarindication.
钥匙离开车内提示.";
CM_ SG_ 705 bcm_pepsKeySerchFailInd "Searchkeyfailedwarning.
未检测到钥匙报警.";
CM_ SG_ 705 bcm_pepsKeyCloserInd "Makethekeyclosertocoilindication.
提示将钥匙靠近线圈.";
CM_ SG_ 705 bcm_pepsFobLowBatWarning "Fobbatterylowwarning.
智能钥匙电池电量低提示";
CM_ SG_ 705 bcm_pepsPowerRelayErrWarning "Powerrelayerrorwarning.
电源继电器错误提示";
CM_ SG_ 705 bcm_ChildSafetyLockSts "ChildSafetyLockSts
儿童锁状态信号";
CM_ SG_ 705 bcm_esclUnlockFailWarning "ESCLunlockfailwarning.
转向柱锁解锁失败报警";
CM_ SG_ 705 bcm_esclLockFailWarning "ESCLlockfailwarning.
转向柱锁上锁失败报警";
CM_ SG_ 705 bcm_remoteMode "Remotemode.
远程模式";
CM_ SG_ 705 bcm_DriveDoorUnlockFedb "DriveDoorunlock set feedback
主驾解锁设置反馈";
CM_ SG_ 705 bcm_12VBatterySOC "12V蓄电池电量状态";
CM_ SG_ 705 bcm_pepsKeyInCarInd "Keyincarindication.
钥匙在车内提示.";
CM_ SG_ 705 bcm_lowBeamFailureInd "lowbeamfailureindication
近光灯故障指示信息";
CM_ SG_ 705 bcm_frontLeftTurnLightFailInd "frontleftturnlightFailureindication
前左转向灯故障提示信息";
CM_ SG_ 705 bcm_frontRightTurnLightFailInd "frontrightturnlightFailureindication
前右转向灯故障提示信息";
CM_ SG_ 705 bcm_rearFixLeftTurnLightFailInd "frontfixedleftturnlightFailureindication
后左固定转向灯故障提示信息";
CM_ SG_ 705 bcm_rearMoveLeftTurnLightFailInd "frontmoveableleftturnlightFailureindication
后左活动转向灯故障提示信息";
CM_ SG_ 705 bcm_rearFixRightTurnLightFailInd "frontfixedrightturnlightFailureindication
后右固定转向灯故障提示信息";
CM_ SG_ 705 bcm_rearMoRightTurnLightFailInd "frontmoveablerightturnlightFailureindication
后右活动转向灯故障提示信息";
CM_ SG_ 705 bcm_ChildSafetyLockRLSts "左后儿童锁状态信号";
CM_ SG_ 705 bcm_doorTopSwitchSts "门顶开关状态反馈";
CM_ SG_ 705 bcm_approachingUnlockFedb "approachingunlocksetfeedback";
CM_ SG_ 705 bcm_followMeHomeFedb "Followmehomefunctionsetfeedback";
CM_ SG_ 705 bcm_awayLockFeedback "awaylockcontrolstatus";
CM_ SG_ 705 bcm_MirrorAutoFoldUnfoldStatus "Mirrorautofold/unfoldfunctionsetstatus";
CM_ SG_ 977 BCM_apm_PassengeLockStatus "乘员窗户抑制状态";
CM_ SG_ 977 BCM_positionLightOnReq "阳光雨量传感器请求点亮位置灯请求";
CM_ SG_ 977 BCM_LockCloseWinFedb "闭锁升窗开关反馈";
CM_ SG_ 1475 BCM_FRWINReason "右前车窗故障原因";
CM_ SG_ 1475 BCM_FLWINReason "左前车窗故障原因";
CM_ SG_ 1475 BCM_RLWINReason "左后车窗故障原因";
CM_ SG_ 1475 BCM_RRWINReason "右后车窗故障原因";
CM_ SG_ 150 IVI_danceOnOffSet "灯舞开关设置";
CM_ SG_ 150 IVI_unlockAnimatSet "解锁灯语开关设置";
CM_ SG_ 150 IVI_lockAnimatSet "闭锁灯语开关设置";
CM_ SG_ 150 IVI_FLWINOpenDegreeReq "请求按比例开启左前窗";
CM_ SG_ 150 IVI_FRWINOpenDegreeReq "请求按比例开启右前窗";
CM_ SG_ 150 IVI_RLWINOpenDegreeReq "请求按比例开启左后窗";
CM_ SG_ 150 IVI_RRWINOpenDegreeReq "请求按比例开启右后窗";
CM_ SG_ 150 IVI_BCMlockSoundSet "闭锁声音设置";
CM_ SG_ 150 IVI_LockCloseWinSet "闭锁升窗设置开关";
CM_ SG_ 150 IVI_SterringWheelHeatSw "方向盘加热开关";
CM_ SG_ 810 LCU_danceOnOffSet_FB "灯舞状态反馈";
CM_ SG_ 810 LCU_unlockAnimatSet_FB "解锁灯语开关设置反馈";
CM_ SG_ 810 LCU_lockAnimatSet_FB "闭锁灯语开关设置反馈";
CM_ SG_ 916 PLG_antipinchWarning "Tailgateantipinchwarning.";
CM_ SG_ 916 PLG_tailgateOpenFailWarning "Tailgateopenfailwarning.";
CM_ SG_ 916 PLG_tailgateCloseFailWarning "Tailgateclosefailwarning.";
CM_ SG_ 916 PLG_tailgateOpenSts "Tailgateopenstatus.";
CM_ SG_ 916 PLG_antiPlayWarning "Tailgateantiplaywarning.";
CM_ SG_ 916 PLG_tailgateOpenSts2 "尾门开启状态";
CM_ SG_ 916 PLG_OpenDegree "尾门开启角度";
CM_ SG_ 916 PLG_tailgateFaultReason "背门故障原因";
CM_ SG_ 981 DSM_drSeatMassSts "DriverSeatmassageStatus
主驾座椅按摩状态";
CM_ SG_ 981 DSM_passSeatMassSts "PassengerSeatmassageStatus
副驾座椅按摩状态";
CM_ SG_ 981 DSM_easyEntryStatus "Easyentrystatusfeedback.
迎宾状态反馈";
CM_ SG_ 981 DSM_MirrorAutoTurnDownStatus "mirrorautoturndownonoffstatusfeedback.
后视镜自动下翻状态反馈";
CM_ SG_ 981 DSM_DrMassgIntenSt "DriverSeatIntenStatus
主驾座椅按摩强度状态";
CM_ SG_ 981 DSM_PsgMassgIntenSt "PassSeatIntenStatus
副驾座椅按摩强度状态";
CM_ SG_ 981 DSM_DSMStatustOutput "记忆模块工作状态
DSMworkstatus";
CM_ SG_ 981 DSM_MemoryPosition "DSM_MemoryPosition
记忆当前记忆状态（内部使用信号）";
CM_ SG_ 981 DSM_DevSupportSts "主驾设备支架连接状态";
CM_ SG_ 981 DSM_DevLinkSts "主驾设备连接状态";
CM_ SG_ 981 DSM_DevType "主驾设备型号";
CM_ SG_ 981 DSM_ChargeSts "主驾充电状态";
CM_ SG_ 982 PSM_PassSeatRouteSetFB "副驾座椅前后位置反馈";
CM_ SG_ 982 PSM_PassSeatbackrestSetFB "副驾座椅靠背位置";
CM_ SG_ 982 PSM_PassSeatCushionSetFB "副驾座垫高度位置";
CM_ SG_ 982 PSM_PassSeatCushionAngleSetFB "副驾座垫角度位置";
CM_ SG_ 982 PSM_LimitbackrestAngle "副驾限制靠背提醒信号";
CM_ SG_ 980 DSM_drSeatRouteSetFB "主驾座椅前后位置反馈";
CM_ SG_ 980 DSM_drSeatbackrestSetFB "主驾座椅靠背位置";
CM_ SG_ 980 DSM_drSeatCushionSetFB "主驾座垫高度位置";
CM_ SG_ 980 DSM_drSeatCushionAngleSetFB "主驾座垫角度位置";
CM_ SG_ 980 DSM_LmirrorUDSetFB "左侧后视镜上下调节";
CM_ SG_ 980 DSM_LimitbackrestAngle "主驾限制靠背提醒信号";
CM_ SG_ 980 DSM_LmirrorLRSetFB "左侧后视镜左右调节";
CM_ SG_ 980 DSM_RmirrorUDSetFB "右侧后视镜上下调节";
CM_ SG_ 980 DSM_RmirrorLRSetFB "右侧后视镜左右调节";
CM_ SG_ 980 DSM_drSeatMovementSts "主驾座椅和后视镜运动状态信号";
CM_ SG_ 792 PSM_drSeatHeatSts "Driverseatheatingstatus.
主驾座椅加热状态";
CM_ SG_ 792 PSM_drSeatVentSts "Driverseatventilationstatus
主驾座椅通风状态";
CM_ SG_ 792 PSM_passSeatHeatSts "Passengerseatheatingstatus.
副驾座椅加热状态";
CM_ SG_ 792 PSM_passSeatVentSts "Passengerseatventilationstatus
副驾座椅通风状态";
CM_ SG_ 792 PSM_DevSupportSts "副驾设备支架连接状态";
CM_ SG_ 792 PSM_DevLinkSts "副驾设备连接状态";
CM_ SG_ 792 PSM_DevType "副驾设备型号";
CM_ SG_ 792 PSM_ChargeSts "副驾充电状态";
CM_ SG_ 794 LRSM_LSeatHeatSts "secondleftseatheatingstatus.
二排左侧座椅加热状态";
CM_ SG_ 794 LRSM_RSeatHeatSts "secondrightseatheatingstatus.
二排右侧座椅加热状态";
CM_ SG_ 168 tbox_remotePetModeReq "tbox_remotePetModeReq";
CM_ SG_ 168 TBOX_SentryReq "哨兵模式进入请求";
CM_ SG_ 168 TBOX_TakeVideoPosReq "停车监控方向请求";
CM_ SG_ 168 TBOX_TakePhotoReq "停车拍照请求";
CM_ SG_ 168 TBOX_SentryTimeSet "哨兵模式时间设置";
CM_ SG_ 168 TBOX_CarSearchReq "隐私模式请求";
CM_ SG_ 117 ivi_childLockCtrl "Childsafetylockcontrol.
儿童锁控制";
CM_ SG_ 117 ivi_centralLockCtrl "Centrallockcontrol.
中控锁控制";
CM_ SG_ 117 ivi_fuelPortCapOpenCtrl "Fuelportcapopenclosecontrol.
加油口盖开关控制";
CM_ SG_ 117 ivi_lowBeamOnOffCtrl "Lowbeamonoffcontrol.预留
近光灯开关控制预留";
CM_ SG_ 117 ivi_v2vChrgOnOffSet "V2VchargingturnONorOFFset
V2V互充功能的开启和关闭";
CM_ SG_ 117 ivi_obcDschrgOnOffSet "OBCdischargingturnONorOFFset
OBC互充功能的开启和关闭";
CM_ SG_ 117 ivi_rearFogLampOnOffCtrl "Rearfoglamponoffcontrol.(reserved)
后雾灯开关控制（预留）";
CM_ SG_ 117 ivi_chrgPortCapOpenCtrl "Chargingportcapopencontrol.
充电口盖开关控制";
CM_ SG_ 117 ivi_NormalHvOffRequest "NormalHvOffRequest
正常下电设置";
CM_ SG_ 117 ivi_tailgateCtrl "Tailgatecontrol.
背门控制";
CM_ SG_ 117 ivi_MirrorSw "Rearviewmirrorunfoldcontrol.
后视镜折叠开关";
CM_ SG_ 117 ivi_rearDefrostCtrl "Reardefrostcontrol.
后除霜控制";
CM_ SG_ 117 ivi_MaxFuelConsumptionSW "Maximumfuelconsumptionswitchcontrol
最大燃料消耗开关";
CM_ SG_ 117 ivi_MaxFuelConsumptionModeSW "Maximumfuelconsumptionmodeswitchcontrol
最大燃料消耗模式切换开关";
CM_ SG_ 117 ivi_v2vChrgOptCurntSet "V2Vchargingoutputcurrentset
V2V互充输出的电流设置";
CM_ SG_ 117 ivi_approachingUnlockCtrl "approachingunlockcontrol
靠近解锁控制";
CM_ SG_ 117 ivi_awayLockCtrl "awaylockcontrol
远离闭锁控制";
CM_ SG_ 117 ivi_wipperMaintModeCtrl "控制雨刮进入维修模式档位信号";
CM_ SG_ 117 ivi_modememory "模式记忆";
CM_ SG_ 149 IVI_NozzleHeatingSw "洗涤喷嘴加热状态";
CM_ SG_ 149 IVI_OneKeyModeSet "OneKeyModeSet
一键设置";
CM_ SG_ 149 ivi_limitmodeset "ivi_limitmodeset
限速模式设置";
CM_ SG_ 149 ivi_doorTopSwitch "门顶开关";
CM_ SG_ 149 ivi_rvMirrorAutoTurnDownSet "Rearviewmirrorautoturndownonoffset.";
CM_ SG_ 149 ivi_followMeHomeSet "Followmehomefunctionset.";
CM_ SG_ 149 ivi_WinLFCtrlRqst "控制左前车窗";
CM_ SG_ 149 ivi_WinRFCtrlRqst "控制右前车窗";
CM_ SG_ 149 ivi_WinLRCtrlRqst "控制左后车窗";
CM_ SG_ 149 ivi_WinRRCtrlRqst "控制右后车窗";
CM_ SG_ 149 ivi_childLockRLCtrl "左后儿童锁控制";
CM_ SG_ 149 ivi_childLockRRCtrl "右后儿童锁控制";
CM_ SG_ 149 ivi_DriveDoorUnlockCtrl "IVI主驾单独解锁设置";
CM_ SG_ 149 IVI_AutoDrySet "空调干燥开关设置";
CM_ SG_ 165 ivi_TripAReset "tripAreset";
CM_ SG_ 165 ivi_TripBReset "tripBreset";
CM_ SG_ 165 ivi_VehicleModeSet "Vehiclemodeset.(EVR)";
CM_ SG_ 165 ivi_RegenModeSet "Energyrecoveryonoffset.";
CM_ SG_ 165 ivi_traveModeSet "ivi_traveModeSet ";
CM_ SG_ 165 ivi_ChargeControl "取消充电可取消直接充电+取消预约充电";
CM_ SG_ 165 ivi_ParkingChargeReq "驻车充电开关请求";
CM_ SG_ 165 ivi_TowModeSet "towModeSet";
CM_ SG_ 165 ivi_maxChrgSocSet "MaximumchargeSOCset.
最大充电电量设置";
CM_ SG_ 165 ivi_chargeFormSet "Chargeformset.";
CM_ SG_ 165 ivi_ParkingChargeModeSet "驻车充电模式设置";
CM_ SG_ 165 ivi_chargeSetValid "Slowchargesetvalidsigna.";
CM_ SG_ 165 ivi_ChargeEndTimeHour "充电结束时间(小时时刻)";
CM_ SG_ 165 ivi_ChargeStartTimeHour "充电开始时间(小时时刻)";
CM_ SG_ 165 ivi_ChargeEndTimeMinute "充电结束时间(分钟时刻)";
CM_ SG_ 165 ivi_ChargeStartTimeMinute "充电开始时间(分钟时刻)";
CM_ SG_ 165 ivi_ResetCurrentTrip "重置当前行程预留";
CM_ SG_ 165 IVI_AcFullChargeToWarmSet "交流充电满阈值模式设置";
CM_ SG_ 165 ivi_ChargeEndTimeValid "充电结束时间有效位";
CM_ SG_ 165 ivi_ChargeStartTimeValid "充电开始时间有效位";
CM_ SG_ 165 ivi_driveModeSet "Drivingmodeset.";
CM_ SG_ 101 ivi_epsModeSet "EPSmodeset.";
CM_ SG_ 101 ivi_escOffSw "ESCoffswitch.";
CM_ SG_ 101 ivi_hdcOnOffSet "HDCONOFFset.";
CM_ SG_ 101 ivi_aebOnOffSet "AEBONOFFset.";
CM_ SG_ 101 ivi_iBModeSet "iBoosterModeSet";
CM_ SG_ 101 ivi_lcaBsdOnOffSet "Lanechangeassist/BlindSpotDetectionONOFFset.";
CM_ SG_ 101 ivi_rctaOnOffSetReserved "RearCTAONOFFset预留";
CM_ SG_ 101 ivi_dowOnOffSet "DooropenwarningONOFFset.";
CM_ SG_ 101 ivi_StartRevSOCSet "StartRevSOCLimitSet
启动增程器SOC值设置";
CM_ SG_ 101 ivi_hmaOnOffSet "HighBeamAssistONOFFset.";
CM_ SG_ 101 ivi_speedLimitOnOffSet "SpeedlimitONOFFset.
限速辅助设置开关";
CM_ SG_ 101 IVI_HVDownRepairMode "断高压进入维修模式";
CM_ SG_ 101 ivi_ASCHeightModeSelected "空气悬架高度调节模式设置";
CM_ SG_ 101 ivi_ASCMoveModeControl "减震器移动模式设置信号";
CM_ SG_ 101 ivi_laneAssistFuncSet "Laneassistfunctionset.";
CM_ SG_ 101 ivi_lasWarningModeSelection "LASWarningModeSet";
CM_ SG_ 101 ivi_EmergencyHvOffRequestReserve "EmergencyHvOffRequest
紧急下电设置预留";
CM_ SG_ 101 ivi_ExhibitionModeCtrl "展车模式开关";
CM_ SG_ 101 ivi_remainningMilModeSet "续航里程显示模式设置(EVR)";
CM_ SG_ 101 ivi_avhOnOffSet "AVHONOFFset.";
CM_ SG_ 101 ivi_pcwOnOffSet "PCWONOFFset.";
CM_ SG_ 101 ivi_TJAFuncSet "TJAfunctionon/off.";
CM_ SG_ 101 IVI_autododgeOnOffSet "智慧躲闪开关";
CM_ SG_ 101 ivi_trailerModeOnOffSet "TrailermodeONOFFset(reserve)";
CM_ SG_ 101 ivi_esc_epbButtonRelease "epbbuttonrelease";
CM_ SG_ 101 IVI_ApaOnOffReq "自定义APA功能激活退出";
CM_ SG_ 152 IVI_drSeatRouteSet "主驾座椅前进后退设置信号";
CM_ SG_ 152 IVI_drSeatbackrestSet "主驾座椅靠背角度设置信号";
CM_ SG_ 152 IVI_drSeatCushionSet "主驾座椅座垫上下设置信号";
CM_ SG_ 152 IVI_drSeatCushionAngleSet "主驾座椅座垫角度设置信号";
CM_ SG_ 152 IVI_LmirrorUDSet "左侧后视镜上下调节";
CM_ SG_ 152 IVI_LmirrorLRSet "左侧后视镜左右调节";
CM_ SG_ 152 IVI_RmirrorUDSet "右侧后视镜上下调节";
CM_ SG_ 152 IVI_RmirrorLRSet "右侧后视镜左右调节";
CM_ SG_ 152 IVI_DSMChargeCtrl "主驾充电控制";
CM_ SG_ 147 IVI_PassSeatRouteSet "副驾座椅前进后退设置信号";
CM_ SG_ 147 IVI_PassSeatbackrestSet "副驾座椅靠背角度设置信号";
CM_ SG_ 147 IVI_PassSeatCushionSet "副驾座椅座垫上下设置信号";
CM_ SG_ 147 IVI_PassSeatCushionAngleSet "副驾座椅座垫角度设置信号";
CM_ SG_ 147 IVI_PSMChargeCtrl "副驾充电控制";
CM_ SG_ 151 IVI_ALCThemeModeSet "IVI_ALCThemeModeSet
氛围灯主题设置";
CM_ SG_ 151 IVI_DOWALCWarnningSet "开门预警控制氛围灯开关";
CM_ SG_ 151 IVI_easyEntryALCWarnningSet "迎宾控制氛围开关";
CM_ SG_ 151 IVI_ALCSwithCtrl "IVI_ALCSwithCtrl
氛围灯开关";
CM_ SG_ 151 IVI_BreathFrequency "固定色呼吸频率调节";
CM_ SG_ 151 IVI_NavigationTurnSet "IVI_NavigationTurnSet
氛围灯导航开关";
CM_ SG_ 151 IVI_BSDWarnningSet "IVI_BSDWarnningSet";
CM_ SG_ 151 IVI_vehicleWarnningSet "A类报警提示控制氛围灯开关";
CM_ SG_ 151 IVI_BlueToothSet "IVI_BlueToothSet
氛围灯蓝牙开关";
CM_ SG_ 151 IVI_FatigueReminderSet "IVI_FatigueReminderSet
疲劳提醒开关";
CM_ SG_ 151 ivi_IVIthemeSet "IVI主题设置";
CM_ SG_ 151 IVI_driveModeALCctrltset "切换驾驶模式控制氛围灯开关";
CM_ SG_ 151 IVI_ALCAplLuminance "IVI_ALCAplLuminance
氛围灯亮度设置";
CM_ SG_ 151 IVI_VAP_FragranceCtrlReq "香氛状态控制请求";
CM_ SG_ 151 IVI_FragrancePositionSet "香氛位置设置";
CM_ SG_ 151 IVI_FragranceConcentrationSet "香氛浓度设置";
CM_ SG_ 151 IVI_ALCAImodeSet "氛围灯AI模式开关";
CM_ SG_ 151 IVI_ALCTemperatureSwithCtrl "氛围灯温度变化开关";
CM_ SG_ 151 IVI_ACTempALCReq "温度变化设置";
BA_DEF_ BO_  "GenMsgSendType" ENUM  "Cycle","Event","CE";
BA_DEF_ BO_  "GenMsgCycleTime" INT 0 0;
BA_DEF_ SG_  "GenSigSendType" ENUM  "Cycle","OnChange","OnWrite","IfActive","OnChangeWithRepetition","OnWriteWithRepetition","IfActiveWithRepetition";
BA_DEF_ SG_  "GenSigStartValue" INT 0 0;
BA_DEF_ SG_  "SystemSignalLongSymbol" STRING ;
BA_DEF_DEF_  "GenMsgSendType" "Cycle";
BA_DEF_DEF_  "GenMsgCycleTime" 0;
BA_DEF_DEF_  "GenSigSendType" "Cycle";
BA_DEF_DEF_  "GenSigStartValue" 0;
BA_DEF_DEF_  "SystemSignalLongSymbol" "";
BA_ "GenMsgCycleTime" BO_ 863 100;
BA_ "GenMsgCycleTime" BO_ 1300 500;
BA_ "GenMsgCycleTime" BO_ 1396 1000;
BA_ "GenMsgCycleTime" BO_ 1377 1000;
BA_ "GenMsgCycleTime" BO_ 849 100;
BA_ "GenMsgCycleTime" BO_ 273 10;
BA_ "GenMsgCycleTime" BO_ 1302 500;
BA_ "GenMsgCycleTime" BO_ 903 100;
BA_ "GenMsgCycleTime" BO_ 909 100;
BA_ "GenMsgCycleTime" BO_ 777 100;
BA_ "GenMsgCycleTime" BO_ 906 100;
BA_ "GenMsgCycleTime" BO_ 772 100;
BA_ "GenMsgCycleTime" BO_ 817 100;
BA_ "GenMsgSendType" BO_ 2015 1;
BA_ "GenMsgCycleTime" BO_ 1267 200;
BA_ "GenMsgCycleTime" BO_ 769 100;
BA_ "GenMsgCycleTime" BO_ 816 100;
BA_ "GenMsgCycleTime" BO_ 932 100;
BA_ "GenMsgCycleTime" BO_ 929 100;
BA_ "GenMsgCycleTime" BO_ 292 10;
BA_ "GenMsgCycleTime" BO_ 324 10;
BA_ "GenMsgCycleTime" BO_ 322 10;
BA_ "GenMsgCycleTime" BO_ 290 10;
BA_ "GenMsgCycleTime" BO_ 530 20;
BA_ "GenMsgCycleTime" BO_ 674 20;
BA_ "GenMsgCycleTime" BO_ 594 20;
BA_ "GenMsgCycleTime" BO_ 1019 100;
BA_ "GenMsgCycleTime" BO_ 706 20;
BA_ "GenMsgCycleTime" BO_ 537 20;
BA_ "GenMsgCycleTime" BO_ 569 20;
BA_ "GenMsgCycleTime" BO_ 841 100;
BA_ "GenMsgCycleTime" BO_ 873 100;
BA_ "GenMsgCycleTime" BO_ 846 100;
BA_ "GenMsgCycleTime" BO_ 847 100;
BA_ "GenMsgCycleTime" BO_ 853 100;
BA_ "GenMsgCycleTime" BO_ 854 100;
BA_ "GenMsgCycleTime" BO_ 538 20;
BA_ "GenMsgCycleTime" BO_ 858 100;
BA_ "GenMsgCycleTime" BO_ 857 100;
BA_ "GenMsgCycleTime" BO_ 555 20;
BA_ "GenMsgCycleTime" BO_ 896 100;
BA_ "GenMsgCycleTime" BO_ 859 100;
BA_ "GenMsgCycleTime" BO_ 1032 200;
BA_ "GenMsgSendType" BO_ 230 1;
BA_ "GenMsgSendType" BO_ 231 1;
BA_ "GenMsgSendType" BO_ 233 1;
BA_ "GenMsgSendType" BO_ 234 1;
BA_ "GenMsgCycleTime" BO_ 992 100;
BA_ "GenMsgSendType" BO_ 225 1;
BA_ "GenMsgSendType" BO_ 226 1;
BA_ "GenMsgSendType" BO_ 228 1;
BA_ "GenMsgSendType" BO_ 227 1;
BA_ "GenMsgCycleTime" BO_ 945 100;
BA_ "GenMsgCycleTime" BO_ 839 100;
BA_ "GenMsgCycleTime" BO_ 885 100;
BA_ "GenMsgCycleTime" BO_ 886 100;
BA_ "GenMsgCycleTime" BO_ 950 100;
BA_ "GenMsgCycleTime" BO_ 673 20;
BA_ "GenMsgCycleTime" BO_ 961 100;
BA_ "GenMsgCycleTime" BO_ 962 100;
BA_ "GenMsgCycleTime" BO_ 1041 200;
BA_ "GenMsgCycleTime" BO_ 1057 200;
BA_ "GenMsgCycleTime" BO_ 705 20;
BA_ "GenMsgCycleTime" BO_ 977 100;
BA_ "GenMsgCycleTime" BO_ 1475 1000;
BA_ "GenMsgSendType" BO_ 150 1;
BA_ "GenMsgCycleTime" BO_ 810 100;
BA_ "GenMsgCycleTime" BO_ 916 100;
BA_ "GenMsgCycleTime" BO_ 981 100;
BA_ "GenMsgCycleTime" BO_ 982 100;
BA_ "GenMsgCycleTime" BO_ 980 100;
BA_ "GenMsgCycleTime" BO_ 792 100;
BA_ "GenMsgCycleTime" BO_ 794 100;
BA_ "GenMsgSendType" BO_ 168 1;
BA_ "GenMsgSendType" BO_ 117 1;
BA_ "GenMsgSendType" BO_ 149 1;
BA_ "GenMsgSendType" BO_ 165 1;
BA_ "GenMsgSendType" BO_ 101 1;
BA_ "GenMsgSendType" BO_ 152 1;
BA_ "GenMsgSendType" BO_ 147 1;
BA_ "GenMsgSendType" BO_ 151 1;
BA_ "GenSigStartValue" SG_ 863 tbox_MaxChargeCurrentSet 63;
BA_ "GenSigStartValue" SG_ 863 tbox_MaxChargeSOCSet 127;
BA_ "GenSigStartValue" SG_ 1300 bms_SOC 1023;
BA_ "GenSigStartValue" SG_ 1300 bms_SOCActual 1023;
BA_ "GenSigStartValue" SG_ 1300 bms_maxChargeSOC 100;
BA_ "GenSigStartValue" SG_ 1377 vcu_avgPwr 10000;
BA_ "SystemSignalLongSymbol" SG_ 849 vcu_ComprehensiveRemainingMileag "vcu_ComprehensiveRemainingMileage";
BA_ "GenSigStartValue" SG_ 849 vcu_PwroCrntTrip 500;
BA_ "GenSigStartValue" SG_ 817 vcu_v2vChrgOutCurntFdbk 9;
BA_ "GenSigSendType" SG_ 2015 Diag_FuncReq_Data 1;
BA_ "GenSigStartValue" SG_ 769 vcu_avgPwrCurrentTrip 500;
BA_ "GenSigStartValue" SG_ 769 vcu_avgPwrSincelastcharge 500;
BA_ "GenSigStartValue" SG_ 769 vcu_avgPwroftripA 500;
BA_ "GenSigStartValue" SG_ 769 vcu_PwroftripB 5000;
BA_ "GenSigStartValue" SG_ 769 vcu_avgPwroftripB 500;
BA_ "GenSigStartValue" SG_ 929 vcu_VehicleMode 1;
BA_ "GenSigStartValue" SG_ 929 vcu_RegenModeStatus 3;
BA_ "GenSigStartValue" SG_ 929 vcu_memoryStatus 1;
BA_ "GenSigStartValue" SG_ 322 esc_wheelSpeedFL 8190;
BA_ "GenSigStartValue" SG_ 322 esc_wheelSpeedFLValid 1;
BA_ "GenSigStartValue" SG_ 322 esc_wheelSpeedFR 8190;
BA_ "GenSigStartValue" SG_ 322 esc_wheelSpeedFRValid 1;
BA_ "GenSigStartValue" SG_ 290 esc_wheelSpeedRL 8190;
BA_ "GenSigStartValue" SG_ 290 esc_wheelSpeedRLValid 1;
BA_ "GenSigStartValue" SG_ 290 esc_wheelSpeedRR 8190;
BA_ "GenSigStartValue" SG_ 290 esc_wheelSpeedRRValid 1;
BA_ "GenSigStartValue" SG_ 530 esc_vehicleSpeed 8190;
BA_ "GenSigStartValue" SG_ 530 esc_avhAvailable 1;
BA_ "GenSigStartValue" SG_ 530 esc_offStatus 1;
BA_ "GenSigStartValue" SG_ 530 esc_escFault 1;
BA_ "GenSigStartValue" SG_ 569 mrr_aebOnOffStatus 1;
BA_ "GenSigStartValue" SG_ 858 mpc_LAS_roadCurvature 60;
BA_ "GenSigStartValue" SG_ 858 mpc_LAS_LLaneDistance 19;
BA_ "GenSigStartValue" SG_ 858 mpc_LAS_RLaneDistance 19;
BA_ "GenSigStartValue" SG_ 858 MPC_LLLaneDistance 28;
BA_ "GenSigStartValue" SG_ 858 MPC_RRLaneDistance 28;
BA_ "GenSigStartValue" SG_ 857 MPC_LaneEquationC1 2047;
BA_ "GenSigStartValue" SG_ 857 MPC_LaneEquationC2 2047;
BA_ "GenSigStartValue" SG_ 857 MPC_LaneEquationC3 2047;
BA_ "GenSigStartValue" SG_ 857 MPC_RoadCurvatureNear 60;
BA_ "GenSigStartValue" SG_ 857 MPC_RoadCurvatureFar 60;
BA_ "GenSigStartValue" SG_ 1032 ivi_currentRoadType 15;
BA_ "GenSigStartValue" SG_ 1032 ivi_NAVIcameraspeedLimitvalueVal 1;
BA_ "SystemSignalLongSymbol" SG_ 1032 ivi_NAVIcameraspeedLimitvalueVal "ivi_NAVIcameraspeedLimitvalueValid";
BA_ "GenSigStartValue" SG_ 1032 ivi_NAVIspeedLimitvalueValid 1;
BA_ "GenSigStartValue" SG_ 1032 ivi_NAVIStaus 1;
BA_ "GenSigSendType" SG_ 230 IVI_CH0_CH1_VOL_STEP 1;
BA_ "GenSigStartValue" SG_ 230 IVI_CH0_CH1_VOL_STEP 35;
BA_ "GenSigSendType" SG_ 230 IVI_CH2_VOL_STEP 1;
BA_ "GenSigStartValue" SG_ 230 IVI_CH2_VOL_STEP 25;
BA_ "GenSigSendType" SG_ 230 IVI_CH3_VOL_STEP 1;
BA_ "GenSigStartValue" SG_ 230 IVI_CH3_VOL_STEP 35;
BA_ "GenSigSendType" SG_ 230 IVI_CH4_VOL_STEP 1;
BA_ "GenSigStartValue" SG_ 230 IVI_CH4_VOL_STEP 35;
BA_ "GenSigSendType" SG_ 230 IVI_CH5_VOL_STEP 1;
BA_ "GenSigStartValue" SG_ 230 IVI_CH5_VOL_STEP 35;
BA_ "GenSigSendType" SG_ 230 IVI_CH6_VOL_STEP 1;
BA_ "GenSigStartValue" SG_ 230 IVI_CH6_VOL_STEP 35;
BA_ "GenSigSendType" SG_ 230 IVI_CH7_VOL_STEP 1;
BA_ "GenSigSendType" SG_ 230 IVI_CH0_CH1_MUTE 1;
BA_ "GenSigSendType" SG_ 230 IVI_CH2_MUTE 1;
BA_ "GenSigSendType" SG_ 230 IVI_CH3_MUTE 1;
BA_ "GenSigSendType" SG_ 230 IVI_CH4_MUTE 1;
BA_ "GenSigSendType" SG_ 230 IVI_CH5_MUTE 1;
BA_ "GenSigSendType" SG_ 230 IVI_CH6_MUTE 1;
BA_ "GenSigSendType" SG_ 230 IVI_CH7_MUTE 1;
BA_ "GenSigSendType" SG_ 230 IVI_CH8_MUTE 1;
BA_ "GenSigSendType" SG_ 230 IVI_CH9_MUTE 1;
BA_ "GenSigSendType" SG_ 230 IVI_CH10_CH15_MUTE 1;
BA_ "GenSigSendType" SG_ 231 IVI_CH8_VOL_STEP 1;
BA_ "GenSigSendType" SG_ 231 IVI_CH9_VOL_STEP 1;
BA_ "GenSigSendType" SG_ 231 IVI_CH10_CH15_VOL_STEP 1;
BA_ "GenSigSendType" SG_ 231 IVI_CH0_CH1_OMP_STEP 1;
BA_ "GenSigStartValue" SG_ 231 IVI_CH0_CH1_OMP_STEP 25;
BA_ "GenSigSendType" SG_ 233 IVI_SOUND_FADE 1;
BA_ "GenSigStartValue" SG_ 233 IVI_SOUND_FADE 7;
BA_ "GenSigSendType" SG_ 233 IVI_SOUND_BAL 1;
BA_ "GenSigStartValue" SG_ 233 IVI_SOUND_BAL 7;
BA_ "GenSigSendType" SG_ 233 IVI_ATMOS_MOD_TYPE 1;
BA_ "GenSigStartValue" SG_ 233 IVI_ATMOS_MOD_TYPE 1;
BA_ "GenSigSendType" SG_ 233 IVI_VOL_SPEED_SW 1;
BA_ "GenSigStartValue" SG_ 233 IVI_VOL_SPEED_SW 1;
BA_ "GenSigSendType" SG_ 233 IVI_ESE_MOD_SW 1;
BA_ "GenSigStartValue" SG_ 233 IVI_ESE_MOD_SW 1;
BA_ "GenSigSendType" SG_ 233 IVI_ESE_MOD_TYPE 1;
BA_ "GenSigStartValue" SG_ 233 IVI_ESE_MOD_TYPE 1;
BA_ "GenSigSendType" SG_ 233 IVI_ESE_VOL 1;
BA_ "GenSigStartValue" SG_ 233 IVI_ESE_VOL 1;
BA_ "GenSigSendType" SG_ 233 IVI_PED_ALARM 1;
BA_ "GenSigStartValue" SG_ 233 IVI_PED_ALARM 1;
BA_ "GenSigSendType" SG_ 233 IVI_UNLOCK_SW 1;
BA_ "GenSigStartValue" SG_ 233 IVI_UNLOCK_SW 1;
BA_ "GenSigSendType" SG_ 233 IVI_LOCK_SW 1;
BA_ "GenSigStartValue" SG_ 233 IVI_LOCK_SW 1;
BA_ "GenSigSendType" SG_ 233 IVI_OMP_Switch 1;
BA_ "GenSigStartValue" SG_ 233 IVI_OMP_Switch 1;
BA_ "GenSigSendType" SG_ 233 IVI_HRS_MODE_TYPE 1;
BA_ "GenSigSendType" SG_ 233 IVI_ECALL_STATUS 1;
BA_ "GenSigSendType" SG_ 234 IVI_GEQ_GAIN_BAND_1 1;
BA_ "GenSigStartValue" SG_ 234 IVI_GEQ_GAIN_BAND_1 7;
BA_ "GenSigSendType" SG_ 234 IVI_GEQ_GAIN_BAND_2 1;
BA_ "GenSigStartValue" SG_ 234 IVI_GEQ_GAIN_BAND_2 7;
BA_ "GenSigSendType" SG_ 234 IVI_GEQ_GAIN_BAND_3 1;
BA_ "GenSigStartValue" SG_ 234 IVI_GEQ_GAIN_BAND_3 7;
BA_ "GenSigSendType" SG_ 234 IVI_GEQ_GAIN_BAND_4 1;
BA_ "GenSigStartValue" SG_ 234 IVI_GEQ_GAIN_BAND_4 7;
BA_ "GenSigSendType" SG_ 234 IVI_GEQ_GAIN_BAND_5 1;
BA_ "GenSigStartValue" SG_ 234 IVI_GEQ_GAIN_BAND_5 7;
BA_ "GenSigSendType" SG_ 234 IVI_GEQ_GAIN_BAND_6 1;
BA_ "GenSigStartValue" SG_ 234 IVI_GEQ_GAIN_BAND_6 7;
BA_ "GenSigSendType" SG_ 234 IVI_GEQ_GAIN_BAND_7 1;
BA_ "GenSigStartValue" SG_ 234 IVI_GEQ_GAIN_BAND_7 7;
BA_ "GenSigStartValue" SG_ 992 EPA_WORK_STS 1;
BA_ "GenSigSendType" SG_ 225 EPA_CH0_CH1_VOL_STEP_STS 1;
BA_ "GenSigStartValue" SG_ 225 EPA_CH0_CH1_VOL_STEP_STS 35;
BA_ "GenSigSendType" SG_ 225 EPA_CH2_VOL_STEP_STS 1;
BA_ "GenSigStartValue" SG_ 225 EPA_CH2_VOL_STEP_STS 25;
BA_ "GenSigSendType" SG_ 225 EPA_CH3_VOL_STEP_STS 1;
BA_ "GenSigStartValue" SG_ 225 EPA_CH3_VOL_STEP_STS 35;
BA_ "GenSigSendType" SG_ 225 EPA_CH4_VOL_STEP_STS 1;
BA_ "GenSigStartValue" SG_ 225 EPA_CH4_VOL_STEP_STS 35;
BA_ "GenSigSendType" SG_ 225 EPA_CH5_VOL_STEP_STS 1;
BA_ "GenSigStartValue" SG_ 225 EPA_CH5_VOL_STEP_STS 35;
BA_ "GenSigSendType" SG_ 225 EPA_CH6_VOL_STEP_STS 1;
BA_ "GenSigStartValue" SG_ 225 EPA_CH6_VOL_STEP_STS 35;
BA_ "GenSigSendType" SG_ 225 EPA_CH7_VOL_STEP_STS 1;
BA_ "GenSigSendType" SG_ 225 EPA_CH0_CH1_MUTE_STS 1;
BA_ "GenSigSendType" SG_ 225 EPA_CH2_MUTE_STS 1;
BA_ "GenSigSendType" SG_ 225 EPA_CH3_MUTE_STS 1;
BA_ "GenSigSendType" SG_ 225 EPA_CH4_MUTE_STS 1;
BA_ "GenSigSendType" SG_ 225 EPA_CH5_MUTE_STS 1;
BA_ "GenSigSendType" SG_ 225 EPA_CH6_MUTE_STS 1;
BA_ "GenSigSendType" SG_ 225 EPA_CH7_MUTE_STS 1;
BA_ "GenSigSendType" SG_ 225 EPA_CH8_MUTE_STS 1;
BA_ "GenSigSendType" SG_ 225 EPA_CH9_MUTE_STS 1;
BA_ "GenSigSendType" SG_ 225 EPA_CH10_CH15_MUTE_STS 1;
BA_ "GenSigSendType" SG_ 226 EPA_CH8_VOL_STEP_STS 1;
BA_ "GenSigSendType" SG_ 226 EPA_CH9_VOL_STEP_STS 1;
BA_ "GenSigSendType" SG_ 226 EPA_CH10_CH15_VOL_STEP_STS 1;
BA_ "GenSigSendType" SG_ 226 EPA_CH0_CH1_OMP_STEP_STS 1;
BA_ "GenSigStartValue" SG_ 226 EPA_CH0_CH1_OMP_STEP_STS 25;
BA_ "GenSigSendType" SG_ 228 EPA_SOUND_FADE_STATUS 1;
BA_ "GenSigStartValue" SG_ 228 EPA_SOUND_FADE_STATUS 7;
BA_ "GenSigSendType" SG_ 228 EPA_SOUND_BAL_STATUS 1;
BA_ "GenSigStartValue" SG_ 228 EPA_SOUND_BAL_STATUS 7;
BA_ "GenSigSendType" SG_ 228 EPA_ATMOS_MOD_TYPE_STATUS 1;
BA_ "GenSigStartValue" SG_ 228 EPA_ATMOS_MOD_TYPE_STATUS 1;
BA_ "GenSigSendType" SG_ 228 EPA_VOL_SPEED_SW_STATUS 1;
BA_ "GenSigStartValue" SG_ 228 EPA_VOL_SPEED_SW_STATUS 1;
BA_ "GenSigSendType" SG_ 228 EPA_PED_ALARM_STATUS 1;
BA_ "GenSigStartValue" SG_ 228 EPA_PED_ALARM_STATUS 1;
BA_ "GenSigSendType" SG_ 228 EPA_ESE_MOD_TYPE_STATUS 1;
BA_ "GenSigStartValue" SG_ 228 EPA_ESE_MOD_TYPE_STATUS 1;
BA_ "GenSigSendType" SG_ 228 EPA_ESE_VOL_STATUS 1;
BA_ "GenSigStartValue" SG_ 228 EPA_ESE_VOL_STATUS 1;
BA_ "GenSigSendType" SG_ 228 EPA_UNLOCK_SW_STATUS 1;
BA_ "GenSigStartValue" SG_ 228 EPA_UNLOCK_SW_STATUS 1;
BA_ "GenSigSendType" SG_ 228 EPA_LOCK_SW_STATUS 1;
BA_ "GenSigStartValue" SG_ 228 EPA_LOCK_SW_STATUS 1;
BA_ "GenSigSendType" SG_ 228 EPA_HRS_MODE_TYPE_STATUS 1;
BA_ "GenSigSendType" SG_ 228 EPA_OMP_Switch_STATUS 1;
BA_ "GenSigSendType" SG_ 228 EPA_ESE_MOD_SW_STATUS 1;
BA_ "GenSigSendType" SG_ 227 EPA_GEQ_GAIN_BAND_1 1;
BA_ "GenSigSendType" SG_ 227 EPA_GEQ_GAIN_BAND_2 1;
BA_ "GenSigSendType" SG_ 227 EPA_GEQ_GAIN_BAND_3 1;
BA_ "GenSigSendType" SG_ 227 EPA_GEQ_GAIN_BAND_4 1;
BA_ "GenSigSendType" SG_ 227 EPA_GEQ_GAIN_BAND_5 1;
BA_ "GenSigSendType" SG_ 227 EPA_GEQ_GAIN_BAND_6 1;
BA_ "GenSigSendType" SG_ 227 EPA_GEQ_GAIN_BAND_7 1;
BA_ "GenSigStartValue" SG_ 885 BLE_User_ID 65535;
BA_ "GenSigStartValue" SG_ 886 IVI_User_ID 65535;
BA_ "SystemSignalLongSymbol" SG_ 950 AC_InigentizePurificationStSwitc "AC_InigentizePurificationStSwitch";
BA_ "SystemSignalLongSymbol" SG_ 673 BCM_cruiseHeadway_increase_KeySt "BCM_cruiseHeadway_increase_KeySts";
BA_ "SystemSignalLongSymbol" SG_ 673 BCM_cruiseHeadway_increase__0000 "BCM_cruiseHeadway_increase_KeyStsValid";
BA_ "SystemSignalLongSymbol" SG_ 673 BCM_cruiseHeadway_decrease_KeySt "BCM_cruiseHeadway_decrease_KeySts";
BA_ "SystemSignalLongSymbol" SG_ 673 BCM_cruiseHeadway_decrease__0000 "BCM_cruiseHeadway_decrease_KeyStsValid";
BA_ "GenSigStartValue" SG_ 961 bcm_rsmSolarRight 254;
BA_ "GenSigStartValue" SG_ 961 bcm_rsmSolarLeft 254;
BA_ "GenSigStartValue" SG_ 705 bcm_followMeHomeFedb 3;
BA_ "GenSigSendType" SG_ 150 IVI_danceOnOffSet 1;
BA_ "GenSigSendType" SG_ 150 IVI_unlockAnimatSet 1;
BA_ "GenSigSendType" SG_ 150 IVI_lockAnimatSet 1;
BA_ "GenSigSendType" SG_ 150 IVI_FLWINOpenDegreeReq 1;
BA_ "GenSigSendType" SG_ 150 IVI_FRWINOpenDegreeReq 1;
BA_ "GenSigSendType" SG_ 150 IVI_RLWINOpenDegreeReq 1;
BA_ "GenSigSendType" SG_ 150 IVI_RRWINOpenDegreeReq 1;
BA_ "GenSigSendType" SG_ 150 IVI_BCMlockSoundSet 1;
BA_ "GenSigSendType" SG_ 150 IVI_LockCloseWinSet 1;
BA_ "GenSigSendType" SG_ 150 IVI_SterringWheelHeatSw 1;
BA_ "GenSigStartValue" SG_ 981 DSM_easyEntryStatus 1;
BA_ "GenSigStartValue" SG_ 981 DSM_MirrorAutoTurnDownStatus 1;
BA_ "GenSigSendType" SG_ 168 tbox_remotePetModeReq 1;
BA_ "GenSigSendType" SG_ 168 TBOX_SentryReq 1;
BA_ "GenSigSendType" SG_ 168 TBOX_TakeVideoPosReq 1;
BA_ "GenSigSendType" SG_ 168 TBOX_TakePhotoReq 1;
BA_ "GenSigSendType" SG_ 168 TBOX_SentryTimeSet 1;
BA_ "GenSigSendType" SG_ 168 TBOX_CarSearchReq 1;
BA_ "GenSigSendType" SG_ 117 ivi_childLockCtrl 1;
BA_ "GenSigSendType" SG_ 117 ivi_centralLockCtrl 1;
BA_ "GenSigSendType" SG_ 117 ivi_fuelPortCapOpenCtrl 1;
BA_ "GenSigSendType" SG_ 117 ivi_lowBeamOnOffCtrl 1;
BA_ "GenSigSendType" SG_ 117 ivi_v2vChrgOnOffSet 1;
BA_ "GenSigSendType" SG_ 117 ivi_obcDschrgOnOffSet 1;
BA_ "GenSigSendType" SG_ 117 ivi_rearFogLampOnOffCtrl 1;
BA_ "GenSigSendType" SG_ 117 ivi_chrgPortCapOpenCtrl 1;
BA_ "GenSigSendType" SG_ 117 ivi_NormalHvOffRequest 1;
BA_ "GenSigSendType" SG_ 117 ivi_tailgateCtrl 1;
BA_ "GenSigSendType" SG_ 117 ivi_MirrorSw 1;
BA_ "GenSigSendType" SG_ 117 ivi_rearDefrostCtrl 1;
BA_ "GenSigSendType" SG_ 117 ivi_MaxFuelConsumptionSW 1;
BA_ "GenSigSendType" SG_ 117 ivi_MaxFuelConsumptionModeSW 1;
BA_ "GenSigSendType" SG_ 117 ivi_v2vChrgOptCurntSet 1;
BA_ "GenSigSendType" SG_ 117 ivi_approachingUnlockCtrl 1;
BA_ "GenSigSendType" SG_ 117 ivi_awayLockCtrl 1;
BA_ "GenSigSendType" SG_ 117 ivi_wipperMaintModeCtrl 1;
BA_ "GenSigSendType" SG_ 117 ivi_modememory 1;
BA_ "GenSigSendType" SG_ 149 IVI_NozzleHeatingSw 1;
BA_ "GenSigSendType" SG_ 149 IVI_OneKeyModeSet 1;
BA_ "GenSigSendType" SG_ 149 ivi_limitmodeset 1;
BA_ "GenSigSendType" SG_ 149 ivi_doorTopSwitch 1;
BA_ "GenSigSendType" SG_ 149 ivi_rvMirrorAutoTurnDownSet 1;
BA_ "GenSigSendType" SG_ 149 ivi_followMeHomeSet 1;
BA_ "GenSigSendType" SG_ 149 ivi_WinLFCtrlRqst 1;
BA_ "GenSigSendType" SG_ 149 ivi_WinRFCtrlRqst 1;
BA_ "GenSigSendType" SG_ 149 ivi_WinLRCtrlRqst 1;
BA_ "GenSigSendType" SG_ 149 ivi_WinRRCtrlRqst 1;
BA_ "GenSigSendType" SG_ 149 ivi_childLockRLCtrl 1;
BA_ "GenSigSendType" SG_ 149 ivi_childLockRRCtrl 1;
BA_ "GenSigSendType" SG_ 149 ivi_DriveDoorUnlockCtrl 1;
BA_ "GenSigSendType" SG_ 149 IVI_AutoDrySet 1;
BA_ "GenSigSendType" SG_ 165 ivi_TripAReset 1;
BA_ "GenSigSendType" SG_ 165 ivi_TripBReset 1;
BA_ "GenSigSendType" SG_ 165 ivi_VehicleModeSet 1;
BA_ "GenSigSendType" SG_ 165 ivi_RegenModeSet 1;
BA_ "GenSigSendType" SG_ 165 ivi_traveModeSet 1;
BA_ "GenSigSendType" SG_ 165 ivi_ChargeControl 1;
BA_ "GenSigSendType" SG_ 165 ivi_ParkingChargeReq 1;
BA_ "GenSigSendType" SG_ 165 ivi_TowModeSet 1;
BA_ "GenSigSendType" SG_ 165 ivi_maxChrgSocSet 1;
BA_ "GenSigSendType" SG_ 165 ivi_chargeFormSet 1;
BA_ "GenSigSendType" SG_ 165 ivi_ParkingChargeModeSet 1;
BA_ "GenSigSendType" SG_ 165 ivi_chargeSetValid 1;
BA_ "GenSigSendType" SG_ 165 ivi_ChargeEndTimeHour 1;
BA_ "GenSigSendType" SG_ 165 ivi_ChargeStartTimeHour 1;
BA_ "GenSigSendType" SG_ 165 ivi_ChargeEndTimeMinute 1;
BA_ "GenSigSendType" SG_ 165 ivi_ChargeStartTimeMinute 1;
BA_ "GenSigSendType" SG_ 165 ivi_ResetCurrentTrip 1;
BA_ "GenSigSendType" SG_ 165 IVI_AcFullChargeToWarmSet 1;
BA_ "GenSigSendType" SG_ 165 ivi_ChargeEndTimeValid 1;
BA_ "GenSigSendType" SG_ 165 ivi_ChargeStartTimeValid 1;
BA_ "GenSigSendType" SG_ 165 ivi_driveModeSet 1;
BA_ "GenSigSendType" SG_ 101 ivi_epsModeSet 1;
BA_ "GenSigSendType" SG_ 101 ivi_escOffSw 1;
BA_ "GenSigSendType" SG_ 101 ivi_hdcOnOffSet 1;
BA_ "GenSigSendType" SG_ 101 ivi_aebOnOffSet 1;
BA_ "GenSigSendType" SG_ 101 ivi_iBModeSet 1;
BA_ "GenSigStartValue" SG_ 101 ivi_iBModeSet 1;
BA_ "GenSigSendType" SG_ 101 ivi_lcaBsdOnOffSet 1;
BA_ "GenSigSendType" SG_ 101 ivi_rctaOnOffSetReserved 1;
BA_ "GenSigSendType" SG_ 101 ivi_dowOnOffSet 1;
BA_ "GenSigSendType" SG_ 101 ivi_StartRevSOCSet 1;
BA_ "GenSigSendType" SG_ 101 ivi_hmaOnOffSet 1;
BA_ "GenSigSendType" SG_ 101 ivi_speedLimitOnOffSet 1;
BA_ "GenSigSendType" SG_ 101 IVI_HVDownRepairMode 1;
BA_ "GenSigSendType" SG_ 101 ivi_ASCHeightModeSelected 1;
BA_ "GenSigSendType" SG_ 101 ivi_ASCMoveModeControl 1;
BA_ "GenSigSendType" SG_ 101 ivi_laneAssistFuncSet 1;
BA_ "GenSigSendType" SG_ 101 ivi_lasWarningModeSelection 1;
BA_ "GenSigSendType" SG_ 101 ivi_EmergencyHvOffRequestReserve 1;
BA_ "SystemSignalLongSymbol" SG_ 101 ivi_EmergencyHvOffRequestReserve "ivi_EmergencyHvOffRequestReserved";
BA_ "GenSigSendType" SG_ 101 ivi_ExhibitionModeCtrl 1;
BA_ "GenSigSendType" SG_ 101 ivi_remainningMilModeSet 1;
BA_ "GenSigSendType" SG_ 101 ivi_avhOnOffSet 1;
BA_ "GenSigSendType" SG_ 101 ivi_pcwOnOffSet 1;
BA_ "GenSigSendType" SG_ 101 ivi_TJAFuncSet 1;
BA_ "GenSigSendType" SG_ 101 IVI_autododgeOnOffSet 1;
BA_ "GenSigSendType" SG_ 101 ivi_trailerModeOnOffSet 1;
BA_ "GenSigSendType" SG_ 101 ivi_esc_epbButtonRelease 1;
BA_ "GenSigSendType" SG_ 101 IVI_ApaOnOffReq 1;
BA_ "GenSigSendType" SG_ 152 IVI_drSeatRouteSet 1;
BA_ "GenSigSendType" SG_ 152 IVI_drSeatbackrestSet 1;
BA_ "GenSigSendType" SG_ 152 IVI_drSeatCushionSet 1;
BA_ "GenSigSendType" SG_ 152 IVI_drSeatCushionAngleSet 1;
BA_ "GenSigSendType" SG_ 152 IVI_LmirrorUDSet 1;
BA_ "GenSigSendType" SG_ 152 IVI_LmirrorLRSet 1;
BA_ "GenSigSendType" SG_ 152 IVI_RmirrorUDSet 1;
BA_ "GenSigSendType" SG_ 152 IVI_RmirrorLRSet 1;
BA_ "GenSigSendType" SG_ 152 IVI_DSMChargeCtrl 1;
BA_ "GenSigSendType" SG_ 147 IVI_PassSeatRouteSet 1;
BA_ "GenSigSendType" SG_ 147 IVI_PassSeatbackrestSet 1;
BA_ "GenSigSendType" SG_ 147 IVI_PassSeatCushionSet 1;
BA_ "GenSigSendType" SG_ 147 IVI_PassSeatCushionAngleSet 1;
BA_ "GenSigSendType" SG_ 147 IVI_PSMChargeCtrl 1;
BA_ "GenSigSendType" SG_ 151 IVI_ALCThemeModeSet 1;
BA_ "GenSigSendType" SG_ 151 IVI_DOWALCWarnningSet 1;
BA_ "GenSigSendType" SG_ 151 IVI_easyEntryALCWarnningSet 1;
BA_ "GenSigSendType" SG_ 151 IVI_ALCSwithCtrl 1;
BA_ "GenSigSendType" SG_ 151 IVI_BreathFrequency 1;
BA_ "GenSigSendType" SG_ 151 IVI_NavigationTurnSet 1;
BA_ "GenSigSendType" SG_ 151 IVI_BSDWarnningSet 1;
BA_ "GenSigSendType" SG_ 151 IVI_vehicleWarnningSet 1;
BA_ "GenSigSendType" SG_ 151 IVI_BlueToothSet 1;
BA_ "GenSigSendType" SG_ 151 IVI_FatigueReminderSet 1;
BA_ "GenSigSendType" SG_ 151 ivi_IVIthemeSet 1;
BA_ "GenSigSendType" SG_ 151 IVI_driveModeALCctrltset 1;
BA_ "GenSigSendType" SG_ 151 IVI_ALCAplLuminance 1;
BA_ "GenSigSendType" SG_ 151 IVI_VAP_FragranceCtrlReq 1;
BA_ "GenSigSendType" SG_ 151 IVI_FragrancePositionSet 1;
BA_ "GenSigSendType" SG_ 151 IVI_FragranceConcentrationSet 1;
BA_ "GenSigSendType" SG_ 151 IVI_ALCAImodeSet 1;
BA_ "GenSigSendType" SG_ 151 IVI_ALCTemperatureSwithCtrl 1;
BA_ "GenSigSendType" SG_ 151 IVI_ACTempALCReq 1;
VAL_ 863 tbox_ChargeFormSet 0 "NO_REQUEST" 1 "IMMEDIATE_CHARGE" 2 "TIMING_CHARGE" 3 "RESERVE_CHRGFORM1" ;
VAL_ 863 tbox_ChargeControl 0 "NO_REQUEST" 1 "CANCEL" 2 "ENABLE" 3 "INVALID" ;
VAL_ 863 tbox_MaxChargeSOCSet 127 " INVALID" ;
VAL_ 1300 bms_maxChargeSOC 127 "invalid" ;
VAL_ 1300 BMS_BatterFaultLightContro 0 "OFF" 1 "ON" ;
VAL_ 1300 BMS_BatteryTempLowLight 0 "OFF" 1 "ON" ;
VAL_ 1300 bms_stEgyFlowSysDischRgn 0 "NEUTRAL" 1 "BATTERY_CHARGE充电" 2 " BATTERY_DISCHARGE放电" ;
VAL_ 1300 bms_stEgyFlowOBCAndBatt 0 "NEUTRAL" 1 "OBC_TO_BATTERY" 2 " BATTERY_TO_OBC" ;
VAL_ 1300 bms_chargeFormstatus 0 "IMMEDIATE_CHARGE立即充电" 1 "TIMING_CHARGE预约充电" 2 "RESERVE_CHRGFORM1" 3 "RESERVE_CHRGFORM2" 4 "RESERVE_CHRGFORM3" 5 "RESERVE_CHRGFORM4" 6 "INVALID_CHRGFORM" 7 "Reserved" ;
VAL_ 1377 vcu_alertLevel 0 "NORMAL" 1 "Level1" 2 "Level2" 3 "Level3" ;
VAL_ 1377 VCU_chargeFaultReason 0 "Normal" 1 "车端问题-充电机故障" 2 "车端问题-电池系统故障" 3 "用户操作问题-驻车充电" 4 "车端问题" 5 "桩端问题" 6 "连接问题" 7 "用户操作问题1-双枪故障" 8 "用户操作问题3-插枪未刷卡" 9 "用户操作问题4-到达目标SOC" 10 "reserved" ;
VAL_ 1377 VCU_RegenWeakRemind 0 "No Remind" 1 "Remind" 2 "Reserved" 3 " Invalid" ;
VAL_ 849 vcu_SysAlertLevel 0 "NORMAL" 1 "Level1" 2 "Level2" 3 "Level3" 4 "Level4" 5 "Level5" 6 "Level6" 7 "Level7" 8 "Level8" 9 "Level9" 10 "Level10" 11 "Level11" 12 "Level12" 13 "Reserved" 14 "Reserved" 15 "Level15" ;
VAL_ 849 VCU_PowerLimitLight 0 "OFF" 1 "ON" ;
VAL_ 849 VCU_SysFaultLight 0 "OFF" 1 "ON" ;
VAL_ 849 VCU_LVPowSupSYSAbn_lit 0 "OFF" 1 "ON" ;
VAL_ 849 VCU_UserGearReq 0 "No_Request" 1 "Request" ;
VAL_ 849 VCU_PowerManageSt 0 "Normal" 1 "1级" 2 "2级" 3 " INVALID" ;
VAL_ 273 vcu_BrakeWarning 0 "No_Request" 1 " Request" ;
VAL_ 903 obc_state 0 "INIT" 1 "STANDBY" 2 "AC_CHARGE_MODE" 3 "DC_CHARGE_MODE" 4 "RESERVED1" 5 "RESERVED1" 6 "RESERVED1" 7 "RESERVED1" 8 "RESERVED1" 9 "FAULT" 10 "SLEEP" 11 "V2X" 12 "BATT_WARM电池加热" 13 "RESERVED1" 14 "RESERVED2" 15 " RESERVED3" ;
VAL_ 903 obc_batteryConnectStatus_ 0 "NOT_CONNECTED" 1 " CONNECTED" ;
VAL_ 903 obc_CcResistance 0 "invalid 无效" 1 "UNCONNECT未连接" 2 "HALFCONNECT半连接" 3 "1500 Ohm" 4 "680 Ohm" 5 "220 Ohm" 6 "100 Ohm" 7 "RESERVED" 8 "RESERVED" 9 "2000 Ohm" 10 "RESERVED" 11 "RESERVED" 12 "RESERVED" 13 "RESERVED" 14 "RESERVED" 15 "RESERVED" ;
VAL_ 909 dcdc_systemStatus 0 "DCDC_INIT_STATE 初始化" 1 "DCDC_STANDBY_STATE待机状态" 2 "DCDC_WORK_STATE工作状态" 3 "DCDC308_RES0" 4 "DCDC308_RES1" 5 "DCDC_SLEEP_STATE睡眠" 6 "DCDC_RECV_FAULT_STATE可恢复故障" 7 " DCDC_LOCK_FAULT_STATE锁止故障状态" ;
VAL_ 909 dcdc_deratingStatus 0 "NORMAL" 1 " DERATING" ;
VAL_ 777 gsm_NoticeReq 0 "No_Request" 1 " Request" ;
VAL_ 777 gsm_gearSelectorPos 0 "P" 1 "R" 2 "N" 3 "D" 4 "NO_TARGET" 5 "RESERVE_GSM2" 6 "RESERVE_GSM3" 7 " SENSOR_FAULT" ;
VAL_ 817 vcu_stEgyFlowGenMotAndBatt 0 "Neutral" 1 "Generator motor to Battery" 2 " BMS to Generator motor" ;
VAL_ 817 vcu_stEgyFlowEngAndGenMot 0 "Neutral" 1 "Engine to Generator motor" 2 " Geneator motor to engine" ;
VAL_ 817 VCU_stEgyFlowMcuf0AndBatt 0 "NEUTRAL" 1 "FRONT_MOTOR_TO_BATTERY" 2 " BATTERY_TO_FRONT_MOTOR" ;
VAL_ 817 VCU_stEgyFlowMcur0AndBatt 0 "NEUTRAL" 1 "REAR_MOTOR_TO_BATTERY" 2 " BATTERY_TO_REAR_MOTOR" ;
VAL_ 817 VCU_IVI_HVDownRepairMode 0 "INACTIVE" 1 "OFF" 2 "ON" 3 " INVALID" ;
VAL_ 817 VCU_LowFuel 0 "NO Request" 1 " Request" ;
VAL_ 817 VCU_LowSOC 0 "NO Request" 1 " Request" ;
VAL_ 817 vcu_obcDschrgAllow 0 "Inhibit" 1 "Allow" ;
VAL_ 817 vcu_v2vChrgFdbk 0 "OFF" 1 " ON" ;
VAL_ 817 vcu_obcDschrgFdbk 0 "OFF" 1 " ON" ;
VAL_ 817 vcu_v2vChrgOutCurntFdbk 0 "0" 1 "20" 2 "30" 3 "40" 4 "50" 5 "60" 6 "70" 7 "80" 8 "90" 9 " 100" ;
VAL_ 817 VCU_MaxFuelConsumptionSt 0 "OFF" 1 "ON" ;
VAL_ 817 VCU_MaxFuelConsumptionModeSt 0 "High Speed" 1 "Low Speed" ;
VAL_ 817 vcu_RangeExtenderNoSt 0 "No_request" 1 " Request" ;
VAL_ 769 vcu_lowSocwarming 0 "Normal" 1 "Level 1" 2 "Level 2" 3 "Level 3" ;
VAL_ 769 VCU_SysFaulttext 0 "Normal" 1 "PowerLimit" 2 "SpeedLimit" 3 "PowerCut_Static" 4 "PowerCut_dynamic" 5 "Reserved" 6 "Reserved" 7 " Reserved" ;
VAL_ 816 vcu_v2vChrgAllow 0 "Inhibit" 1 "Allow" ;
VAL_ 816 VCU_PlugCableCapability 0 "未知/未插枪" 1 "10A（国标）" 2 "16A（国标、欧标三相）" 3 "32A（国标、欧标单/三相）" 4 "63A（国标、欧标单/三相）" 5 "20A（欧标单相?）" 6 " 保留" ;
VAL_ 932 BMS_ThrmlRunawaySt 0 "无效" 1 "正常" 2 "热失控故障" 3 "预留" ;
VAL_ 932 BMS_ThrmlForecastersSt 0 "No Active" 1 "Active" ;
VAL_ 932 BMS_AcFullChargeToWarmState 0 "NO_REQUEST" 1 "OFF" 2 "ON" 3 "INVALID" ;
VAL_ 929 vcu_driveMode 0 "ECO" 1 "COMFORT" 2 "SPORT" 3 "FREEDOM_reserve" 4 "ACCELERATE" 5 "RESERVED" 6 "RESERVED" 7 " INVALID" ;
VAL_ 929 vcu_VehicleMode 0 "Inactive" 1 "Electric" 2 "AUTO" 3 " Fuel" ;
VAL_ 929 Vcu_ParkingChargeFB 0 "OFF" 1 " ON" ;
VAL_ 929 Vcu_ParkingChargeModFB 0 "HIGH" 1 "MIDDLE" 2 "LOW" 3 "Reserved" ;
VAL_ 929 vcu_towMode 0 "Inactive" 1 "OFF" 2 "ON" 3 "INVALID" ;
VAL_ 929 vcu_ready 0 "NOT_READY" 1 " READY" ;
VAL_ 929 vcu_traveModeSts 0 "OFF" 1 "WET" 2 "SNOW" 3 " INVALID" ;
VAL_ 929 vcu_highVoltagefaultSts 0 "NORMAL" 1 "FAULT" ;
VAL_ 929 VCU_VehicleRepairModeFB 0 "INACTIVE" 1 "OFF" 2 "ON" 3 " INVALID" ;
VAL_ 929 VCU_VehicleModeSetReq 0 "No Request" 1 "AUTO_FOR_Economy（燃油切自动提高经济性）" 2 "AUTO_FOR_Performance（纯电切自动提高动力）" 3 "AUTO_FOR_AvoidLowTemp（纯电切自动避免低温动力性差）" 4 "由于出现以下情况，车速过高，驾驶过于激烈、环境温度低，已退出强制EV至纯电优先" ;
VAL_ 929 VCU_VehicleModeLOWTempReq 0 "NO Remind" 1 "AUTO" 2 "Fuel" 3 " INVALID" ;
VAL_ 929 VCU_RangeExtenderSt 0 "OFF" 1 "ON" 2 "Reserved" 3 " Reserved" ;
VAL_ 929 vcu_highVoltageSuccess 0 "LOW_VOLT" 1 "HIGH_VOLT_UP" 2 "HIGH_VOLT_DOWNING" 3 "HIGH_VOLT_UPING" 4 "FAILURE_AND_LOW_VOLT" 5 "RESERVE_HIGHVOLT1" 6 "RESERVE_HIGHVOLT2" 7 " RESERVE_HIGHVOLT3" ;
VAL_ 929 vcu_hvOnMode 0 "OFF" 1 "LOCAL" 2 "REMOTE" 3 " INVALID" ;
VAL_ 929 vcu_RegenModeStatus 0 "OFF_Reserved" 1 "NORMAL" 2 "Strong Recovery" 3 " Exstrong" ;
VAL_ 929 vcu_memoryStatus 0 "No_Memory" 1 " Memory" ;
VAL_ 929 VCU_Eng_SelfShieldStart 0 "OFF" 1 " ON" ;
VAL_ 929 VCU_ExhibitionRequest 0 "OFF" 1 " ON" ;
VAL_ 929 vcu_ExhibitionMode 0 "OFF" 1 "ON" 2 "INVALID" 3 " Reserved" ;
VAL_ 292 eps_warningLamp 0 "NORMAL" 1 " FAULT" ;
VAL_ 324 eps_sasSteeringAngleSpdValid 0 "INVALID" 1 " VALID" ;
VAL_ 324 eps_calibratedStatus 0 "NOT_CALIBRATED" 1 " CALIBRATED" ;
VAL_ 324 eps_sasSteeringAngleValid 0 "INVALID" 1 " VALID" ;
VAL_ 322 esc_wheelSpeedFLValid 0 "INVALID" 1 " VALID" ;
VAL_ 322 esc_wheelSpeedFRValid 0 "INVALID" 1 " VALID" ;
VAL_ 290 esc_wheelSpeedRLValid 0 "INVALID" 1 " VALID" ;
VAL_ 290 esc_wheelSpeedRRValid 0 "INVALID" 1 " VALID" ;
VAL_ 530 esc_vehicleSpeedValid 0 "INVALID" 1 " VALID" ;
VAL_ 530 esc_absFault 0 "NORMAL" 1 " FAULT" ;
VAL_ 530 esc_absActive 0 "INACTIVE" 1 " ACTIVE" ;
VAL_ 530 esc_escActive 0 "INACTIVE" 1 " ACTIVE" ;
VAL_ 530 esc_tcsActive 0 "INACTIVE" 1 " ACTIVE" ;
VAL_ 530 esc_avhActive 0 "INACTIVE" 1 " ACTIVE" ;
VAL_ 530 esc_avhStandby 0 "NOT_STANDBY" 1 "STANDBY" ;
VAL_ 530 esc_avhAvailable 0 "NOT_AVAILABLE" 1 " AVAILABLE" ;
VAL_ 530 esc_cdpActive 0 "INACTIVE" 1 " ACTIVE" ;
VAL_ 530 esc_hdcStatus 0 "OFF" 1 "STANDBY" 2 " ACTIVE" ;
VAL_ 530 esc_hdcAvailable 0 "NOT_AVAILABLE" 1 " AVAILABLE" ;
VAL_ 530 esc_hhcAvailable 0 "NOT_AVAILABLE" 1 " AVAILABLE" ;
VAL_ 530 esc_ebdFault 0 "NOMAL" 1 " FAULT" ;
VAL_ 530 esc_offStatus 0 "OFF" 1 " ON" ;
VAL_ 530 esc_escFault 0 "NOMAL" 1 " FAULT" ;
VAL_ 530 esc_emergencyBrakeSts 0 "INACTIVE" 1 " ACTIVE" ;
VAL_ 674 esc_aebActive 0 "INACTIVE" 1 " ACTIVE" ;
VAL_ 674 esc_hmiWarningOn 0 "NO_REQUEST" 1 "YELLOW" 2 "RED" 3 " NOT_AVAILABLE" ;
VAL_ 674 esc_hmiWarningOn_Q 0 "NOT_INITIALIZED" 1 "NORMAL" 2 " FAULTY" ;
VAL_ 594 esc_longAccelerationValid 0 "INVALID" 1 " VALID" ;
VAL_ 594 esc_yawRateValid 0 "INVALID" 1 " VALID" ;
VAL_ 1019 apa_funcSts 0 "Off" 1 "Standby" 2 "Searching" 3 "Guidance active" 4 "Completed Sucessfully" 5 "Failure" 6 "Suspend" 7 " Invalid" ;
VAL_ 706 esc_epbFaultLamp 0 "LAMP_OFF" 1 "LAMP_ON" 2 "LAMP_FLASH" 3 " RESERVED_EPB1" ;
VAL_ 706 esc_epbParkingLamp 0 "LAMP_OFF" 1 "LAMP_ON" 2 "LAMP_FLASH" 3 " RESERVED_EPB2" ;
VAL_ 706 esc_epbTextDisplay 0 "NO_TEXT_MESSAGE" 1 "GRADIENT_TOO_HIGH" 2 "CLAMPFORCE_NOT_ENOUGH" 3 "FASTEN_SEATBELT" 4 "OPEN_PARK_BRAKE_BY_SWITCH" 5 "PRESS_BRAKE_PEDAL" 6 "RESERVED_EPB3" 7 "RESERVED_EPB4" 8 "RESERVED_EPB5" 9 "RESERVED_EPB6" 10 "RESERVED_EPB7" 11 "RESERVED_EPB8" 12 "RESERVED_EPB9" 13 "RESERVED_EPB10" 14 "RESERVED_EPB11" 15 " INVALID" ;
VAL_ 706 esc_epbStatus 0 "DEFAULT" 1 "PARKED" 2 "RELEASED" 3 "PARKING" 4 "RELEASING" 5 "RESERVED_EPB12" 6 "RESERVED_EPB13" 7 " RESERVED_EPB14" ;
VAL_ 706 ESC_BrakeLevelAlarm 0 "NORMAL" 1 "LEVEL_LOW" ;
VAL_ 537 mrr_accMode 0 "OFF_MODE" 1 "PASSIVE_MODE" 2 "STANDBY_MODE" 3 "ACTIVE-CONTROL_MODE" 4 "OVERRIDE" 5 "BRAKE-ONLY_MODE" 6 "RESERVED" 7 " FAILURE_MODE" ;
VAL_ 569 mrr_EBAReq 0 "NO_DEMAND" 1 " DEMAND" ;
VAL_ 569 mrr_aebReq 0 "NO_DEMAND" 1 " DEMAND" ;
VAL_ 569 mrr_aebOnOffStatus 0 "OFF" 1 "ON" 2 "temporary blindness" 3 " FAILURE" ;
VAL_ 569 mrr_accTakeOverReq 0 "NO_TAKEOVER_REQUEST" 1 " VALID_TAKEOVER_REQUEST" ;
VAL_ 569 mrr_PEBSWarning 0 "NO_WARNING" 1 "PreWarning" 2 "RESERVED" 3 "RESERVED" 4 "RESERVED" 5 "RESERVED" 6 "RESERVED" 7 " RESERVED" ;
VAL_ 569 mrr_timeGapSet 0 "TAUGAP_0" 1 "TAUGAP_1" 2 "TAUGAP_2" 3 "TAUGAP_3" 4 "TAUGAP_4" 5 "TAUGAP_5" 6 "TAUGAP_6" 7 " TAUGAP_7" ;
VAL_ 569 mrr_pcwOnOffStatus 0 "OFF" 1 "ON" 2 "temporary blindness" 3 " INVALID" ;
VAL_ 569 mrr_textInfo 0 "无提示" 1 "ACC激活" 2 "请系安全带" 3 "请松手刹" 4 "请挂前进挡" 5 "ACC激活条件不满足" 6 "ACC系统故障" 7 "ACC雷达被遮挡" 8 "ACC已取消" 9 "车辆已起步" 10 "请按下Res或轻踩油门起步" ;
VAL_ 569 mrr_SystemFailureSt 0 "No Error" 1 "temporary failure" 2 "permanent failure" ;
VAL_ 569 mrr_BlockedSt 0 "No blocked" 1 "blocked" ;
VAL_ 841 mrr_ACC_TargetType 0 "SEDAN" 1 "TRUCK" 2 "two wheel" 3 "PEDESTRIAN" 4 "OTHER" 5 "RESERVED" 6 "RESERVED" 7 " INVALID" ;
VAL_ 841 mrr_ACC_TargetDetection 0 "NOT_DETECTED" 1 "IP display" 2 "Front Target" 3 "IACC Target" 4 "AEB Target" 5 "dangerous Target(ELK、UDLC、RCW、etc)" 6 "reserved" 7 "reserved" ;
VAL_ 873 mrr_ACC_LeftTargetType 0 "SEDAN" 1 "TRUCK" 2 "two wheel" 3 "PEDESTRIAN" 4 "OTHER" 5 "RESERVED" 6 "RESERVED" 7 " INVALID" ;
VAL_ 873 mrr_ACC_LeftTargetDetection 0 "NOT_DETECTED" 1 "IP display" 2 "Front Target" 3 "IACC Target" 4 "AEB Target" 5 "dangerous Target(ELK、UDLC、RCW、etc)" 6 "reserved" 7 "reserved" ;
VAL_ 873 mrr_ACC_RightTargetType 0 "SEDAN" 1 "TRUCK" 2 "two wheel" 3 "PEDESTRIAN" 4 "OTHER" 5 "RESERVED" 6 "RESERVED" 7 " INVALID" ;
VAL_ 873 mrr_ACC_RightTargetDetection 0 "NOT_DETECTED" 1 "IP display" 2 "Front Target" 3 "IACC Target" 4 "AEB Target" 5 "dangerous Target(ELK、UDLC、RCW、etc)" 6 "reserved" 7 "reserved" ;
VAL_ 846 mrr_ACC_TargetType2 0 "SEDAN" 1 "TRUCK" 2 "two wheel" 3 "PEDESTRIAN" 4 "OTHER" 5 "RESERVED" 6 "RESERVED" 7 " INVALID" ;
VAL_ 846 mrr_ACC_TargetDetection2 0 "NOT_DETECTED" 1 "IP display" 2 "Front Target" 3 "IACC Target" 4 "AEB Target" 5 "dangerous Target(ELK、UDLC、RCW、etc)" 6 "reserved" 7 "reserved" ;
VAL_ 847 mrr_ACC_LeftTargetType2 0 "SEDAN" 1 "TRUCK" 2 "two wheel" 3 "PEDESTRIAN" 4 "OTHER" 5 "RESERVED" 6 "RESERVED" 7 " INVALID" ;
VAL_ 847 mrr_ACC_LeftTargetDetection2 0 "NOT_DETECTED" 1 "IP display" 2 "Front Target" 3 "IACC Target" 4 "AEB Target" 5 "dangerous Target(ELK、UDLC、RCW、etc)" 6 "reserved" 7 "reserved" ;
VAL_ 847 mrr_ACC_RightTargetType2 0 "SEDAN" 1 "TRUCK" 2 "two wheel" 3 "PEDESTRIAN" 4 "OTHER" 5 "RESERVED" 6 "RESERVED" 7 " INVALID" ;
VAL_ 847 mrr_ACC_RightTargetDetection2 0 "NOT_DETECTED" 1 "IP display" 2 "Front Target" 3 "IACC Target" 4 "AEB Target" 5 "dangerous Target(ELK、UDLC、RCW、etc)" 6 "reserved" 7 "reserved" ;
VAL_ 853 mrr_ACC_TargetType3 0 "SEDAN" 1 "TRUCK" 2 "two wheel" 3 "PEDESTRIAN" 4 "OTHER" 5 "RESERVED" 6 "RESERVED" 7 " INVALID" ;
VAL_ 853 mrr_ACC_TargetDetection3 0 "NOT_DETECTED" 1 "IP display" 2 "Front Target" 3 "IACC Target" 4 "AEB Target" 5 "dangerous Target(ELK、UDLC、RCW、etc)" 6 "reserved" 7 "reserved" ;
VAL_ 854 mrr_ACC_LeftTargetType3 0 "SEDAN" 1 "TRUCK" 2 "two wheel" 3 "PEDESTRIAN" 4 "OTHER" 5 "RESERVED" 6 "RESERVED" 7 " INVALID" ;
VAL_ 854 mrr_ACC_LeftTargetDetection3 0 "NOT_DETECTED" 1 "IP display" 2 "Front Target" 3 "IACC Target" 4 "AEB Target" 5 "dangerous Target(ELK、UDLC、RCW、etc)" 6 "reserved" 7 "reserved" ;
VAL_ 854 mrr_ACC_RightTargetType3 0 "SEDAN" 1 "TRUCK" 2 "two wheel" 3 "PEDESTRIAN" 4 "OTHER" 5 "RESERVED" 6 "RESERVED" 7 " INVALID" ;
VAL_ 854 mrr_ACC_RightTargetDetection3 0 "NOT_DETECTED" 1 "IP display" 2 "Front Target" 3 "IACC Target" 4 "AEB Target" 5 "dangerous Target(ELK、UDLC、RCW、etc)" 6 "reserved" 7 "reserved" ;
VAL_ 538 mpc_leftVisualization 0 "NO_DISPLAY 未检测到车道线" 1 "LINE_TRACKING 检测到车道线" 2 "INTERVENTION 车道辅助干预" 3 " WARNING 车道线报警" ;
VAL_ 538 mpc_rightVisualization 0 "NO_DISPLAY 未检测到车道线" 1 "LINE_TRACKING 检测到车道线" 2 "INTERVENTION 车道辅助干预" 3 " WARNING 车道线报警" ;
VAL_ 538 mpc_laneAssitType 0 "NOT_SELECTED" 1 "LDW" 2 "LDW+RDP" 3 " LDW+LKA（预留）" ;
VAL_ 538 mpc_slaSpeedLimitUnits 0 "UNKNOWN" 1 "KPH" 2 " MPH" ;
VAL_ 538 mpc_lasStatus 0 "NO_INFOMATION" 1 "OFF_ADAS" 2 "STANDBY_ADAS" 3 "ACTIVE_ADAS" 4 "FAULT_ADAS" 5 "reserved" 6 "passive" 7 " RESERVE_ADAS2" ;
VAL_ 538 mpc_lasWarningModeSelection 0 "Only Vision" 1 "Vision+Voice" 2 "reserved" 3 "reserved" 4 "Invalid" 5 "reserved" 6 "reserved" 7 "reserved" ;
VAL_ 538 mpc_IACCStatus 0 "NO_INFOMATION" 1 "OFF" 2 "STANDBY" 3 "ACTIVE" 4 "FAULT" 5 "temp exit" 6 "passive" 7 " DOP" ;
VAL_ 538 mpc_adasTakeoverReq 0 "INACTIVE" 1 "LEVEL1仪表文字+低频声音提示" 2 "LEVEL2仪表文字+高频声音提示" 3 " safetystop" ;
VAL_ 538 mpc_hmaStatus 0 "NO_INFOMATION" 1 "OFF" 2 "PASSIVE" 3 "ACTIVE" 4 "FAULT" 5 "reserved" 6 "reserved" 7 " InValid" ;
VAL_ 538 mpc_hmaHighbeamReq 0 "LOWBEAM_REQUEST" 1 " HIGHBEAM_REQUEST" ;
VAL_ 538 mpc_slaStatus 0 "NO_INFOMATION" 1 "OFF" 2 "FUSION_MODE" 3 "VISION_MODE" 4 "NAVIGATION_MODE" 5 " DEFECT" ;
VAL_ 538 mpc_slaSpeedLimit 0 "NO_DISPLAY" 1 "SPL_5" 2 "SPL_10" 3 "SPL_15" 4 "SPL_20" 5 "SPL_25" 25 "SPL_125" 26 "SPL_130" 27 "SPL_CANCELLED" 28 "SPL_135" 29 "SPL_140" 30 "SPL_145" 31 "SPL_150" 62 "SPL_305" 63 "SPL_310" ;
VAL_ 538 mpc_slaOnOffSts 0 "OFF" 1 "ON" 3 " INVALID" ;
VAL_ 538 mpc_hmaOnOffSts 0 "OFF" 1 "ON" 3 " INVALID" ;
VAL_ 858 mpc_LAS_LLaneMarkerType 0 "DASHED_虚线" 1 "SOLID_实线" 2 "ROAD_EDGE_路沿" 3 "DOUBLELAND_MARK_双线" 4 "BOTTS' DOTS_点线" 5 "OTHER" 6 "RESERVED" 7 " INVALID" ;
VAL_ 858 mpc_LAS_RLaneMarkerType 0 "DASHED_虚线" 1 "SOLID_实线" 2 "ROAD_EDGE_路沿" 3 "DOUBLELAND_MARK_双线" 4 "BOTTS' DOTS_点线" 5 "OTHER" 6 "RESERVED" 7 " INVALID" ;
VAL_ 858 MPC_FrontCameraeStatus 0 "No Error" 1 "camera blocked 致盲" 2 "temporary failure 临时故障" 3 "permanent failure 永久故障" ;
VAL_ 858 MPC_textinfor 0 "NO INDICATION 无提示" 1 "ACTIVATED 已激活" 2 "DRIVER CANCEL 已取消" 3 "AUTOMATIC EXIT FOR CONDITONTIS NOT SATISFLED 条件不满足退出" 4 "ACTIVATION CONDITIONS NOT SATISFLED 激活条件不满足" 5 "后轮压线" 6 "弯道曲率过大" 7 "FUNCTION DISABLED, PLEASE TAKE OVER 脱手至功能禁用（禁用，请接管）" 8 "NOT AVAILABLE FOR MAIN SWITCH OFF 主开关关闭，不可用" 9 "脱手警告未接管，本点火周期车道辅助功能无法激活" 10 "方向盘猛打" 11 "ACC已激活，TJA等待中" 12 "ACC已激活，TJA等待退出" ;
VAL_ 858 MPC_TJAonoffStatus 0 "OFF" 1 "ON" 2 "Reserved" 3 " INVALID" ;
VAL_ 858 MPC_LLLaneMarkerType 0 "DASHED_虚线" 1 "SOLID_实线" 2 "ROAD_EDGE_路沿" 3 "DOUBLELAND_MARK_双线" 4 "BOTTS' DOTS_点线" 5 "OTHER" 6 "RESERVED" 7 " INVALID" ;
VAL_ 858 MPC_RRLaneMarkerType 0 "DASHED_虚线" 1 "SOLID_实线" 2 "ROAD_EDGE_路沿" 3 "DOUBLELAND_MARK_双线" 4 "BOTTS' DOTS_点线" 5 "OTHER" 6 "RESERVED" 7 " INVALID" ;
VAL_ 858 MPC_LleftVisualization 0 "NO_DISPLAY 未检测到车道线" 1 "LINE_TRACKING 检测到车道线" 2 "RESERVED" 3 " RESERVED" ;
VAL_ 858 MPC_RrightVisualization 0 "NO_DISPLAY 未检测到车道线" 1 "LINE_TRACKING 检测到车道线" 2 "RESERVED" 3 " RESERVED" ;
VAL_ 858 MPC_autododgeOnOffSts 0 "INACTIVE" 1 "OFF" 2 "ON" 3 " INVALID " ;
VAL_ 857 MPC_LaneEquationStatus 0 "no display" 1 "Left Lane" 2 "Right Lane" 3 "reserved" ;
VAL_ 555 SRR_r_ctaWarningReqRight 0 "NO_WARNING" 2 " WARNING_LEVEL2" ;
VAL_ 555 SRR_r_bsdLCAWarningReqRight 0 "NO_WARNING" 1 "WARNING_LEVEL1" 2 " WARNING_LEVEL2" ;
VAL_ 555 SRR_r_displayInfo 0 "NO_DISPLAY" 1 "BSDLCA_ON" 2 "BSDLCA_OFF" 3 "CTA_ON" 4 "CTA_OFF" 5 "TRAILER_MODE_BSD_LCA_NOT_AVAILABLE" 6 "TRAILER_MODE_CTA_NOT_AVAILABLE" 7 "BSDLCA_CTA_ERROR" 8 "BSDLCA_CTA_BLINDNESS" 9 "DOW_ON" 10 " DOW_OFF" ;
VAL_ 555 SRR_r_bsdLCASts 0 "OFF" 1 "ON" 3 " INVALID" ;
VAL_ 555 SRR_r_ctaSts 0 "OFF" 1 "ON" 3 "INVALID" ;
VAL_ 555 SRR_r_dowSts 0 "OFF" 1 "ON" 3 "INVALID" ;
VAL_ 555 SRR_r_ctaWarningReqLeft 0 "NO_WARNING" 2 " WARNING_LEVEL2" ;
VAL_ 555 SRR_r_bsdLCAWarningReqLeft 0 "NO_WARNING" 1 "WARNING_LEVEL1" 2 " WARNING_LEVEL2" ;
VAL_ 555 SRR_R_DOWFrontLeftDoorWarn 0 "NO_WARNING" 1 "WARNING_LEVEL1" 2 " WARNING_LEVEL2" ;
VAL_ 555 SRR_R_DOWRearLeftDoorWarn 0 "NO_WARNING" 1 "WARNING_LEVEL1" 2 " WARNING_LEVEL2" ;
VAL_ 555 SRR_R_DOWFrontRightDoorWarn 0 "NO_WARNING" 1 "WARNING_LEVEL1" 2 " WARNING_LEVEL2" ;
VAL_ 555 SRR_R_DOWRearRightDoorWarn 0 "NO_WARNING" 1 "WARNING_LEVEL1" 2 " WARNING_LEVEL2" ;
VAL_ 896 acu_warningLampStatus 0 "OFF" 1 "ON" 2 " FLASH" ;
VAL_ 896 acu_crashOutputStatusValid 0 "INVALID" 1 " VALID" ;
VAL_ 896 acu_crashOutputStatus 0 "NO_CRASH" 1 " CRASH" ;
VAL_ 896 acu_driverSeatBeltStatus 0 "UNTIED" 1 " TIED" ;
VAL_ 896 acu_driverSeatBeltStatusValid 0 "INVALID" 1 " VALID" ;
VAL_ 896 acu_passengerSeatBeltStatus 0 "UNTIED" 1 " TIED" ;
VAL_ 896 acu_passengerSeatBeltStatusValid 0 "INVALID" 1 " VALID" ;
VAL_ 859 APA_voice_reminder 0 "NO Req" 1 "parking space found" 2 "start" 3 "Completed Sucessfully" 4 "takeover" 5 "brake" 6 "suspend" 7 "attention" ;
VAL_ 859 APA_textinfo 0 "无提示" 1 "ACC on，APA temporarily unavailable" 2 "APA fault" 3 " APA restriction" ;
VAL_ 859 APA_FinishReason 0 "Invaild" 1 "PlanningFault" 2 "SystemErr" 3 "AbortByParkTimeout" 4 "AbortBySuspendTimeout" 5 "AbortBySuspendTimesOverLimit" 6 "AbortBySearchSpeedOverLimit" 7 "AbortByParkTimesOverLimit" 8 "AbortByAvmButton" 9 "AbortByParkTimesOverLimit" 10 "AbortByParkOutSpaceLimited" 11 "AbortByParkOutSpaceEmpty" 12 "AbortByAccOn" 13 "AbortByDTCInternalError" 14 "AbortByDTCExternalError" 15 "AbortByEscSystemError" 16 "AbortByEpsSystemError" 17 "AbortByVcuSystemError" 18 "AbortByEpbSystemError" 19 "AbortByGuidenceSpeedOverLimit" 20 "AbortByAccPedalIntervention" 21 "AbortByGearIntervention" 22 "AbortByUser" 23 "AbortByEscActive" 24 "AbortByEpbIntervention" 25 "AbortByVcuNotWorking" 26 "AbortBySteeringIntervention" 27 "AbortByRadarError" 28 "AbortByCameraError" 29 "AbortByCanEmergencyBrkNodesErr" 30 "AbortByEpsRecoverFault" 31 "AbortByCanComfortBrkNodesErr" 32 "AbortByMcuVoltageError" 33 "AbortByMcuHandshakeFail" 34 "AbortByApaAbnormalReq" 35 "AbortByEpsLowPriority" 36 "AbortByEpsRecoverFault" 37 "HandshakeFailForBrakepedal" 38 "Finishing" ;
VAL_ 1032 ivi_currentRoadType 0 "Expressway" 1 "NationalHighway" 2 "ProvincialHighway" 3 "CountyHighway" 4 "TownshipRoad" 5 "ViliageRoad" 6 "CityExpressway" 7 "UrbanMajorRoad" 8 "SecondaryRoad" 9 "GeneralRoad" 10 "NonnavigationalRoad" 11 "reserved" 12 "reserved" 13 "reserved" 14 "reserved" 15 "INVALID" ;
VAL_ 1032 ivi_NAVIcameraspeedLimitvalueVal 0 "Valid" 1 "InValid" ;
VAL_ 1032 ivi_NAVIspeedLimitvalueValid 0 "Valid" 1 "InValid" ;
VAL_ 1032 ivi_NAVItype 0 "GPS NAVI" 1 "simulate NAVI 模拟导航" 2 "cruise 巡航" 3 " RESERVE" ;
VAL_ 1032 ivi_NAVIcameraspeedLimitvalue 0 "No Display" 1 "SPL_5" 2 "SPL_10" 30 "SPL_150" 255 "SPL_CANCELLED" ;
VAL_ 1032 ivi_NAVIspeedLimitvalue 0 "No Display" 1 "SPL_5" 2 "SPL_10" 30 "SPL_150" 255 "SPL_CANCELLED" ;
VAL_ 1032 ivi_NAVIStaus 0 "EXIST" 1 "NO EXIST" ;
VAL_ 1032 IVI_VehicleRepairModeReq 0 "NO_REQUEST" 1 "OFF" 2 "ON" 3 " INVALID" ;
VAL_ 1032 IVI_VehicleRepairModeSts 0 "INACTIVE" 1 "OFF" 2 "ON" 3 " INVALID" ;
VAL_ 1032 IVI_UserGearFb 0 "NO_REQUEST" 1 "No" 2 "Yes" 3 "Reserved" ;
VAL_ 1032 IVI_CarSearchSts 0 "Allow" 1 "PermissionUnauthorized" 2 "PrivacyUnauthorized" 3 "Reserved" 15 " Invalid" ;
VAL_ 1032 IVI_CarSearchControl 0 "Inactive" 1 "OFF" 2 "ON" 3 " Invalid" ;
VAL_ 1032 IVI_UserClass 0 "Guest" 1 "Family" 2 "CarOwner" 3 " Reserved" ;
VAL_ 1032 ivi_languageSet2 0 "SIMPLIFIED_CHINESE" 1 "ENGLISH" 2 "法语" 3 "德语" 4 "西班牙语" 5 "阿拉伯语" 6 "波斯语" 7 "俄语" 8 "土耳其语" 9 "韩语" 10 "意大利语" 11 "挪威语" 12 "荷兰语" 13 "瑞典语" 14 "希伯来语" 15 "葡萄牙语" 16 "捷克语" 17 "斯洛文尼亚语" 18 "克罗地亚语" 255 " NO_COMMAND" ;
VAL_ 230 IVI_CH0_CH1_VOL_STEP 0 "音量等级0~100" 100 "预留" ;
VAL_ 230 IVI_CH2_VOL_STEP 0 "音量等级0~100" 100 "预留" ;
VAL_ 230 IVI_CH3_VOL_STEP 0 "音量等级0~100" 100 "预留" ;
VAL_ 230 IVI_CH4_VOL_STEP 0 "音量等级0~100" 100 "预留" ;
VAL_ 230 IVI_CH5_VOL_STEP 0 "音量等级0~100" 100 "预留" ;
VAL_ 230 IVI_CH6_VOL_STEP 0 "音量等级0~100" 100 "预留" ;
VAL_ 230 IVI_CH7_VOL_STEP 0 "no request" 1 "低" 2 "中" 3 "高" ;
VAL_ 230 IVI_CH0_CH1_MUTE 0 "解除静音" 1 "静音" ;
VAL_ 230 IVI_CH2_MUTE 0 "解除静音" 1 "静音" ;
VAL_ 230 IVI_CH3_MUTE 0 "解除静音" 1 "静音" ;
VAL_ 230 IVI_CH4_MUTE 0 "解除静音" 1 "静音" ;
VAL_ 230 IVI_CH5_MUTE 0 "解除静音" 1 "静音" ;
VAL_ 230 IVI_CH6_MUTE 0 "解除静音" 1 "静音" ;
VAL_ 230 IVI_CH7_MUTE 0 "解除静音" 1 "静音" ;
VAL_ 230 IVI_CH8_MUTE 0 "解除静音" 1 "静音" ;
VAL_ 230 IVI_CH9_MUTE 0 "解除静音" 1 "静音" ;
VAL_ 230 IVI_CH10_CH15_MUTE 0 "解除静音" 1 "静音" ;
VAL_ 231 IVI_CH8_VOL_STEP 0 "no request" 1 "低" 2 "中" 3 "高" 4 "预留" ;
VAL_ 231 IVI_CH9_VOL_STEP 0 "no request" 1 "低" 2 "中" 3 "高" 4 "预留" ;
VAL_ 231 IVI_CH10_CH15_VOL_STEP 0 "no request" 1 "低" 2 "中" 3 "高" 4 "预留" ;
VAL_ 231 IVI_CH0_CH1_OMP_STEP 0 "音量等级0~100" 100 "预留" ;
VAL_ 233 IVI_SOUND_FADE 0 "未激活" 1 "前后衰减增益等级-6~6" 14 "预留" ;
VAL_ 233 IVI_SOUND_BAL 0 "未激活" 1 "左右平衡增益等级-6~6" 14 "预留" ;
VAL_ 233 IVI_ATMOS_MOD_TYPE 0 "主驾模式" 1 "全车均衡" 2 "后排模式" 3 "音乐剧场" 4 "经典流行" 5 "演唱会模式" 6 "至臻模式" 7 "预留" 15 "   KTV模式" ;
VAL_ 233 IVI_VOL_SPEED_SW 0 "关闭" 1 "打开" ;
VAL_ 233 IVI_ESE_MOD_SW 0 "关闭" 1 "打开" ;
VAL_ 233 IVI_ESE_MOD_TYPE 0 "未激活" 1 "ESE1" 2 "ESE2" 3 "ESE3" 4 "ESE4" 5 "ESE5" 6 "预留" ;
VAL_ 233 IVI_ESE_VOL 0 "低" 1 "中" 2 "高" 3 "预留" ;
VAL_ 233 IVI_PED_ALARM 0 "关闭" 1 "Alarm sound1" 2 "Alarm sound2" 3 "Alarm sound3" 4 "Alarm sound4" 5 "Alarm sound5" 6 "预留" ;
VAL_ 233 IVI_UNLOCK_SW 0 "关闭" 1 "打开" ;
VAL_ 233 IVI_LOCK_SW 0 "关闭" 1 "打开" ;
VAL_ 233 IVI_OMP_Switch 0 "关闭" 1 "打开" ;
VAL_ 233 IVI_HRS_MODE_TYPE 0 "关闭" 1 "半开" 2 "全开" 3 "预留" ;
VAL_ 233 IVI_ECALL_STATUS 0 "NO REQUEST" 1 "通话中" 2 "未通话" 3 "INVALID" ;
VAL_ 234 IVI_GEQ_GAIN_BAND_1 0 "未激活" 1 "GEQ子频段增益等级-6~6" 14 "预留" ;
VAL_ 234 IVI_GEQ_GAIN_BAND_2 0 "未激活" 1 "GEQ子频段增益等级-6~6" 14 "预留" ;
VAL_ 234 IVI_GEQ_GAIN_BAND_3 0 "未激活" 1 "GEQ子频段增益等级-6~6" 14 "预留" ;
VAL_ 234 IVI_GEQ_GAIN_BAND_4 0 "未激活" 1 "GEQ子频段增益等级-6~6" 14 "预留" ;
VAL_ 234 IVI_GEQ_GAIN_BAND_5 0 "未激活" 1 "GEQ子频段增益等级-6~6" 14 "预留" ;
VAL_ 234 IVI_GEQ_GAIN_BAND_6 0 "未激活" 1 "GEQ子频段增益等级-6~6" 14 "预留" ;
VAL_ 234 IVI_GEQ_GAIN_BAND_7 0 "未激活" 1 "GEQ子频段增益等级-6~6" 14 "预留" ;
VAL_ 992 EPA_CH0_STS 0 "正常" 1 "短路GND" 2 "短路VCC" 3 "开路" ;
VAL_ 992 EPA_CH1_STS 0 "正常" 1 "短路GND" 2 "短路VCC" 3 "开路" ;
VAL_ 992 EPA_CH2_STS 0 "正常" 1 "短路GND" 2 "短路VCC" 3 "开路" ;
VAL_ 992 EPA_CH3_STS 0 "正常" 1 "短路GND" 2 "短路VCC" 3 "开路" ;
VAL_ 992 EPA_CH4_STS 0 "正常" 1 "短路GND" 2 "短路VCC" 3 "开路" ;
VAL_ 992 EPA_CH5_STS 0 "正常" 1 "短路GND" 2 "短路VCC" 3 "开路" ;
VAL_ 992 EPA_CH6_STS 0 "正常" 1 "短路GND" 2 "短路VCC" 3 "开路" ;
VAL_ 992 EPA_CH7_STS 0 "正常" 1 "短路GND" 2 "短路VCC" 3 "开路" ;
VAL_ 992 EPA_CH8_STS 0 "正常" 1 "短路GND" 2 "短路VCC" 3 "开路" ;
VAL_ 992 EPA_CH9_STS 0 "正常" 1 "短路GND" 2 "短路VCC" 3 "开路" ;
VAL_ 992 EPA_CH10_STS 0 "正常" 1 "短路GND" 2 "短路VCC" 3 "开路" ;
VAL_ 992 EPA_CH11_STS 0 "正常" 1 "短路GND" 2 "短路VCC" 3 "开路" ;
VAL_ 992 EPA_CH12_STS 0 "正常" 1 "短路GND" 2 "短路VCC" 3 "开路" ;
VAL_ 992 EPA_CH13_STS 0 "正常" 1 "短路GND" 2 "短路VCC" 3 "开路" ;
VAL_ 992 EPA_CH14_STS 0 "正常" 1 "短路GND" 2 "短路VCC" 3 "开路" ;
VAL_ 992 EPA_CH15_STS 0 "正常" 1 "短路GND" 2 "短路VCC" 3 "开路" ;
VAL_ 992 EPA_CH16_STS 0 "正常" 1 "短路GND" 2 "短路VCC" 3 "开路" ;
VAL_ 992 EPA_CH17_STS 0 "正常" 1 "短路GND" 2 "短路VCC" 3 "开路" ;
VAL_ 992 EPA_CH18_STS 0 "正常" 1 "短路GND" 2 "短路VCC" 3 "开路" ;
VAL_ 992 EPA_CH19_STS 0 "正常" 1 "短路GND" 2 "短路VCC" 3 "开路" ;
VAL_ 992 EPA_CH20_STS 0 "正常" 1 "短路GND" 2 "短路VCC" 3 "开路" ;
VAL_ 992 EPA_CH21_STS 0 "正常" 1 "短路GND" 2 "短路VCC" 3 "开路" ;
VAL_ 992 EPA_CH22_STS 0 "正常" 1 "短路GND" 2 "短路VCC" 3 "开路" ;
VAL_ 992 EPA_CH23_STS 0 "正常" 1 "短路GND" 2 "短路VCC" 3 "开路" ;
VAL_ 992 EPA_WORK_STS 0 "无效" 1 "正常" 2 "故障A" 3 "故障B" 4 "预留" ;
VAL_ 992 EPA_A2B_STS 0 "无效" 1 "正常" 2 "故障" 3 "预留" ;
VAL_ 225 EPA_CH0_CH1_VOL_STEP_STS 0 "音量等级0~100" 100 "预留" ;
VAL_ 225 EPA_CH2_VOL_STEP_STS 0 "音量等级0~100" 100 "预留" ;
VAL_ 225 EPA_CH3_VOL_STEP_STS 0 "音量等级0~100" 100 "预留" ;
VAL_ 225 EPA_CH4_VOL_STEP_STS 0 "音量等级0~100" 100 "预留" ;
VAL_ 225 EPA_CH5_VOL_STEP_STS 0 "音量等级0~100" 100 "预留" ;
VAL_ 225 EPA_CH6_VOL_STEP_STS 0 "音量等级0~100" 100 "预留" ;
VAL_ 225 EPA_CH7_VOL_STEP_STS 0 "no request" 1 "低" 2 "中" 3 "高" ;
VAL_ 225 EPA_CH0_CH1_MUTE_STS 0 "解除静音" 1 "静音" ;
VAL_ 225 EPA_CH2_MUTE_STS 0 "解除静音" 1 "静音" ;
VAL_ 225 EPA_CH3_MUTE_STS 0 "解除静音" 1 "静音" ;
VAL_ 225 EPA_CH4_MUTE_STS 0 "解除静音" 1 "静音" ;
VAL_ 225 EPA_CH5_MUTE_STS 0 "解除静音" 1 "静音" ;
VAL_ 225 EPA_CH6_MUTE_STS 0 "解除静音" 1 "静音" ;
VAL_ 225 EPA_CH7_MUTE_STS 0 "解除静音" 1 "静音" ;
VAL_ 225 EPA_CH8_MUTE_STS 0 "解除静音" 1 "静音" ;
VAL_ 225 EPA_CH9_MUTE_STS 0 "解除静音" 1 "静音" ;
VAL_ 225 EPA_CH10_CH15_MUTE_STS 0 "解除静音" 1 "静音" ;
VAL_ 226 EPA_CH8_VOL_STEP_STS 0 "no request" 1 "低" 2 "中" 3 "高" 4 "预留" ;
VAL_ 226 EPA_CH9_VOL_STEP_STS 0 "no request" 1 "低" 2 "中" 3 "高" 4 "预留" ;
VAL_ 226 EPA_CH10_CH15_VOL_STEP_STS 0 "no request" 1 "低" 2 "中" 3 "高" 4 "预留" ;
VAL_ 226 EPA_CH0_CH1_OMP_STEP_STS 0 "音量等级0~100" 100 "预留" ;
VAL_ 228 EPA_SOUND_FADE_STATUS 0 "未激活" 1 "前后衰减增益等级-6~6" 14 "预留" ;
VAL_ 228 EPA_SOUND_BAL_STATUS 0 "未激活" 1 "左右平衡增益等级-6~6" 14 "预留" ;
VAL_ 228 EPA_ATMOS_MOD_TYPE_STATUS 0 "主驾模式" 1 "全车均衡" 2 "后排模式" 3 "音乐剧场" 4 "经典流行" 5 "演唱会模式" 6 "至臻模式" 7 "预留" 15 "   KTV模式" ;
VAL_ 228 EPA_VOL_SPEED_SW_STATUS 0 "关闭" 1 "打开" ;
VAL_ 228 EPA_PED_ALARM_STATUS 0 "关闭" 1 "Alarm sound1" 2 "Alarm sound2" 3 "Alarm sound3" 4 "Alarm sound4" 5 "Alarm sound5" 6 "预留" ;
VAL_ 228 EPA_ESE_MOD_TYPE_STATUS 0 "关闭" 1 "ESE1" 2 "ESE2" 3 "ESE3" 4 "ESE4" 5 "ESE5" 6 "预留" ;
VAL_ 228 EPA_ESE_VOL_STATUS 0 "低" 1 "中" 2 "高" 3 "预留" ;
VAL_ 228 EPA_UNLOCK_SW_STATUS 0 "关闭" 1 "打开" ;
VAL_ 228 EPA_LOCK_SW_STATUS 0 "关闭" 1 "打开" ;
VAL_ 228 EPA_HRS_MODE_TYPE_STATUS 0 "关闭" 1 "半开" 2 "全开" 3 "预留" ;
VAL_ 228 EPA_OMP_Switch_STATUS 0 "关闭" 1 "打开" ;
VAL_ 228 EPA_ESE_MOD_SW_STATUS 0 "关闭" 1 "打开" ;
VAL_ 227 EPA_GEQ_GAIN_BAND_1 0 "未激活" 1 "GEQ子频段增益等级-6~6" 14 "预留" ;
VAL_ 227 EPA_GEQ_GAIN_BAND_2 0 "未激活" 1 "GEQ子频段增益等级-6~6" 14 "预留" ;
VAL_ 227 EPA_GEQ_GAIN_BAND_3 0 "未激活" 1 "GEQ子频段增益等级-6~6" 14 "预留" ;
VAL_ 227 EPA_GEQ_GAIN_BAND_4 0 "未激活" 1 "GEQ子频段增益等级-6~6" 14 "预留" ;
VAL_ 227 EPA_GEQ_GAIN_BAND_5 0 "未激活" 1 "GEQ子频段增益等级-6~6" 14 "预留" ;
VAL_ 227 EPA_GEQ_GAIN_BAND_6 0 "未激活" 1 "GEQ子频段增益等级-6~6" 14 "预留" ;
VAL_ 227 EPA_GEQ_GAIN_BAND_7 0 "未激活" 1 "GEQ子频段增益等级-6~6" 14 "预留" ;
VAL_ 839 BLE_approachingUnlockFedb 0 "RESERVED" 1 "ACTIVE" 2 "INACTIVE" 3 " INVALID" ;
VAL_ 839 BLE_awayLockFeedback 0 "RESERVED" 1 "ACTIVE" 2 "INACTIVE" 3 " INVALID" ;
VAL_ 839 BLE_RPAmodeReq 0 "NO_REQUEST" 1 "OFF" 2 "ON" 3 " INVALID" ;
VAL_ 950 ac_systemOnOffSts 0 "OFF" 1 " ON" ;
VAL_ 950 ac_autoStatus 0 "OFF" 1 " ON" ;
VAL_ 950 ac_acStatus 0 "OFF" 1 " ON" ;
VAL_ 950 ac_driverTempC 0 "low" 30 "HI" ;
VAL_ 950 ac_dualStatus 0 "SINGLE" 1 " DUAL" ;
VAL_ 950 ac_frontDefrostStatus1 0 "OFF" 1 " FRONT_DEFROST" ;
VAL_ 950 ac_recircStatus 0 "EXTERNAL" 1 " INTERNAL" ;
VAL_ 950 ac_passengerTempC 0 "low" 30 "HI" ;
VAL_ 950 ac_blowerLvAUTOStatus 0 "AUTO" 1 " NOT AUTO" ;
VAL_ 950 ac_modeAUTOStatus 0 "AUTO" 1 " NOT AUTO" ;
VAL_ 950 ac_modeStatus 0 "FACE" 1 "FACE_AND_FOOT" 2 "FOOT" 3 "FOOT_AND_DEFROST" 4 "DEFROST" 5 "reserve" 6 "reserve" 7 " INVALID" ;
VAL_ 950 ac_blowerLvStatus 0 "OFF" 1 "SPEED_1" 2 "SPEED_2" 3 "SPEED_3" 4 "SPEED_4" 5 "SPEED_5" 6 "SPEED_6" 7 " SPEED_7" ;
VAL_ 950 AC_InigentizePurificationStSwitc 0 "Inactive" 1 "OFF" 2 "ON" 3 " Invalid" ;
VAL_ 950 AC_InigentizePurificationSt 0 "智能净化中" 1 " 智能净化完成" ;
VAL_ 950 AC_InsidePM25Level 0 "LEVEL 10至35 μg/m3" 1 "LEVEL 235至75 μg/m3" 2 "LEVEL 375至115 μg/m3" 3 "LEVEL 4115至150 μg/m3" 4 "LEVEL 5 150至250 μg/m3" 5 "LEVEL 6大于250 μg/m3" 6 "reserved" 7 " Invalid" ;
VAL_ 950 AC_PM25InCar 0 "0" 1 "1" 2 "2" 3 "3按1递增" 999 "999" 1000 "1000" 1001 "至0x3FEreserved" 1023 "invalid" ;
VAL_ 950 AC_PurificationQuikReq 0 "NO Request" 1 "Request" ;
VAL_ 950 AC_AutoDrySts 0 "Initial" 1 "OFF" 2 "ON" 3 " Invalid" ;
VAL_ 673 bcm_cruiseSW 0 "Not Pressed" 1 " Pressed" ;
VAL_ 673 bcm_cruiseSWValid 0 "Valid" 1 " Invalid" ;
VAL_ 673 BCM_cruiseHeadway_increase_KeySt 0 "Not Pressed" 1 "Pressed" ;
VAL_ 673 BCM_cruiseHeadway_increase__0000 0 "Valid" 1 "Invalid" ;
VAL_ 673 bcm_hoodSts 0 "CLOSE" 1 " OPEN" ;
VAL_ 673 bcm_hazardLightSwSts 0 "OFF" 1 " ON" ;
VAL_ 673 bcm_leftTurnLampSwSts 0 "OFF" 1 " ON" ;
VAL_ 673 bcm_leftTurnLampSts 0 "OFF" 1 "ON" 2 "Reserved" 3 "Front Left Turn Light Failure" 4 "Rear Left Fender Turn Light Failure" 5 " Rear Left Trunk Turn Light Failure " ;
VAL_ 673 bcm_rightTurnLampSts 0 "OFF" 1 "ON" 2 "Reserved" 3 "Front Right Turn Light Failure" 4 "Rear Right Fender Turn Light Failure" 5 " Rear Right Trunk Turn Light Failure " ;
VAL_ 673 bcm_rightTurnLampSwSts 0 "OFF" 1 " ON" ;
VAL_ 673 bcm_doorFLSts 0 "CLOSE" 1 " OPEN" ;
VAL_ 673 bcm_doorFRSts 0 "CLOSE" 1 " OPEN" ;
VAL_ 673 bcm_doorRLSts 0 "CLOSE" 1 " OPEN" ;
VAL_ 673 bcm_doorRRSts 0 "CLOSE" 1 " OPEN" ;
VAL_ 673 bcm_doorFLLockSts 0 "LOCK" 1 " UNLOCK" ;
VAL_ 673 bcm_antiTheftSts 0 "DISARMED" 1 "ARMED" 2 "ALARM" 3 " HALF_ARMED" ;
VAL_ 673 bcm_FuelTapStatus 0 "CLOSED" 1 "OPEN" 2 "TAPERROR" 3 " None" ;
VAL_ 673 bcm_frontWiperSts 0 "STOP" 1 "LOW_SPEED" 2 "HIGH_SPEED" 3 "INTERRUPT_RESERVED" 4 "WASH" 5 "RESERVED" 6 "SWTICH_FAILURE_RESERVED" 7 " INVALID" ;
VAL_ 673 bcm_chrgCapSts 0 "CLOSE" 1 " OPEN" ;
VAL_ 673 BCM_cruiseHeadway_decrease_KeySt 0 "Not Pressed" 1 "Pressed" ;
VAL_ 673 BCM_cruiseHeadway_decrease__0000 0 "Valid" 1 "Invalid" ;
VAL_ 673 bcm_driverSeatDetectSts 0 "NOT_DETECTED" 1 " DETECTED" ;
VAL_ 961 bcm_rearMirrorSts 0 "FOLD" 1 " UNFOLD" ;
VAL_ 961 BCM_HighBeamModel 0 "Auto-off" 1 "Auto-on is not activated" 2 " Auto-on is activated" ;
VAL_ 961 bcm_windowLFSts 0 "WINDOW_CLOSED" 1 "WINDOW_OPENED" 2 "STOPPED" 3 "AUTO_UP_MOVING" 4 "MANUAL_UP_MOVING" 5 "AUTO_DOWN_MOVING" 6 "MANUAL_DOWN_MOVING" 7 " INVALID" ;
VAL_ 961 bcm_windowRFSts 0 "WINDOW_CLOSED" 1 "WINDOW_OPENED" 2 "STOPPED" 3 "AUTO_UP_MOVING" 4 "MANUAL_UP_MOVING" 5 "AUTO_DOWN_MOVING" 6 "MANUAL_DOWN_MOVING" 7 " INVALID" ;
VAL_ 961 bcm_windowLRSts 0 "WINDOW_CLOSED" 1 "WINDOW_OPENED" 2 "STOPPED" 3 "AUTO_UP_MOVING" 4 "MANUAL_UP_MOVING" 5 "AUTO_DOWN_MOVING" 6 "MANUAL_DOWN_MOVING" 7 " INVALID" ;
VAL_ 961 bcm_windowRRSts 0 "WINDOW_CLOSED" 1 "WINDOW_OPENED" 2 "STOPPED" 3 "AUTO_UP_MOVING" 4 "MANUAL_UP_MOVING" 5 "AUTO_DOWN_MOVING" 6 "MANUAL_DOWN_MOVING" 7 " INVALID" ;
VAL_ 961 bcm_rearDefrostSts 0 "OFF" 1 " ON" ;
VAL_ 961 BCM_AutoRainWiperstatus 0 "ON" 1 " OFF" ;
VAL_ 961 bcm_rainSensorError 0 "NORMAL" 1 " FAULT" ;
VAL_ 961 bcm_positionLampSts 0 "OFF" 1 " ON" ;
VAL_ 961 bcm_autoLampSwSts 0 "NON_AUTO" 1 " AUTO" ;
VAL_ 961 bcm_lowBeamSts 0 "OFF" 1 "ON" 3 "LOWBEAMFAULT" ;
VAL_ 961 bcm_highBeamSts 0 "OFF" 1 "ON" 3 " HIGHBEAMFAULT" ;
VAL_ 961 bcm_rearFogLampSts 0 "OFF" 1 " ON" ;
VAL_ 961 bcm_lightSensorError 0 "NORMAL" 1 " FAULT" ;
VAL_ 961 bcm_roofLampSts 0 "OFF" 1 " ON" ;
VAL_ 962 BCM_NozzleHeatingSt 0 "OFF" 1 " ON" ;
VAL_ 962 BCM_VolOrSOCLowAlarm 0 "INACTIVE" 1 "LOW" 2 "Normal" 3 " INVALID" ;
VAL_ 962 BCM_ModeFB 0 "Reserved" 1 "OFF" 2 "ON" 3 " INVALID" ;
VAL_ 962 BCM_FLWINOpenDegree 0 "NO_REQUEST" 1 "0%全关" 2 "1%" 3 "2%_按1%递增" 100 "99%" 101 "100%全开" 102 "stop" 103 "至0x7E reserve" 127 "Invalid" ;
VAL_ 962 BCM_FRWINOpenDegree 0 "NO_REQUEST" 1 "0%全关" 2 "1%" 3 "2%_按1%递增" 100 "99%" 101 "100%全开" 102 "stop" 103 "至0x7E reserve" 127 "Invalid" ;
VAL_ 962 BCM_PresentONState 0 "NO present ON" 1 "Standy" 2 "Driving" 3 "Invaild" ;
VAL_ 962 BCM_lockSoundSetfedb 0 "INACTIVE" 1 "HORN" 2 "VSP" 3 "OFF" ;
VAL_ 962 BCM_brakeLightSts 0 "OFF" 1 " ON" ;
VAL_ 962 BCM_RLWINOpenDegree 0 "NO_REQUEST" 1 "0%全关" 2 "1%" 3 "2%_按1%递增" 100 "99%" 101 "100%全开" 102 "stop" 103 "至0x7E reserve" 127 "Invalid" ;
VAL_ 962 BCM_RRWINOpenDegree 0 "NO_REQUEST" 1 "0%全关" 2 "1%" 3 "2%_按1%递增" 100 "99%" 101 "100%全开" 102 "stop" 103 "至0x7E reserve" 127 "Invalid" ;
VAL_ 962 BCM_NFC_PS_KeyReq 0 "NO_REQUEST" 1 "REQUEST" 2 "INVALID" ;
VAL_ 962 BCM_PowerState 0 "Normal OFF" 1 "Present_ON" 2 "NOPresent_ON" 3 "BOOT_ON" 4 "Reserve" 5 "Reserve" 6 "Reserve" 7 "Invalid" ;
VAL_ 1041 bcm_tpmsLFStatus 0 "INITIAL_TPMS" 1 "NORMAL_TPMS" 2 "SYS_ERROR胎压传感器丢失" 3 "LOW_BATT_VOL低电量" 4 "HIGH_TYRE_PRESSURE高压" 5 "HIGH_TEMP高温" 6 "RAPID_LEAK快速漏气预留" 7 " LOW_TYRE_PRESSURE低压" ;
VAL_ 1041 bcm_tyreLFPressure 0 "0.9" 1 "1" 255 " invalid" ;
VAL_ 1041 bcm_tyreLFTemp 0 "<-40" 1 "-40" 255 " invalid" ;
VAL_ 1041 bcm_tpmsRFStatus 0 "INITIAL_TPMS" 1 "NORMAL_TPMS" 2 "SYS_ERROR胎压传感器丢失" 3 "LOW_BATT_VOL低电量" 4 "HIGH_TYRE_PRESSURE高压" 5 "HIGH_TEMP高温" 6 "RAPID_LEAK快速漏气预留" 7 " LOW_TYRE_PRESSURE低压" ;
VAL_ 1041 bcm_tyreRFPressure 0 "0.9" 1 "1" 255 " invalid" ;
VAL_ 1041 bcm_tyreRFTemp 0 "<-40" 1 "-40" 255 " invalid" ;
VAL_ 1057 bcm_tpmsLRStatus 0 "INITIAL_TPMS" 1 "NORMAL_TPMS" 2 "SYS_ERROR胎压传感器丢失" 3 "LOW_BATT_VOL低电量" 4 "HIGH_TYRE_PRESSURE高压" 5 "HIGH_TEMP高温" 6 "RAPID_LEAK快速漏气预留" 7 " LOW_TYRE_PRESSURE低压" ;
VAL_ 1057 bcm_tyreLRPressure 0 "0.9" 1 "1" 255 " invalid" ;
VAL_ 1057 bcm_tyreLRTemp 0 "<-40" 1 "-40" 255 " invalid" ;
VAL_ 1057 bcm_tpmsRRStatus 0 "INITIAL_TPMS" 1 "NORMAL_TPMS" 2 "SYS_ERROR胎压传感器丢失" 3 "LOW_BATT_VOL低电量" 4 "HIGH_TYRE_PRESSURE高压" 5 "HIGH_TEMP高温" 6 "RAPID_LEAK快速漏气预留" 7 " LOW_TYRE_PRESSURE低压" ;
VAL_ 1057 bcm_tyreRRPressure 0 "0.9" 1 "1" 255 " invalid" ;
VAL_ 1057 bcm_tyreRRTemp 0 "<-40" 1 "-40" 255 " invalid" ;
VAL_ 705 bcm_pepsPowerMode 0 "DEFAULT_POWERMODE" 1 "OFF_POWERMODE" 2 "ON_POWERMODE" 3 "RESERVE_POWERMODE" 4 "RESERVE_POWERMODE1" 5 "RESERVE_POWERMODE2" 6 "RESERVE_POWERMODE3" 7 " INVALID_POWERMODE" ;
VAL_ 705 bcm_ChildSafetyLockRRSts 0 "LOCK" 1 " UNLOCK" ;
VAL_ 705 bcm_pepsKeyNotInCarInd 0 "NO_WARNING" 1 " WARNING" ;
VAL_ 705 bcm_pepsKeySerchFailInd 0 "NO_WARNING" 1 " WARNING" ;
VAL_ 705 bcm_pepsKeyCloserInd 0 "NO_WARNING" 1 " WARNING" ;
VAL_ 705 bcm_pepsFobLowBatWarning 0 "NO_WARNING" 1 " WARNING" ;
VAL_ 705 bcm_pepsPowerRelayErrWarning 0 "NO_WARNING" 1 " WARNING" ;
VAL_ 705 bcm_ChildSafetyLockSts 0 "LOCK" 1 " UNLOCK" ;
VAL_ 705 bcm_esclUnlockFailWarning 0 "NO_WARNING" 1 " WARNING" ;
VAL_ 705 bcm_esclLockFailWarning 0 "NO_WARNING" 1 " WARNING" ;
VAL_ 705 bcm_remoteMode 0 "INVALID" 1 "NORMAL" 2 " REMOTE" ;
VAL_ 705 bcm_DriveDoorUnlockFedb 0 "RESERVED" 1 "ACTIVE" 2 "INACTIVE" 3 " INVALID" ;
VAL_ 705 bcm_pepsKeyInCarInd 0 "NO_WARNING" 1 " WARNING" ;
VAL_ 705 bcm_lowBeamFailureInd 0 "NO_WARNING" 1 " WARNING" ;
VAL_ 705 bcm_frontLeftTurnLightFailInd 0 "NO_WARNING" 1 " WARNING" ;
VAL_ 705 bcm_frontRightTurnLightFailInd 0 "NO_WARNING" 1 " WARNING" ;
VAL_ 705 bcm_rearFixLeftTurnLightFailInd 0 "NO_WARNING" 1 " WARNING" ;
VAL_ 705 bcm_rearMoveLeftTurnLightFailInd 0 "NO_WARNING" 1 " WARNING" ;
VAL_ 705 bcm_rearFixRightTurnLightFailInd 0 "NO_WARNING" 1 " WARNING" ;
VAL_ 705 bcm_rearMoRightTurnLightFailInd 0 "NO_WARNING" 1 " WARNING" ;
VAL_ 705 bcm_ChildSafetyLockRLSts 0 "LOCK" 1 " UNLOCK" ;
VAL_ 705 bcm_doorTopSwitchSts 0 "INACTIVE" 1 "OFF" 2 "ON" 3 " INVALID" ;
VAL_ 705 bcm_approachingUnlockFedb 0 "RESERVED" 1 "ACTIVE" 2 "INACTIVE" 3 " INVALID" ;
VAL_ 705 bcm_followMeHomeFedb 0 "RESERVED" 1 "OFF" 2 "15S" 3 "30S" 4 "60S" 7 " INVALID" ;
VAL_ 705 bcm_awayLockFeedback 0 "RESERVED" 1 "ACTIVE" 2 "INACTIVE" 3 " INVALID" ;
VAL_ 705 bcm_MirrorAutoFoldUnfoldStatus 0 "NORequest" 1 "OFF" 2 "ON" 3 " INVALID" ;
VAL_ 977 BCM_apm_PassengeLockStatus 0 "Invalid" 1 "Valid" ;
VAL_ 977 BCM_positionLightOnReq 0 "OFF Request" 1 " ON Request" ;
VAL_ 977 BCM_LockCloseWinFedb 0 "INACTIVE" 1 "ON" 2 "OFF" 3 " INVALID" ;
VAL_ 1475 BCM_FRWINReason 0 "Normal" 1 "not learned （未学习）" 2 "防夹" 3 "内部故障" 4 "电机输出故障" 5 "Other" 6 "至0xF Reserved" ;
VAL_ 1475 BCM_FLWINReason 0 "Normal" 1 "not learned （未学习）" 2 "防夹" 3 "内部故障" 4 "电机输出故障" 5 "Other" 6 "至0xF Reserved" ;
VAL_ 1475 BCM_RLWINReason 0 "Normal" 1 "not learned （未学习）" 2 "防夹" 3 "内部故障" 4 "电机输出故障" 5 "Other" 6 "至0xF Reserved" ;
VAL_ 1475 BCM_RRWINReason 0 "Normal" 1 "not learned （未学习）" 2 "防夹" 3 "内部故障" 4 "电机输出故障" 5 "Other" 6 "至0xF Reserved" ;
VAL_ 150 IVI_danceOnOffSet 0 "NORequest" 1 "灯舞效果1" 2 "灯舞效果2" 3 "灯舞效果3" 4 "灯舞效果4" 5 "灯舞效果5" 6 "OFF" 7 "reserve" ;
VAL_ 150 IVI_unlockAnimatSet 0 "NORequest" 1 "OFF" 2 "ON" 3 " INVALID" ;
VAL_ 150 IVI_lockAnimatSet 0 "NORequest" 1 "OFF" 2 "ON" 3 " INVALID" ;
VAL_ 150 IVI_FLWINOpenDegreeReq 0 "NO_REQUEST" 1 "0%全关" 2 "1%" 3 "2%_按1%递增" 100 "99%" 101 "100%全开" 102 "STOP" 103 "至0x7E reserve" 127 "Invalid" ;
VAL_ 150 IVI_FRWINOpenDegreeReq 0 "NO_REQUEST" 1 "0%全关" 2 "1%" 3 "2%_按1%递增" 100 "99%" 101 "100%全开" 102 "STOP" 103 "至0x7E reserve" 127 "Invalid" ;
VAL_ 150 IVI_RLWINOpenDegreeReq 0 "NO_REQUEST" 1 "0%全关" 2 "1%" 3 "2%_按1%递增" 100 "99%" 101 "100%全开" 102 "STOP" 103 "至0x7E reserve" 127 "Invalid" ;
VAL_ 150 IVI_RRWINOpenDegreeReq 0 "NO_REQUEST" 1 "0%全关" 2 "1%" 3 "2%_按1%递增" 100 "99%" 101 "100%全开" 102 "STOP" 103 "至0x7E reserve" 127 "Invalid" ;
VAL_ 150 IVI_BCMlockSoundSet 0 "NO REQUEST" 1 "HORN" 2 "VSP" 3 " INVALID" ;
VAL_ 150 IVI_LockCloseWinSet 0 "No Comond" 1 "On" 2 "Off" 3 " Invalid" ;
VAL_ 150 IVI_SterringWheelHeatSw 0 "No Command" 1 "LEVEL_1" 2 "LEVEL_2" 3 "LEVEL_3" 4 "OFF" 5 "Reserved" 6 "Reserved" 7 "Invalid" ;
VAL_ 810 LCU_danceOnOffSet_FB 0 "OFF" 1 "灯舞效果1" 2 "灯舞效果2" 3 "灯舞效果3" 4 "灯舞效果4" 5 "灯舞效果5" 6 "INVALID" 7 "条件不满足IVI提示" ;
VAL_ 810 LCU_unlockAnimatSet_FB 0 "INACTIVE" 1 "OFF" 2 "ON" 3 " INVALID" ;
VAL_ 810 LCU_lockAnimatSet_FB 0 "INACTIVE" 1 "OFF" 2 "ON" 3 " INVALID" ;
VAL_ 916 PLG_antipinchWarning 0 "NO_WARNING" 1 " WARNING" ;
VAL_ 916 PLG_tailgateOpenFailWarning 0 "NO_WARNING" 1 " WARNING" ;
VAL_ 916 PLG_tailgateCloseFailWarning 0 "NO_WARNING" 1 " WARNING" ;
VAL_ 916 PLG_tailgateOpenSts 0 "CLOSED" 1 "OPENED" 2 "CLOSING" 3 "OPENING" 4 "STOPPED" 5 "CLOSED_NOT_COMPLETELY" 6 "LOCKING上锁过程" 7 " UNLOCKING等待解锁状态" ;
VAL_ 916 PLG_antiPlayWarning 0 "NO_WARNING" 1 " WARNING" ;
VAL_ 916 PLG_tailgateOpenSts2 0 "CLOSED" 1 "OPENED" 2 "CLOSING" 3 "OPENING" 4 "STOPPED" 5 "CLOSED_NOT_COMPLETELY" 6 "LOCKING上锁过程" 7 "UNLOCKING等待解锁状态" 8 "强制开启区域" 9 "至0xFreserve" ;
VAL_ 916 PLG_tailgateFaultReason 0 "Normal" 1 "背门故障" 2 "antipinch" 3 "antiPlay" 4 "热保护（及电流保护）" 5 "背门限制开闭（车速不满足）" 6 "背门限制开闭（电压不满足）" 7 "背门限制开闭（门锁状态不满足）" 8 "背门限制开闭（超时、超速、 hall 不一致）" 9 "Other" 10 "~0xFReserved" ;
VAL_ 981 DSM_drSeatMassSts 0 "OFF" 1 "LEVEL_1" 2 "LEVEL_2" 3 "LEVEL_3" 4 "LEVEL_4" 5 "LEVEL_5" 6 "RESERVED" 7 " ERROR" ;
VAL_ 981 DSM_passSeatMassSts 0 "OFF" 1 "LEVEL_1" 2 "LEVEL_2" 3 "LEVEL_3" 4 "LEVEL_4" 5 "LEVEL_5" 6 "RESERVED" 7 " ERROR" ;
VAL_ 981 DSM_easyEntryStatus 0 "OFF" 1 " ON" ;
VAL_ 981 DSM_MirrorAutoTurnDownStatus 0 "OFF" 1 " ON" ;
VAL_ 981 DSM_DrMassgIntenSt 0 "OFF" 1 "Weak Intensity" 2 "Normal Intensity" 3 " High Intensity" ;
VAL_ 981 DSM_PsgMassgIntenSt 0 "OFF" 1 "Weak Intensity" 2 "Normal Intensity" 3 " High Intensity" ;
VAL_ 981 DSM_DSMStatustOutput 0 "INVALID" 1 "FAILED" 2 "SUCCESSED" 3 " RESERVED" ;
VAL_ 981 DSM_MemoryPosition 0 "NOT_MEMORYPOSITION" 1 "1 POSITION" 2 "2 POSITION" 3 "3 POSITION" 4 "4 POSITION" 5 "5 POSITION" 6 "LAST POSITION" 7 " RESERVED" ;
VAL_ 981 DSM_DevSupportSts 0 "NOT_DETECTED" 1 " DETECTED" ;
VAL_ 981 DSM_DevLinkSts 0 "NOT_DETECTED" 1 " DETECTED" ;
VAL_ 981 DSM_DevType 0 "NOT_DETECTED" 1 "type1" 2 "type2" 3 "type3" 4 "type4" 5 "type5" 6 "type6" 7 " type7" ;
VAL_ 981 DSM_ChargeSts 0 "no request" 1 "ON" 2 "OFF" 3 "invalid" ;
VAL_ 982 PSM_PassSeatRouteSetFB 0 "NO_REQUEST" 1 "0%" 2 "1%" 3 "2%_按1%递增" 100 "99%" 101 "100%" 102 "至0x7E reserve" 127 "Invalid" ;
VAL_ 982 PSM_PassSeatbackrestSetFB 0 "NO_REQUEST" 1 "0%" 2 "1%" 3 "2%_按1%递增" 100 "99%" 101 "100%" 102 "至0x7E reserve" 127 "Invalid" ;
VAL_ 982 PSM_PassSeatCushionSetFB 0 "NO_REQUEST" 1 "0%" 2 "1%" 3 "2%_按1%递增" 100 "99%" 101 "100%" 102 "至0x7E reserve" 127 "Invalid" ;
VAL_ 982 PSM_PassSeatCushionAngleSetFB 0 "NO_REQUEST" 1 "0%" 2 "1%" 3 "2%_按1%递增" 100 "99%" 101 "100%" 102 "至0x7E reserve" 127 "Invalid" ;
VAL_ 982 PSM_LimitbackrestAngle 0 "no request" 1 "limit" 2 "reserved" 3 " reserved" ;
VAL_ 980 DSM_drSeatRouteSetFB 0 "NO_REQUEST" 1 "0%" 2 "1%" 3 "2%_按1%递增" 100 "99%" 101 "100%" 102 "至0x7E reserve" 127 "Invalid" ;
VAL_ 980 DSM_drSeatbackrestSetFB 0 "NO_REQUEST" 1 "0%" 2 "1%" 3 "2%_按1%递增" 100 "99%" 101 "100%" 102 "至0x7E reserve" 127 "Invalid" ;
VAL_ 980 DSM_drSeatCushionSetFB 0 "NO_REQUEST" 1 "0%" 2 "1%" 3 "2%_按1%递增" 100 "99%" 101 "100%" 102 "至0x7E reserve" 127 "Invalid" ;
VAL_ 980 DSM_drSeatCushionAngleSetFB 0 "NO_REQUEST" 1 "0%" 2 "1%" 3 "2%_按1%递增" 100 "99%" 101 "100%" 102 "至0x7E reserve" 127 "Invalid" ;
VAL_ 980 DSM_LmirrorUDSetFB 0 "NO REQUEST" 1 "0%" 2 "5%" 3 "10%" 4 "15%" 5 "20%" 6 "25%" 7 "30%" 8 "35%" 9 "40%" 10 "45%" 11 "50%" 12 "55%" 13 "60%" 14 "65%" 15 "70%" 16 "75%" 17 "80%" 18 "85%" 19 "90%" 20 "95%" 21 "100%" 31 "INVALID" ;
VAL_ 980 DSM_LimitbackrestAngle 0 "no request" 1 "limit" 2 "reserved" 3 " reserved" ;
VAL_ 980 DSM_LmirrorLRSetFB 0 "NO REQUEST" 1 "0%" 2 "5%" 3 "10%" 4 "15%" 5 "20%" 6 "25%" 7 "30%" 8 "35%" 9 "40%" 10 "45%" 11 "50%" 12 "55%" 13 "60%" 14 "65%" 15 "70%" 16 "75%" 17 "80%" 18 "85%" 19 "90%" 20 "95%" 21 "100%" 31 "INVALID" ;
VAL_ 980 DSM_RmirrorUDSetFB 0 "NO REQUEST" 1 "0%" 2 "5%" 3 "10%" 4 "15%" 5 "20%" 6 "25%" 7 "30%" 8 "35%" 9 "40%" 10 "45%" 11 "50%" 12 "55%" 13 "60%" 14 "65%" 15 "70%" 16 "75%" 17 "80%" 18 "85%" 19 "90%" 20 "95%" 21 "100%" 31 "INVALID" ;
VAL_ 980 DSM_RmirrorLRSetFB 0 "NO REQUEST" 1 "0%" 2 "5%" 3 "10%" 4 "15%" 5 "20%" 6 "25%" 7 "30%" 8 "35%" 9 "40%" 10 "45%" 11 "50%" 12 "55%" 13 "60%" 14 "65%" 15 "70%" 16 "75%" 17 "80%" 18 "85%" 19 "90%" 20 "95%" 21 "100%" 31 "INVALID" ;
VAL_ 980 DSM_drSeatMovementSts 0 "NOT Operate" 1 "AUTO Stop" 2 "Manual Stop" 3 "AUTO" 4 "Manual" 5 "Reserved" 6 "Reserved" 7 " Invalid" ;
VAL_ 792 PSM_drSeatHeatSts 0 "OFF" 1 "LEVEL_1" 2 "LEVEL_2" 3 "LEVEL_3" 7 " ERROR" ;
VAL_ 792 PSM_drSeatVentSts 0 "OFF" 1 "LEVEL_1" 2 "LEVEL_2" 3 "LEVEL_3" 7 " ERROR" ;
VAL_ 792 PSM_passSeatHeatSts 0 "OFF" 1 "LEVEL_1" 2 "LEVEL_2" 3 "LEVEL_3" 7 " ERROR" ;
VAL_ 792 PSM_passSeatVentSts 0 "OFF" 1 "LEVEL_1" 2 "LEVEL_2" 3 "LEVEL_3" 7 " ERROR" ;
VAL_ 792 PSM_DevSupportSts 0 "NOT_DETECTED" 1 " DETECTED" ;
VAL_ 792 PSM_DevLinkSts 0 "NOT_DETECTED" 1 " DETECTED" ;
VAL_ 792 PSM_DevType 0 "NOT_DETECTED" 1 "type1" 2 "type2" 3 "type3" 4 "type4" 5 "type5" 6 "type6" 7 " type7" ;
VAL_ 792 PSM_ChargeSts 0 "no request" 1 "ON" 2 "OFF" 3 "invalid" ;
VAL_ 794 LRSM_LSeatHeatSts 0 "OFF" 1 "LEVEL_1" 2 "LEVEL_2" 3 "LEVEL_3" 7 " ERROR" ;
VAL_ 794 LRSM_RSeatHeatSts 0 "OFF" 1 "LEVEL_1" 2 "LEVEL_2" 3 "LEVEL_3" 7 " ERROR" ;
VAL_ 168 tbox_remotePetModeReq 0 "NO_REQUEST" 1 "OFF" 2 "ON" 3 " INVALID" ;
VAL_ 168 TBOX_SentryReq 0 "NO_REQUEST" 1 "OFF" 2 "ON" 3 " INVALID" ;
VAL_ 168 TBOX_TakeVideoPosReq 0 "NO_REQUEST" 1 "Front" 2 "Rear" 3 "Left" 4 "Right" 5 "INCAR" 6 "OFF" 7 "INVALID" ;
VAL_ 168 TBOX_TakePhotoReq 0 "NO_REQUEST" 1 "OUTCAR" 2 "Rear_reserved" 3 "Left_reserved" 4 "Right_reserved" 5 "INCAR" 6 "OFF" 7 "INVALID" ;
VAL_ 168 TBOX_SentryTimeSet 0 "Inactive" 1 "0.5" 2 "1" 3 "1.5" 4 "2" 5 "2.5" 6 "3" 7 "3.5" 8 "4" 9 "4.5" 10 "5" 11 "5.5" 12 "6" 13 "6.5" 14 "7" 15 "7.5" 16 "8" 17 "至0x1Ereserve" 31 "INVALID" ;
VAL_ 168 TBOX_CarSearchReq 0 "NO_REQUEST" 1 "OFF" 2 "ON" 3 " INVALID" ;
VAL_ 117 ivi_childLockCtrl 0 "NO_COMMAND" 1 "UNLOCK" 2 "LOCK" 3 " INVALID" ;
VAL_ 117 ivi_centralLockCtrl 0 "NO_COMMAND" 1 "UNLOCK" 2 "LOCK" 3 " INVALID" ;
VAL_ 117 ivi_fuelPortCapOpenCtrl 0 "NO_COMMAND_FUELPORT" 1 "OPEN_FUELPORT" 2 "RESERVED_FUELPORT" 3 " INVALID" ;
VAL_ 117 ivi_lowBeamOnOffCtrl 0 "NO_COMMAND" 1 "OFF" 2 "ON" 3 " INVALID" ;
VAL_ 117 ivi_v2vChrgOnOffSet 0 "NO Request" 1 "OFF" 2 "ON" 3 " INVALID" ;
VAL_ 117 ivi_obcDschrgOnOffSet 0 "NO_COMMAND" 1 "OFF" 2 "ON" 3 " INVALID" ;
VAL_ 117 ivi_rearFogLampOnOffCtrl 0 "NO_COMMAND" 1 "OFF" 2 "ON" 3 " INVALID" ;
VAL_ 117 ivi_chrgPortCapOpenCtrl 0 "NO_COMMAND" 1 "OPEN" 2 "RESERVED" 3 " INVALID" ;
VAL_ 117 ivi_NormalHvOffRequest 0 "NO_REQUEST" 1 " REQUEST" ;
VAL_ 117 ivi_tailgateCtrl 0 "NO_COMMAND" 1 "CLOSE" 2 "OPEN" 3 " STOP" ;
VAL_ 117 ivi_MirrorSw 0 "SW_NOT_PRESSED" 1 "SW_PRESSED" 2 "RESERVED" 3 " INVALID" ;
VAL_ 117 ivi_rearDefrostCtrl 0 "NO_COMMAND" 1 "OFF" 2 "ON" 3 " INVALID" ;
VAL_ 117 ivi_MaxFuelConsumptionSW 0 "NO_COMMAND" 1 "OFF" 2 "ON" 3 " INVALID" ;
VAL_ 117 ivi_MaxFuelConsumptionModeSW 0 "NO_COMMAND" 1 "High Speed" 2 "Low Speed" 3 " INVALID" ;
VAL_ 117 ivi_v2vChrgOptCurntSet 0 "NO Request" 1 "20" 2 "30" 3 "40" 4 "50" 5 "60" 6 "70" 7 "80" 8 "90" 9 "100" 10 "Reserved" 11 "Reserved" 12 "Reserved" 13 "Reserved" 14 "Reserved" 15 "INVALID" ;
VAL_ 117 ivi_approachingUnlockCtrl 0 "NO_COMMAND" 1 "ACTIVE" 2 "INACTIVE" 3 " INVALID" ;
VAL_ 117 ivi_awayLockCtrl 0 "NO_COMMAND" 1 "ACTIVE" 2 "INACTIVE" 3 " INVALID" ;
VAL_ 117 ivi_wipperMaintModeCtrl 0 "NO_REQUEST" 1 " REQUESTED" ;
VAL_ 117 ivi_modememory 0 "NO REQUEST" 1 "No_Memory" 2 "Memory" 3 " INVALID" ;
VAL_ 149 IVI_NozzleHeatingSw 0 "NORequest" 1 "OFF" 2 "ON" 3 " INVALID" ;
VAL_ 149 IVI_OneKeyModeSet 0 "NO Request" 1 "Factory Pattern" 2 "Best Experience" 3 "INVALID" ;
VAL_ 149 ivi_limitmodeset 0 "NO Req" 1 "Manual" 2 "Intelligent" 3 " INVALID" ;
VAL_ 149 ivi_doorTopSwitch 0 "NO_COMMAND" 1 "OFF" 2 "ON" 3 " INVALID" ;
VAL_ 149 ivi_rvMirrorAutoTurnDownSet 0 "NO_COMMAND" 1 "OFF" 2 "ON" 3 " INVALID" ;
VAL_ 149 ivi_followMeHomeSet 0 "NO_COMMAND" 1 "OFF" 2 "15S" 3 "30S" 4 "60S" 7 " INVALID" ;
VAL_ 149 ivi_WinLFCtrlRqst 0 "NO_Req" 1 "AUTO_UP_MOVING" 2 "MANUAL_UP_MOVING" 3 "AUTO_DOWN_MOVING" 4 "MANUAL_DOWN_MOVING" 5 "WinLFCtrlRqst" 6 "Reserved" 7 " Invalid" ;
VAL_ 149 ivi_WinRFCtrlRqst 0 "NO_Req" 1 "AUTO_UP_MOVING" 2 "MANUAL_UP_MOVING" 3 "AUTO_DOWN_MOVING" 4 "MANUAL_DOWN_MOVING" 5 "WinRFCtrlRqst" 6 "Reserved" 7 " Invalid" ;
VAL_ 149 ivi_WinLRCtrlRqst 0 "NO_Req" 1 "AUTO_UP_MOVING" 2 "MANUAL_UP_MOVING" 3 "AUTO_DOWN_MOVING" 4 "MANUAL_DOWN_MOVING" 5 "WinLRCtrlRqst" 6 "Reserved" 7 " Invalid" ;
VAL_ 149 ivi_WinRRCtrlRqst 0 "NO_Req" 1 "AUTO_UP_MOVING" 2 "MANUAL_UP_MOVING" 3 "AUTO_DOWN_MOVING" 4 "MANUAL_DOWN_MOVING" 5 "WinRRCtrlRqst" 6 "Reserved" 7 " Invalid" ;
VAL_ 149 ivi_childLockRLCtrl 0 "NO_COMMAND" 1 "UNLOCK" 2 "LOCK" 3 " INVALID" ;
VAL_ 149 ivi_childLockRRCtrl 0 "NO_COMMAND" 1 "UNLOCK" 2 "LOCK" 3 " INVALID" ;
VAL_ 149 ivi_DriveDoorUnlockCtrl 0 "NO_COMMAND" 1 "ACTIVE" 2 "INACTIVE" 3 " INVALID" ;
VAL_ 149 IVI_AutoDrySet 0 "NO  Request" 1 "OFF" 2 "ON" 3 " INVALID" ;
VAL_ 165 ivi_TripAReset 0 "NO_REQUEST" 1 " REQUEST" ;
VAL_ 165 ivi_TripBReset 0 "NO_REQUEST" 1 " REQUEST" ;
VAL_ 165 ivi_VehicleModeSet 0 "NORequest" 1 "Electric" 2 "AUTO" 3 "Fuel" 4 "EV_ONLY" 5 "Reserved" 6 "Reserved" 7 "Reserved" ;
VAL_ 165 ivi_RegenModeSet 0 "NO REQ" 1 "OFF_ Reserved" 2 "LOW _reserve" 3 "NORMAL" 4 "Strong Recovery" 5 "Exstrong" 6 "Reserved" 7 "Reserved" ;
VAL_ 165 ivi_traveModeSet 0 "NO  Request" 1 "WET" 2 "SNOW" 3 "OFF" ;
VAL_ 165 ivi_ChargeControl 0 "NO_REQUEST" 1 "CANCEL" 2 "ENABLE" 3 "INVALID" ;
VAL_ 165 ivi_ParkingChargeReq 0 "NORequest" 1 "OPEN" 2 "CLOSE" 3 "Reserved" ;
VAL_ 165 ivi_TowModeSet 0 "NO_REQUEST" 1 "TOW_MODE_OFF" 2 "TOW_MODE_ON" 3 "Reserved" ;
VAL_ 165 ivi_maxChrgSocSet 255 " INVALID" ;
VAL_ 165 ivi_chargeFormSet 0 "NO_REQUEST" 1 "IMMEDIATE_CHARGE" 2 "TIMING_CHARGE" 3 "RESERVE_CHRGFORM1" ;
VAL_ 165 ivi_ParkingChargeModeSet 0 "NORequest" 1 "LOW" 2 "MIDDLE" 3 "HIGH" ;
VAL_ 165 ivi_chargeSetValid 0 "INVALID" 1 " VALID" ;
VAL_ 165 ivi_ChargeEndTimeHour 0 "NORequest" 1 "1" 2 "2" 3 "3" 4 "4" 5 "5" 6 "6" 7 "7" 8 "8" 9 "9" 10 "10" 11 "11" 12 "12" 13 "13" 14 "14" 15 "15" 16 "16" 17 "17" 18 "18" 19 "19" 20 "20" 21 "21" 22 "22" 23 "23" 31 " INVALID" ;
VAL_ 165 ivi_ChargeStartTimeHour 0 "NORequest" 1 "1" 2 "2" 3 "3" 4 "4" 5 "5" 6 "6" 7 "7" 8 "8" 9 "9" 10 "10" 11 "11" 12 "12" 13 "13" 14 "14" 15 "15" 16 "16" 17 "17" 18 "18" 19 "19" 20 "20" 21 "21" 22 "22" 23 "23" 31 " INVALID" ;
VAL_ 165 ivi_ChargeEndTimeMinute 63 " INVALID" ;
VAL_ 165 ivi_ChargeStartTimeMinute 63 " INVALID" ;
VAL_ 165 ivi_ResetCurrentTrip 0 "NO_REQUEST" 1 " REQUEST" ;
VAL_ 165 IVI_AcFullChargeToWarmSet 0 "NO_REQUEST" 1 "OFF" 2 "ON" 3 "INVALID" ;
VAL_ 165 ivi_ChargeEndTimeValid 0 "No Req" 1 "Set End Time" 2 "Not Set End Time" 3 "Invalid" ;
VAL_ 165 ivi_ChargeStartTimeValid 0 "INVALID" 1 " VALID" ;
VAL_ 165 ivi_driveModeSet 0 "NORequest" 1 "ECO" 2 "COMFORT" 3 "SPORT" 4 "FREEDOM_reserve" 5 "ACCELERATE" 6 "RESERVED" 7 " Invalid" ;
VAL_ 101 ivi_epsModeSet 0 "NORequest" 1 "reserve" 2 "COMFORT" 3 " SPORT" ;
VAL_ 101 ivi_escOffSw 0 "No Request" 1 "ON" 2 "OFF" 3 " INVALID" ;
VAL_ 101 ivi_hdcOnOffSet 0 "No Request" 1 "ON" 2 "OFF" 3 " INVALID" ;
VAL_ 101 ivi_aebOnOffSet 0 "No Request" 1 "OFF" 2 "ON" 3 " INVALID" ;
VAL_ 101 ivi_iBModeSet 0 "NORequest" 1 "COMFORT" 2 "SPORT" 3 " INVALID" ;
VAL_ 101 ivi_lcaBsdOnOffSet 0 "NORequest" 1 "OFF" 2 "ON" 3 " INVALID" ;
VAL_ 101 ivi_rctaOnOffSetReserved 0 "NORequest" 1 "OFF" 2 "ON" 3 " INVALID" ;
VAL_ 101 ivi_dowOnOffSet 0 "NORequest" 1 "OFF" 2 "ON" 3 " INVALID" ;
VAL_ 101 ivi_StartRevSOCSet 0 "NORequest" 1 "20%~0x3D:80%" 63 " INVALID" ;
VAL_ 101 ivi_hmaOnOffSet 0 "NORequest" 1 "OFF" 2 "ON" 3 " INVALID" ;
VAL_ 101 ivi_speedLimitOnOffSet 0 "NORequest" 1 "OFF" 2 "Display" 3 " Display+Voice" ;
VAL_ 101 IVI_HVDownRepairMode 0 "NORequest" 1 "OFF" 2 "ON" 3 " INVALID" ;
VAL_ 101 ivi_ASCHeightModeSelected 0 "NORequest" 1 "RESERVED" 2 "HIGH MODE" 3 "NORMAL MODE" 4 "LOW MODE" 5 "RESERVED" 6 "RESERVED" 7 " RESERVED" ;
VAL_ 101 ivi_ASCMoveModeControl 0 "NORequest" 1 "COMFORT" 2 "AUTO" 3 " MOVEMENT" ;
VAL_ 101 ivi_laneAssistFuncSet 0 "No Req" 1 "OFF" 2 "LDW" 3 "LDW+RDP" 4 "Reserved" 5 "Reserved" 6 "Reserved" 7 "Invalid" ;
VAL_ 101 ivi_lasWarningModeSelection 0 "No Req" 1 "Only Vision" 2 "Vision+Voice" 3 "Reserved" 4 "Reserved" 5 "Reserved" 6 "Reserved" 7 "Invalid" ;
VAL_ 101 ivi_EmergencyHvOffRequestReserve 0 "NO_REQUEST" 1 " REQUEST" ;
VAL_ 101 ivi_ExhibitionModeCtrl 0 "No_request" 1 "OFF" 2 "ON" 3 " Reserved" ;
VAL_ 101 ivi_remainningMilModeSet 0 "NORequest" 1 "WLTC" 2 "SUM" 3 "CLTC" 4 "NEDC" ;
VAL_ 101 ivi_avhOnOffSet 0 "No Request" 1 "ON" 2 "OFF" 3 " INVALID" ;
VAL_ 101 ivi_pcwOnOffSet 0 "NORequest" 1 "OFF" 2 "ON" 3 " INVALID" ;
VAL_ 101 ivi_TJAFuncSet 0 "NORequest" 1 "OFF" 2 "ON" 3 " INVALID" ;
VAL_ 101 IVI_autododgeOnOffSet 0 "NORequest" 1 "OFF" 2 "ON" 3 " INVALID" ;
VAL_ 101 ivi_trailerModeOnOffSet 0 "NORequest" 1 "TRAILER_MODE_OFF" 2 "TRAILER_MODE_ON" 3 " RESERVED" ;
VAL_ 101 ivi_esc_epbButtonRelease 0 "NO REQUEST" 1 " REQUEST" ;
VAL_ 101 IVI_ApaOnOffReq 0 "No press" 1 " APA ON/OFF" ;
VAL_ 152 IVI_drSeatRouteSet 0 "NO_REQUEST" 1 "0%" 2 "1%" 3 "2%_按1%递增" 100 "99%" 101 "100%" 127 "Invalid" ;
VAL_ 152 IVI_drSeatbackrestSet 0 "NO_REQUEST" 1 "0%" 2 "1%" 3 "2%_按1%递增" 100 "99%" 101 "100%" 127 "Invalid" ;
VAL_ 152 IVI_drSeatCushionSet 0 "NO_REQUEST" 1 "0%" 2 "1%" 3 "2%_按1%递增" 100 "99%" 101 "100%" 127 "Invalid" ;
VAL_ 152 IVI_drSeatCushionAngleSet 0 "NO_REQUEST" 1 "0%" 2 "1%" 3 "2%_按1%递增" 100 "99%" 101 "100%" 127 "Invalid" ;
VAL_ 152 IVI_LmirrorUDSet 0 "NO_REQUEST" 1 "0%" 2 "5%" 3 "10%" 4 "15%" 5 "20%" 6 "25%" 7 "30%" 8 "35%" 9 "40%" 10 "45%" 11 "50%" 12 "55%" 13 "60%" 14 "65%" 15 "70%" 16 "75%" 17 "80%" 18 "85%" 19 "90%" 20 "95%" 21 "100%" 31 "INVALID" ;
VAL_ 152 IVI_LmirrorLRSet 0 "NO_REQUEST" 1 "0%" 2 "5%" 3 "10%" 4 "15%" 5 "20%" 6 "25%" 7 "30%" 8 "35%" 9 "40%" 10 "45%" 11 "50%" 12 "55%" 13 "60%" 14 "65%" 15 "70%" 16 "75%" 17 "80%" 18 "85%" 19 "90%" 20 "95%" 21 "100%" 31 "INVALID" ;
VAL_ 152 IVI_RmirrorUDSet 0 "NO_REQUEST" 1 "0%" 2 "5%" 3 "10%" 4 "15%" 5 "20%" 6 "25%" 7 "30%" 8 "35%" 9 "40%" 10 "45%" 11 "50%" 12 "55%" 13 "60%" 14 "65%" 15 "70%" 16 "75%" 17 "80%" 18 "85%" 19 "90%" 20 "95%" 21 "100%" 31 "INVALID" ;
VAL_ 152 IVI_RmirrorLRSet 0 "NO_REQUEST" 1 "0%" 2 "5%" 3 "10%" 4 "15%" 5 "20%" 6 "25%" 7 "30%" 8 "35%" 9 "40%" 10 "45%" 11 "50%" 12 "55%" 13 "60%" 14 "65%" 15 "70%" 16 "75%" 17 "80%" 18 "85%" 19 "90%" 20 "95%" 21 "100%" 31 "INVALID" ;
VAL_ 152 IVI_DSMChargeCtrl 0 "no request" 1 "ON" 2 "OFF" 3 "invalid" ;
VAL_ 147 IVI_PassSeatRouteSet 0 "NO_REQUEST" 1 "0%" 2 "1%" 3 "2%_按1%递增" 100 "99%" 101 "100%" 127 "Invalid" ;
VAL_ 147 IVI_PassSeatbackrestSet 0 "NO_REQUEST" 1 "0%" 2 "1%" 3 "2%_按1%递增" 100 "99%" 101 "100%" 127 "Invalid" ;
VAL_ 147 IVI_PassSeatCushionSet 0 "NO_REQUEST" 1 "0%" 2 "1%" 3 "2%_按1%递增" 100 "99%" 101 "100%" 127 "Invalid" ;
VAL_ 147 IVI_PassSeatCushionAngleSet 0 "NO_REQUEST" 1 "0%" 2 "1%" 3 "2%_按1%递增" 100 "99%" 101 "100%" 127 "Invalid" ;
VAL_ 147 IVI_PSMChargeCtrl 0 "no request" 1 "ON" 2 "OFF" 3 "invalid" ;
VAL_ 151 IVI_ALCThemeModeSet 0 "NO Request" 1 "First_Theme" 2 "Second_Theme" 3 "Third_Theme:单色" 4 "Fourth_Theme:音律随动" 5 "Fifth_Theme车速随动" 6 "Reserved" 15 "Invalid" ;
VAL_ 151 IVI_DOWALCWarnningSet 0 "NORequest" 1 "OFF" 2 "ON" 3 " INVALID" ;
VAL_ 151 IVI_easyEntryALCWarnningSet 0 "NORequest" 1 "OFF" 2 "ON" 3 " INVALID" ;
VAL_ 151 IVI_ALCSwithCtrl 0 "NORequest" 1 "OFF" 2 "ON" 3 " INVALID" ;
VAL_ 151 IVI_BreathFrequency 0 "NORequest" 1 "OFF" 2 "ON" 3 "RESERVED" 4 "RESERVED" 5 "RESERVED" 6 "RESERVED" 7 "INVALID" ;
VAL_ 151 IVI_NavigationTurnSet 0 "NORequest" 1 "OFF" 2 "ON" 3 " INVALID" ;
VAL_ 151 IVI_BSDWarnningSet 0 "NORequest" 1 "OFF" 2 "ON" 3 " INVALID" ;
VAL_ 151 IVI_vehicleWarnningSet 0 "NORequest" 1 "OFF" 2 "ON" 3 " INVALID" ;
VAL_ 151 IVI_BlueToothSet 0 "NORequest" 1 "OFF" 2 "ON" 3 " INVALID" ;
VAL_ 151 IVI_FatigueReminderSet 0 "NORequest" 1 "OFF" 2 "ON" 3 " INVALID" ;
VAL_ 151 ivi_IVIthemeSet 0 "NO_REQUEST" 1 "Day" 2 "Night" 3 " INVALID" ;
VAL_ 151 IVI_driveModeALCctrltset 0 "NORequest" 1 "OFF" 2 "ON" 3 " INVALID" ;
VAL_ 151 IVI_ALCAplLuminance 0 "NO Request" 1 "1-100%" 127 "Invalid" ;
VAL_ 151 IVI_VAP_FragranceCtrlReq 0 "No request" 1 "Close request" 2 "Open request" 3 "Reserved " ;
VAL_ 151 IVI_FragrancePositionSet 0 "No request" 1 "Fragrance Position_1 (位置1的香型)" 2 "Fragrance Position_2 (位置2的香型）" 3 "Fragrance Position_3 (位置3的香型）" ;
VAL_ 151 IVI_FragranceConcentrationSet 0 "Initial value" 1 "Low concentration" 2 "Middle concentration" 3 "High concentration" 4 "Reserved (预留） " ;
VAL_ 151 IVI_ALCAImodeSet 0 "NORequest" 1 "OFF" 2 "ON" 3 " INVALID" ;
VAL_ 151 IVI_ALCTemperatureSwithCtrl 0 "NORequest" 1 "OFF" 2 "ON" 3 " INVALID" ;
VAL_ 151 IVI_ACTempALCReq 0 "NORequest" 1 "UP" 2 "Down" 3 " Invalid" ;
